VERSION ""

NS_ :

BS_:

BU_: Turbocharger OnBoardDataLogger OffBoardDiagnosticTool2 OffBoardDiagnosticTool1 FileServer ParkingBrakeController SeatControl2 FanDriveController SteeringColumnUnit CommunicationUnitRadio CommunicationUnitSatellite CommunicationUnitCellular PropulsionBatteryCharger ChassisController2 ChassisController1 EngineValveControl AuxiliaryHeater2 AuxiliaryHeater1 ClutchUnit RampControl InformationSystem1 SuspensionSystemController2 OilSensor VehicleDynamicStability ExhaustEmissionController TransmissionDisplay2 TransmissionDisplay1 ClimateControl2 WaterPumpController RearAxleSteeringController LightingOperatorControl SeatController1 IgnitionController2 IgnitionController1 TirePressureController CabController2 CabController1 PneumaticSystemController SuspensionSystemController1 HydraulicPumpController EnduranceBrakingSystem RetarderExhaustEngine2 OnBoardDiagnosticUnit HeadwayController RetarderExhaustEngine1 CabDisplay1 ManagementComputer VirtualTerminal OffVehicleGateway PowerTakeOffFront HitchControl AuxiliaryValveControl BodyController TractorTrailerBridge1 StarterSystem ElectricalSystem VehicleSecurity VehicleNavigation AerodynamicControl ElectricalChargingSystem ClimateControl1 TripRecorder InstrumentCluster SuspensionDriveAxle2 SuspensionDriveAxle1 SuspensionSteerAxle SteeringController FuelSystem CruiseControl RetarderDriveline RetarderEngine BrakesDriveAxle2 BrakesDriveAxle1 BrakesSystemController BrakesSteerAxle AxleDrive2 AxleDrive1 AxleSteering PowerTakeOff ShiftConsoleSecondary ShiftConsolePrimary Transmission2 Transmission1 Engine2 Engine1

BO_ 2365479678 ASC1: 8 Vector__XXX
 SG_ SpeedDependantLevelCtrlStatus : 54|2@1+ (1,0) [0|3] "" Vector__XXX
 SG_ MemoryLevel : 60|4@1+ (1,0) [0|15] "" Vector__XXX
 SG_ AllwLvelCtrlDuringBrakingStatus : 52|2@1+ (1,0) [0|3] "" Vector__XXX
 SG_ SspensionCtrlRefusalInformation : 56|4@1+ (1,0) [0|15] "" Vector__XXX
 SG_ SuspensionRemoteCtrl2 : 50|2@1+ (1,0) [0|3] "" Vector__XXX
 SG_ SuspensionRemoteCtrl1 : 48|2@1+ (1,0) [0|3] "" Vector__XXX
 SG_ RearAxleInBumperRange : 42|2@1+ (1,0) [0|3] "" Vector__XXX
 SG_ FrontAxleInBumperRange : 40|2@1+ (1,0) [0|3] "" Vector__XXX
 SG_ DoorRelease : 36|2@1+ (1,0) [0|3] "" Vector__XXX
 SG_ VehicleMotionInhibit : 34|2@1+ (1,0) [0|3] "" Vector__XXX
 SG_ SecurityDevice : 32|2@1+ (1,0) [0|3] "" Vector__XXX
 SG_ LevelCtrlMode : 28|4@1+ (1,0) [0|15] "" Vector__XXX
 SG_ KneelingInformation : 24|4@1+ (1,0) [0|15] "" Vector__XXX
 SG_ LiftingCtrlModeRearAxle : 22|2@1+ (1,0) [0|3] "" Vector__XXX
 SG_ LiftingCtrlModeFrontAxle : 20|2@1+ (1,0) [0|3] "" Vector__XXX
 SG_ LoweringCtrlModeRearAxle : 18|2@1+ (1,0) [0|3] "" Vector__XXX
 SG_ LoweringCtrlModeFrontAxle : 16|2@1+ (1,0) [0|3] "" Vector__XXX
 SG_ AboveNominalLevelRearAxle : 14|2@1+ (1,0) [0|3] "" Vector__XXX
 SG_ AboveNominalLevelFrontAxle : 12|2@1+ (1,0) [0|3] "" Vector__XXX
 SG_ BelowNominalLevelRearAxle : 10|2@1+ (1,0) [0|3] "" Vector__XXX
 SG_ BelowNominalLevelFrontAxle : 8|2@1+ (1,0) [0|3] "" Vector__XXX
 SG_ NominalLevelRearAxle : 4|4@1+ (1,0) [0|15] "" Vector__XXX
 SG_ NominalLevelFrontAxle : 0|4@1+ (1,0) [0|15] "" Vector__XXX
 SG_ LiftAxle2Pos : 46|2@1+ (1,0) [0|3] "" Vector__XXX
 SG_ LiftAxle1Pos : 38|2@1+ (1,0) [0|3] "" Vector__XXX

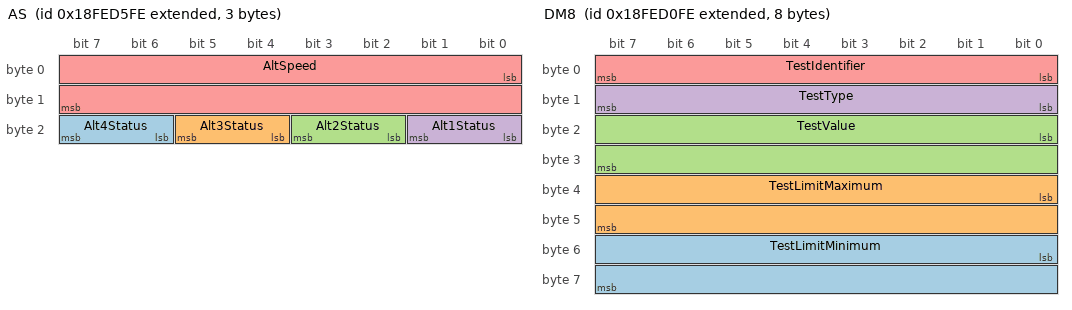
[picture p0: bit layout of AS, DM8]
BO_ 2566837758 AS: 3 Vector__XXX
 SG_ Alt4Status : 22|2@1+ (1,0) [0|3] "" Vector__XXX
 SG_ Alt3Status : 20|2@1+ (1,0) [0|3] "" Vector__XXX
 SG_ Alt2Status : 18|2@1+ (1,0) [0|3] "" Vector__XXX
 SG_ Alt1Status : 16|2@1+ (1,0) [0|3] "" Vector__XXX
 SG_ AltSpeed : 0|16@1+ (0.5,0) [0|32127.5] "rpm" Vector__XXX

BO_ 2633922558 AP: 8 Vector__XXX
 SG_ AuxAbsPressReading : 32|16@1+ (0.5,0) [0|32127.5] "kPa" Vector__XXX
 SG_ AuxGagePressReading1 : 16|16@1+ (0.5,0) [0|32127.5] "kPa" Vector__XXX
 SG_ AuxVacuumPressReading : 0|16@1+ (0.5,0) [0|32127.5] "kPa" Vector__XXX

BO_ 2566775038 AMB2: 8 Vector__XXX
 SG_ SpecificHumidity : 16|16@1+ (0.01,0) [0|642.55] "g/kg" Vector__XXX
 SG_ SolarSensorMax : 8|8@1+ (0.4,0) [0|100] "mW/cm/cm" Vector__XXX
 SG_ SolarIntensityPercent : 0|8@1+ (0.4,0) [0|100] "%" Vector__XXX

BO_ 2566836478 DM8: 8 Vector__XXX
 SG_ TestLimitMinimum : 48|16@1+ (1,0) [0|64255] "" Vector__XXX
 SG_ TestLimitMaximum : 32|16@1+ (1,0) [0|64255] "" Vector__XXX
 SG_ TestValue : 16|16@1+ (1,0) [0|64255] "" Vector__XXX
 SG_ TestType : 8|8@1+ (1,0) [1|64] "" Vector__XXX
 SG_ TestIdentifier : 0|8@1+ (1,0) [1|64] "" Vector__XXX

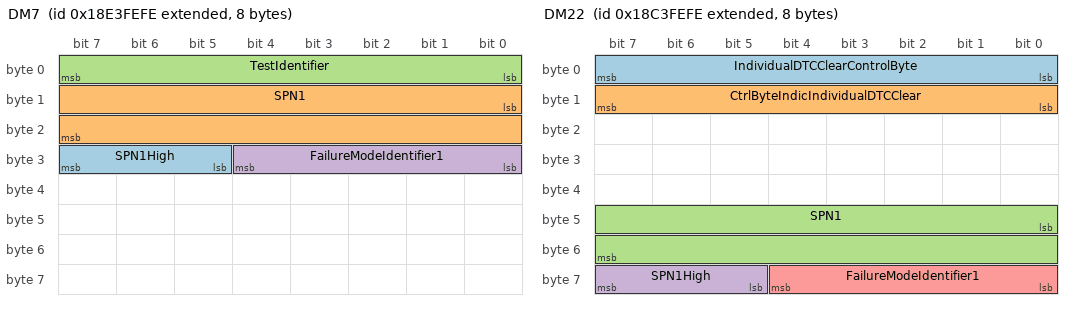
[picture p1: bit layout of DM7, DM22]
BO_ 2565078782 DM7: 8 Vector__XXX
 SG_ SPN1High : 29|3@1+ (1,0) [0|7] "" Vector__XXX
 SG_ SPN1 : 8|16@1+ (1,0) [0|65536] "" Vector__XXX
 SG_ TestIdentifier : 0|8@1+ (1,0) [1|64] "" Vector__XXX
 SG_ FailureModeIdentifier1 : 24|5@1+ (1,0) [0|0] "" Vector__XXX

BO_ 2566835966 DM5: 8 Vector__XXX
 SG_ BoostPressureControlSystemStatus : 57|1@1- (1,0) [0|0] "" Vector__XXX
 SG_ DieselParticulateFilterStatus : 58|1@1- (1,0) [0|0] "" Vector__XXX
 SG_ NOxConvertingCatalystAdsorberSta : 59|1@1- (1,0) [0|0] "" Vector__XXX
 SG_ NMHCConvertingCatalystStatus : 60|1@1- (1,0) [0|0] "" Vector__XXX
 SG_ BoostPressureControlSystemSuppor : 41|1@1- (1,0) [0|0] "" Vector__XXX
 SG_ DieselParticulateFilterSupport : 42|1@1- (1,0) [0|0] "" Vector__XXX
 SG_ NOxConvertingCatalystAdsorberSup : 43|1@1- (1,0) [0|0] "" Vector__XXX
 SG_ NMHCConvertingCatalystSupport : 44|1@1- (1,0) [0|0] "" Vector__XXX
 SG_ MisfireMonitoringSupport : 24|1@1+ (1,0) [0|0] "" Vector__XXX
 SG_ OBDCompliance : 16|8@1+ (1,0) [0|240] "" Vector__XXX
 SG_ PreviouslyActiveTroubleCodes : 8|8@1+ (1,0) [0|240] "" Vector__XXX
 SG_ ActiveTroubleCodes : 0|8@1+ (1,0) [0|240] "" Vector__XXX
 SG_ SecondAirSystemMonStatus : 51|1@1+ (1,0) [0|1] "" Vector__XXX
 SG_ EvaporativeSystemMonStatus : 50|1@1+ (1,0) [0|1] "" Vector__XXX
 SG_ ACSystemRefrigerantMonStatus : 52|1@1+ (1,0) [0|1] "" Vector__XXX
 SG_ OxygenSensorHeaterMonStatus : 54|1@1+ (1,0) [0|1] "" Vector__XXX
 SG_ OxygenSensorMonStatus : 53|1@1+ (1,0) [0|1] "" Vector__XXX
 SG_ EGRSystemMonitoringStatus : 55|1@1+ (1,0) [0|1] "" Vector__XXX
 SG_ CatalystMonStatus : 48|1@1+ (1,0) [0|1] "" Vector__XXX
 SG_ ColdStartAidSystemMonStatus : 56|1@1+ (1,0) [0|1] "" Vector__XXX
 SG_ HeatedCatalystMonStatus : 49|1@1+ (1,0) [0|0] "" Vector__XXX
 SG_ CatalystMonSupp : 32|1@1+ (1,0) [0|1] "" Vector__XXX
 SG_ ColdStartAidSystemMonSupp : 40|1@1+ (1,0) [0|1] "" Vector__XXX
 SG_ HeatedCatalystMonSupp : 33|1@1+ (1,0) [0|0] "" Vector__XXX
 SG_ EvaporativeSystemMonSupp : 34|1@1+ (1,0) [0|1] "" Vector__XXX
 SG_ SecondAirSystemMonSupp : 35|1@1+ (1,0) [0|1] "" Vector__XXX
 SG_ ACSystemRefrigerantMonSupp : 36|1@1+ (1,0) [0|1] "" Vector__XXX
 SG_ OxygenSensorMonSupp : 37|1@1+ (1,0) [0|1] "" Vector__XXX
 SG_ OxygenSensorHeaterMonSupp : 38|1@1+ (1,0) [0|1] "" Vector__XXX
 SG_ EGRSystemMonitoringSupp : 39|1@1+ (1,0) [0|1] "" Vector__XXX
 SG_ MisfireMonitoringStatus : 28|1@1+ (1,0) [0|0] "" Vector__XXX
 SG_ ComprehensiveCompMonStatus : 30|1@1+ (1,0) [0|1] "" Vector__XXX
 SG_ FuelSystemMonitoringStatus : 29|1@1+ (1,0) [0|1] "" Vector__XXX
 SG_ ComprehensiveComponentMonSupp : 26|1@1+ (1,0) [0|0] "" Vector__XXX
 SG_ FuelSystemMonitoringSupport : 25|1@1+ (1,0) [0|1] "" Vector__XXX

BO_ 2566835454 DM3: 0 Vector__XXX

BO_ 2562981630 DM22: 8 Vector__XXX
 SG_ IndividualDTCClearControlByte : 0|8@1+ (1,0) [0|255] "" Vector__XXX
 SG_ CtrlByteIndicIndividualDTCClear : 8|8@1+ (1,0) [0|255] "" Vector__XXX
 SG_ SPN1 : 40|16@1+ (1,0) [0|65536] "" Vector__XXX
 SG_ SPN1High : 61|3@1+ (1,0) [0|7] "" Vector__XXX
 SG_ FailureModeIdentifier1 : 56|5@1+ (1,0) [0|0] "" Vector__XXX

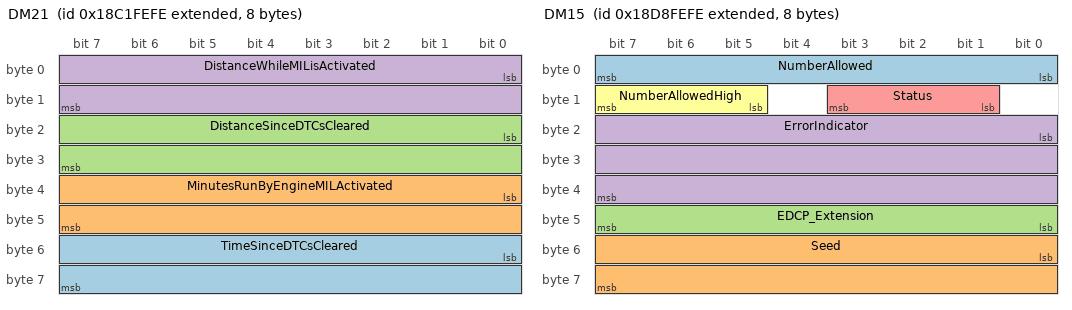
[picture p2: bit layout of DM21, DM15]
BO_ 2562850558 DM21: 8 Vector__XXX
 SG_ TimeSinceDTCsCleared : 48|16@1+ (1,0) [0|64255] "mins" Vector__XXX
 SG_ MinutesRunByEngineMILActivated : 32|16@1+ (1,0) [0|64255] "mins" Vector__XXX
 SG_ DistanceSinceDTCsCleared : 16|16@1+ (1,0) [0|64255] "km" Vector__XXX
 SG_ DistanceWhileMILisActivated : 0|16@1+ (1,0) [0|64255] "km" Vector__XXX

BO_ 2564226814 DM17: 1 Vector__XXX
 SG_ BootLoadData : 0|8@1- (1,0) [0|0] "" Vector__XXX

BO_ 2564292350 DM16: 2 Vector__XXX
 SG_ RawBinaryData : 8|8@1- (1,0) [0|0] "" Vector__XXX
 SG_ NumberOfOccurance : 0|8@1+ (1,0) [0|0] "" Vector__XXX

BO_ 2564357886 DM15: 8 Vector__XXX
 SG_ NumberAllowed : 0|8@1+ (1,0) [0|2047] "" Vector__XXX
 SG_ Seed : 48|16@1+ (1,0) [0|65535] "" Vector__XXX
 SG_ EDCP_Extension : 40|8@1+ (1,0) [0|255] "" Vector__XXX
 SG_ ErrorIndicator : 16|24@1+ (1,0) [0|16777215] "" Vector__XXX
 SG_ Status : 9|3@1+ (1,0) [0|7] "" Vector__XXX
 SG_ NumberAllowedHigh : 13|3@1+ (1,0) [0|7] "" Vector__XXX

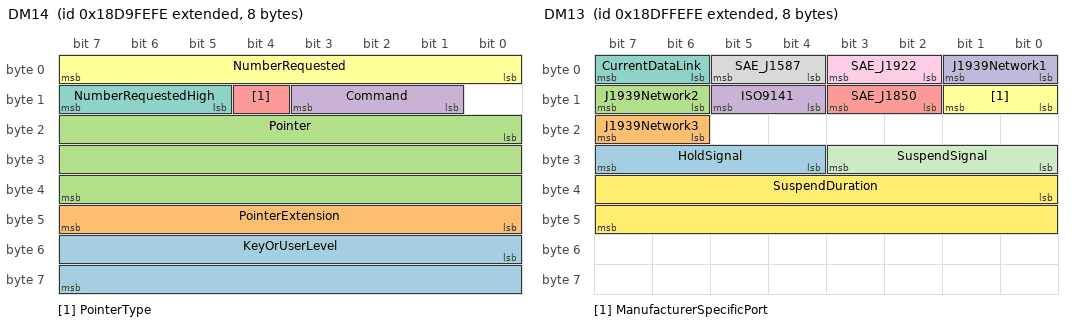
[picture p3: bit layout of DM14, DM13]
BO_ 2564423422 DM14: 8 Vector__XXX
 SG_ KeyOrUserLevel : 48|16@1+ (1,0) [0|65535] "" Vector__XXX
 SG_ PointerExtension : 40|8@1+ (1,0) [0|255] "" Vector__XXX
 SG_ Pointer : 16|24@1+ (1,0) [0|16777215] "" Vector__XXX
 SG_ Command : 9|3@1+ (1,0) [0|7] "" Vector__XXX
 SG_ PointerType : 12|1@1+ (1,0) [0|1] "" Vector__XXX
 SG_ NumberRequested : 0|8@1+ (1,0) [0|2047] "" Vector__XXX
 SG_ NumberRequestedHigh : 13|3@1+ (1,0) [0|7] "" Vector__XXX

BO_ 2564816638 DM13: 8 Vector__XXX
 SG_ HoldSignal : 28|4@1+ (1,0) [0|15] "" Vector__XXX
 SG_ J1939Network3 : 22|2@1+ (1,0) [0|3] "" Vector__XXX
 SG_ J1939Network2 : 14|2@1+ (1,0) [0|3] "" Vector__XXX
 SG_ ISO9141 : 12|2@1+ (1,0) [0|3] "" Vector__XXX
 SG_ SAE_J1850 : 10|2@1+ (1,0) [0|3] "" Vector__XXX
 SG_ ManufacturerSpecificPort : 8|2@1+ (1,0) [0|3] "" Vector__XXX
 SG_ CurrentDataLink : 6|2@1+ (1,0) [0|3] "" Vector__XXX
 SG_ SAE_J1587 : 4|2@1+ (1,0) [0|3] "" Vector__XXX
 SG_ SAE_J1922 : 2|2@1+ (1,0) [0|3] "" Vector__XXX
 SG_ J1939Network1 : 0|2@1+ (1,0) [0|3] "" Vector__XXX
 SG_ SuspendSignal : 24|4@1+ (1,0) [0|15] "" Vector__XXX
 SG_ SuspendDuration : 32|16@1+ (1,0) [0|64255] "sec" Vector__XXX

BO_ 2566837246 DM11: 0 Vector__XXX

BO_ 2566836990 DM10: 8 Vector__XXX
 SG_ TestIdentifierSupported : 0|64@1+ (1,0) [1|1.844674407371E+019] "" Vector__XXX

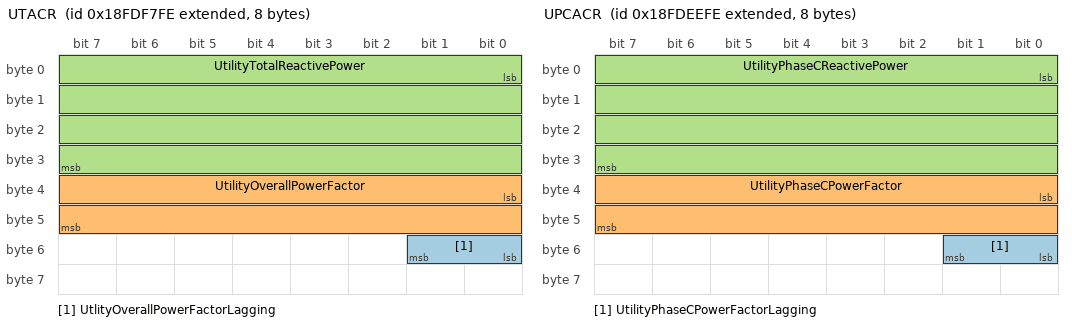
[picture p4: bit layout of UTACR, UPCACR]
BO_ 2566780926 UTACR: 8 Vector__XXX
 SG_ UtlityOverallPowerFactorLagging : 48|2@1+ (1,0) [0|3] "" Vector__XXX
 SG_ UtilityOverallPowerFactor : 32|16@1+ (1,-1) [-1|2.92181] "" Vector__XXX
 SG_ UtilityTotalReactivePower : 0|32@1+ (1,-2000000000) [-2000000000|2211081215] "VAr" Vector__XXX

BO_ 2566781182 UTACP: 8 Vector__XXX
 SG_ UtilityTotalApparentPower : 32|32@1+ (1,-2000000000) [-2000000000|2211081215] "VA" Vector__XXX
 SG_ UtilityTotalRealPower : 0|32@1+ (1,-2000000000) [-2000000000|2211081215] "W" Vector__XXX

BO_ 2566778366 UTACE: 8 Vector__XXX
 SG_ UtilityTotalKWHoursImport : 32|32@1+ (1,0) [0|4211081215] "kWh" Vector__XXX
 SG_ UtilityTotalKWHoursExport : 0|32@1+ (1,0) [0|4211081215] "kWh" Vector__XXX

BO_ 2566778622 UPCACR: 8 Vector__XXX
 SG_ UtilityPhaseCPowerFactorLagging : 48|2@1+ (1,0) [0|3] "" Vector__XXX
 SG_ UtilityPhaseCPowerFactor : 32|16@1+ (1,-1) [-1|2.92181] "" Vector__XXX
 SG_ UtilityPhaseCReactivePower : 0|32@1+ (1,-2000000000) [-2000000000|2211081215] "VAr" Vector__XXX

BO_ 2566778878 UPCACP: 8 Vector__XXX
 SG_ UtilityPhaseCApparentPower : 32|32@1+ (1,-2000000000) [-2000000000|2211081215] "VA" Vector__XXX
 SG_ UtilityPhaseCRealPower : 0|32@1+ (1,-2000000000) [-2000000000|2211081215] "W" Vector__XXX

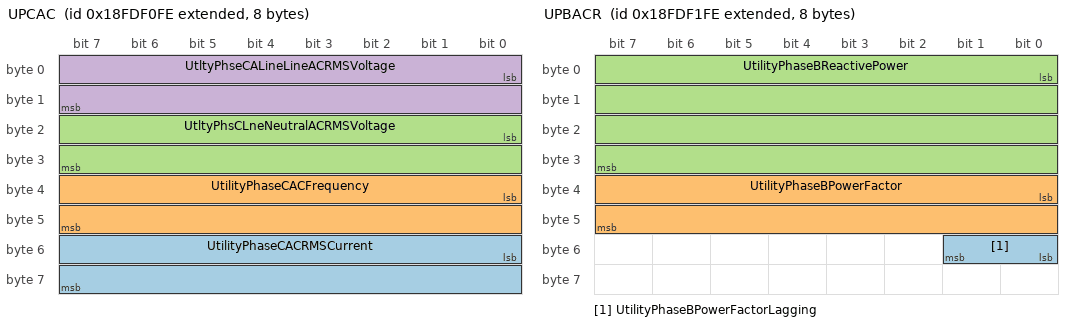
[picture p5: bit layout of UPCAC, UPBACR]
BO_ 2566779134 UPCAC: 8 Vector__XXX
 SG_ UtilityPhaseCACRMSCurrent : 48|16@1+ (1,0) [0|64255] "A" Vector__XXX
 SG_ UtilityPhaseCACFrequency : 32|16@1+ (1,0) [0|501.9921875] "Hz" Vector__XXX
 SG_ UtltyPhsCLneNeutralACRMSVoltage : 16|16@1+ (1,0) [0|64255] "V" Vector__XXX
 SG_ UtltyPhseCALineLineACRMSVoltage : 0|16@1+ (1,0) [0|64255] "V" Vector__XXX

BO_ 2566779390 UPBACR: 8 Vector__XXX
 SG_ UtilityPhaseBPowerFactorLagging : 48|2@1+ (1,0) [0|3] "" Vector__XXX
 SG_ UtilityPhaseBPowerFactor : 32|16@1+ (1,-1) [-1|2.92181] "" Vector__XXX
 SG_ UtilityPhaseBReactivePower : 0|32@1+ (1,-2000000000) [-2000000000|2211081215] "VAr" Vector__XXX

BO_ 2566779646 UPBACP: 8 Vector__XXX
 SG_ UtilityPhaseBApparentPower : 32|32@1+ (1,-2000000000) [-2000000000|2211081215] "VA" Vector__XXX
 SG_ UtilityPhaseBRealPower : 0|32@1+ (1,-2000000000) [-2000000000|2211081215] "W" Vector__XXX

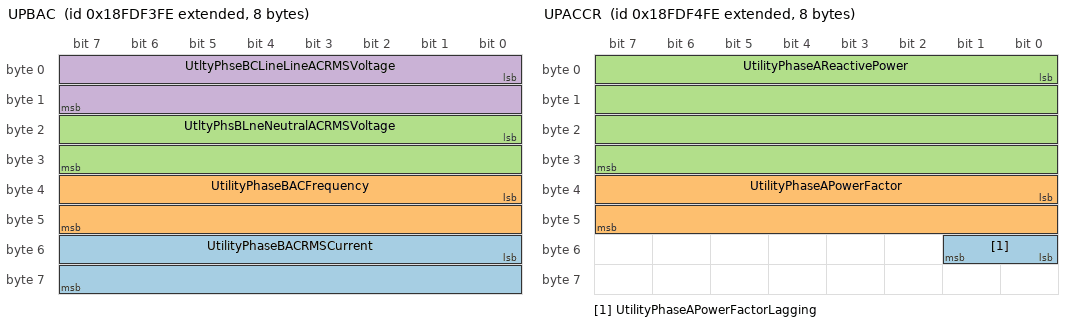
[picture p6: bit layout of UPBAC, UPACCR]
BO_ 2566779902 UPBAC: 8 Vector__XXX
 SG_ UtilityPhaseBACRMSCurrent : 48|16@1+ (1,0) [0|64255] "A" Vector__XXX
 SG_ UtilityPhaseBACFrequency : 32|16@1+ (1,0) [0|501.9921875] "Hz" Vector__XXX
 SG_ UtltyPhsBLneNeutralACRMSVoltage : 16|16@1+ (1,0) [0|64255] "V" Vector__XXX
 SG_ UtltyPhseBCLineLineACRMSVoltage : 0|16@1+ (1,0) [0|64255] "V" Vector__XXX

BO_ 2566780158 UPACCR: 8 Vector__XXX
 SG_ UtilityPhaseAPowerFactorLagging : 48|2@1+ (1,0) [0|3] "" Vector__XXX
 SG_ UtilityPhaseAPowerFactor : 32|16@1+ (1,-1) [-1|2.92181] "" Vector__XXX
 SG_ UtilityPhaseAReactivePower : 0|32@1+ (1,-2000000000) [-2000000000|2211081215] "VAr" Vector__XXX

BO_ 2566780414 UPAACP: 8 Vector__XXX
 SG_ UtilityPhaseAApparentPower : 32|32@1+ (1,-2000000000) [-2000000000|2211081215] "VA" Vector__XXX
 SG_ UtilityPhaseARealPower : 0|32@1+ (1,-2000000000) [-2000000000|2211081215] "W" Vector__XXX

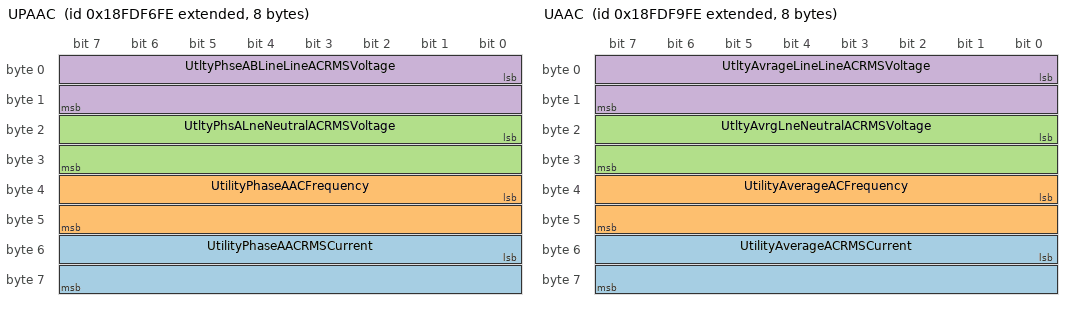
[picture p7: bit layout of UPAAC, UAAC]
BO_ 2566780670 UPAAC: 8 Vector__XXX
 SG_ UtilityPhaseAACRMSCurrent : 48|16@1+ (1,0) [0|64255] "A" Vector__XXX
 SG_ UtilityPhaseAACFrequency : 32|16@1+ (1,0) [0|501.9921875] "Hz" Vector__XXX
 SG_ UtltyPhsALneNeutralACRMSVoltage : 16|16@1+ (1,0) [0|64255] "V" Vector__XXX
 SG_ UtltyPhseABLineLineACRMSVoltage : 0|16@1+ (1,0) [0|64255] "V" Vector__XXX

BO_ 2566781438 UAAC: 8 Vector__XXX
 SG_ UtilityAverageACRMSCurrent : 48|16@1+ (1,0) [0|64255] "A" Vector__XXX
 SG_ UtilityAverageACFrequency : 32|16@1+ (1,0) [0|501.9921875] "Hz" Vector__XXX
 SG_ UtltyAvrgLneNeutralACRMSVoltage : 16|16@1+ (1,0) [0|64255] "V" Vector__XXX
 SG_ UtltyAvrageLineLineACRMSVoltage : 0|16@1+ (1,0) [0|64255] "V" Vector__XXX

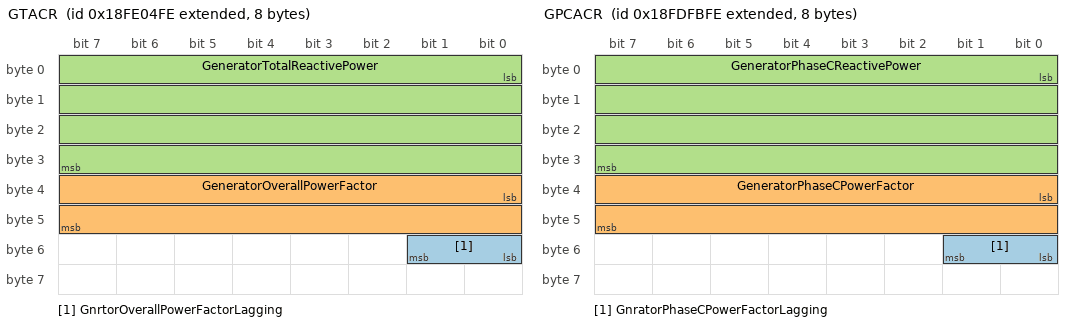
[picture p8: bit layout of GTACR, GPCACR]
BO_ 2566784254 GTACR: 8 Vector__XXX
 SG_ GnrtorOverallPowerFactorLagging : 48|2@1+ (1,0) [0|3] "" Vector__XXX
 SG_ GeneratorOverallPowerFactor : 32|16@1+ (1,-1) [-1|2.92181] "" Vector__XXX
 SG_ GeneratorTotalReactivePower : 0|32@1+ (1,-2000000000) [-2000000000|2211081215] "VAr" Vector__XXX

BO_ 2566784510 GTACP: 8 Vector__XXX
 SG_ GeneratorTotalApparentPower : 32|32@1+ (1,-2000000000) [-2000000000|2211081215] "VA" Vector__XXX
 SG_ GeneratorTotalRealPower : 0|32@1+ (1,-2000000000) [-2000000000|2211081215] "W" Vector__XXX

BO_ 2566781694 GTACE: 8 Vector__XXX
 SG_ GeneratorTotalKWHoursImport : 32|32@1+ (1,0) [0|4211081215] "kWh" Vector__XXX
 SG_ GeneratorTotalKWHoursExport : 0|32@1+ (1,0) [0|4211081215] "kWh" Vector__XXX

BO_ 2566781950 GPCACR: 8 Vector__XXX
 SG_ GnratorPhaseCPowerFactorLagging : 48|2@1+ (1,0) [0|3] "" Vector__XXX
 SG_ GeneratorPhaseCPowerFactor : 32|16@1+ (1,-1) [-1|2.92181] "" Vector__XXX
 SG_ GeneratorPhaseCReactivePower : 0|32@1+ (1,-2000000000) [-2000000000|2211081215] "VAr" Vector__XXX

BO_ 2566782206 GPCACP: 8 Vector__XXX
 SG_ GeneratorPhaseCApparentPower : 32|32@1+ (1,-2000000000) [-2000000000|2211081215] "VA" Vector__XXX
 SG_ GeneratorPhaseCRealPower : 0|32@1+ (1,-2000000000) [-2000000000|2211081215] "W" Vector__XXX

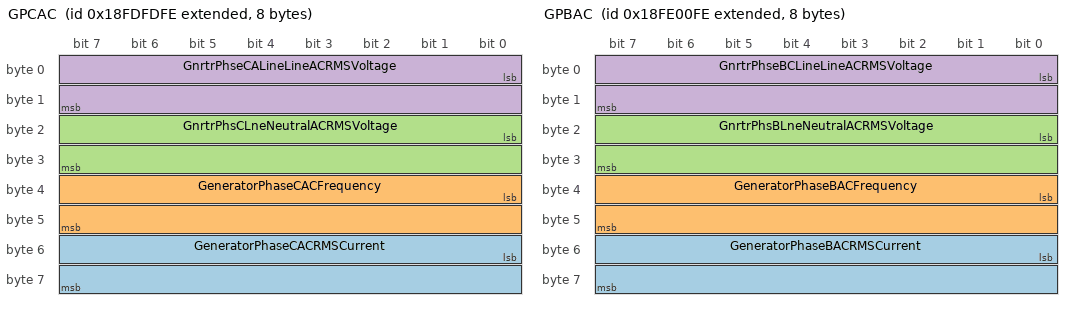
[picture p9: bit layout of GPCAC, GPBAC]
BO_ 2566782462 GPCAC: 8 Vector__XXX
 SG_ GeneratorPhaseCACRMSCurrent : 48|16@1+ (1,0) [0|64255] "A" Vector__XXX
 SG_ GeneratorPhaseCACFrequency : 32|16@1+ (1,0) [0|501.9921875] "Hz" Vector__XXX
 SG_ GnrtrPhsCLneNeutralACRMSVoltage : 16|16@1+ (1,0) [0|64255] "V" Vector__XXX
 SG_ GnrtrPhseCALineLineACRMSVoltage : 0|16@1+ (1,0) [0|64255] "V" Vector__XXX

BO_ 2566782718 GPBACRP: 8 Vector__XXX
 SG_ GnratorPhaseBPowerFactorLagging : 48|2@1+ (1,0) [0|3] "" Vector__XXX
 SG_ GeneratorPhaseBPowerFactor : 32|16@1+ (1,-1) [-1|2.92181] "" Vector__XXX
 SG_ GeneratorPhaseBReactivePower : 0|32@1+ (1,-2000000000) [-2000000000|2211081215] "VAr" Vector__XXX

BO_ 2566782974 GPBACP: 8 Vector__XXX
 SG_ GeneratorPhaseBApparentPower : 32|32@1+ (1,-2000000000) [-2000000000|2211081215] "VA" Vector__XXX
 SG_ GeneratorPhaseBRealPower : 0|32@1+ (1,-2000000000) [-2000000000|2211081215] "W" Vector__XXX

BO_ 2566783230 GPBAC: 8 Vector__XXX
 SG_ GeneratorPhaseBACRMSCurrent : 48|16@1+ (1,0) [0|64255] "A" Vector__XXX
 SG_ GeneratorPhaseBACFrequency : 32|16@1+ (1,0) [0|501.9921875] "Hz" Vector__XXX
 SG_ GnrtrPhsBLneNeutralACRMSVoltage : 16|16@1+ (1,0) [0|64255] "V" Vector__XXX
 SG_ GnrtrPhseBCLineLineACRMSVoltage : 0|16@1+ (1,0) [0|64255] "V" Vector__XXX

BO_ 2566783486 GPAACR: 8 Vector__XXX
 SG_ GnratorPhaseAPowerFactorLagging : 48|2@1+ (1,0) [0|3] "" Vector__XXX
 SG_ GeneratorPhaseAPowerFactor : 32|16@1+ (1,-1) [-1|2.92181] "" Vector__XXX
 SG_ GeneratorPhaseAReactivePower : 0|32@1+ (1,-2000000000) [-2000000000|2211081215] "VAr" Vector__XXX

BO_ 2566783742 GPAACP: 8 Vector__XXX
 SG_ GeneratorPhaseAApparentPower : 32|32@1+ (1,-2000000000) [-2000000000|2211081215] "VA" Vector__XXX
 SG_ GeneratorPhaseARealPower : 0|32@1+ (1,-2000000000) [-2000000000|2211081215] "W" Vector__XXX

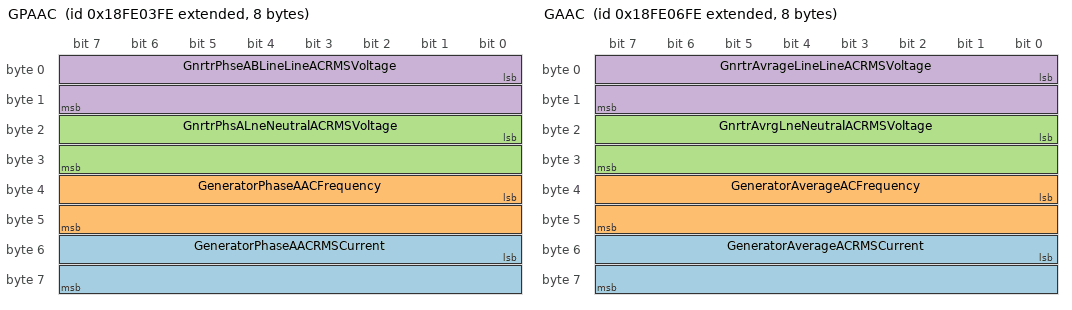
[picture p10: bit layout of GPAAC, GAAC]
BO_ 2566783998 GPAAC: 8 Vector__XXX
 SG_ GeneratorPhaseAACRMSCurrent : 48|16@1+ (1,0) [0|64255] "A" Vector__XXX
 SG_ GeneratorPhaseAACFrequency : 32|16@1+ (1,0) [0|501.9921875] "Hz" Vector__XXX
 SG_ GnrtrPhsALneNeutralACRMSVoltage : 16|16@1+ (1,0) [0|64255] "V" Vector__XXX
 SG_ GnrtrPhseABLineLineACRMSVoltage : 0|16@1+ (1,0) [0|64255] "V" Vector__XXX

BO_ 2566784766 GAAC: 8 Vector__XXX
 SG_ GeneratorAverageACRMSCurrent : 48|16@1+ (1,0) [0|64255] "A" Vector__XXX
 SG_ GeneratorAverageACFrequency : 32|16@1+ (1,0) [0|501.9921875] "Hz" Vector__XXX
 SG_ GnrtrAvrgLneNeutralACRMSVoltage : 16|16@1+ (1,0) [0|64255] "V" Vector__XXX
 SG_ GnrtrAvrageLineLineACRMSVoltage : 0|16@1+ (1,0) [0|64255] "V" Vector__XXX

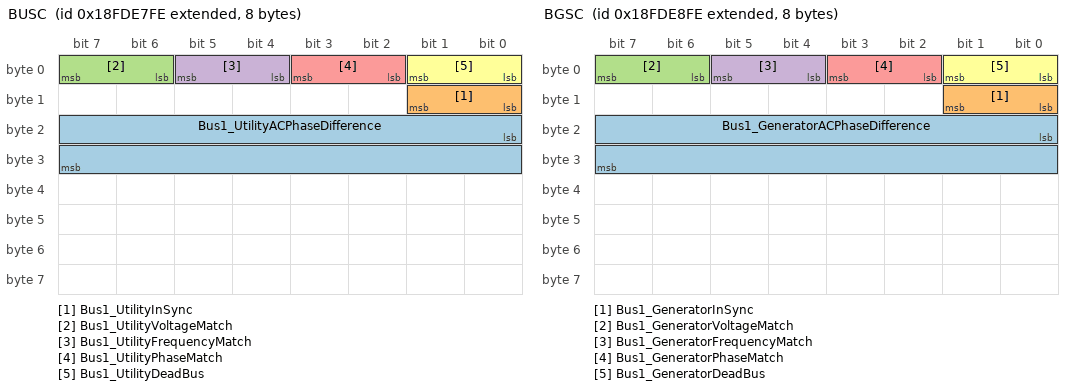
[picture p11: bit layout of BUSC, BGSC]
BO_ 2566776830 BUSC: 8 Vector__XXX
 SG_ Bus1_UtilityACPhaseDifference : 16|16@1+ (1,-200) [-200|301.99] "deg" Vector__XXX
 SG_ Bus1_UtilityInSync : 8|2@1+ (1,0) [0|3] "" Vector__XXX
 SG_ Bus1_UtilityVoltageMatch : 6|2@1+ (1,0) [0|3] "" Vector__XXX
 SG_ Bus1_UtilityFrequencyMatch : 4|2@1+ (1,0) [0|3] "" Vector__XXX
 SG_ Bus1_UtilityPhaseMatch : 2|2@1+ (1,0) [0|3] "" Vector__XXX
 SG_ Bus1_UtilityDeadBus : 0|2@1+ (1,0) [0|3] "" Vector__XXX

BO_ 2566777342 BPCAC: 8 Vector__XXX
 SG_ Bus1PhaseCACFrequency : 32|16@1+ (1,0) [0|501.9921875] "Hz" Vector__XXX
 SG_ Bs1PhseCLineNeutralACRMSVoltage : 16|16@1+ (1,0) [0|64255] "V" Vector__XXX
 SG_ Bus1PhaseCALineLineACRMSVoltage : 0|16@1+ (1,0) [0|64255] "V" Vector__XXX

BO_ 2566777598 BPBAC: 8 Vector__XXX
 SG_ Bus1PhaseBACFrequency : 32|16@1+ (1,0) [0|501.9921875] "Hz" Vector__XXX
 SG_ Bs1PhseBLineNeutralACRMSVoltage : 16|16@1+ (1,0) [0|64255] "V" Vector__XXX
 SG_ Bus1PhaseBCLineLineACRMSVoltage : 0|16@1+ (1,0) [0|64255] "V" Vector__XXX

BO_ 2566777854 BPAAC: 8 Vector__XXX
 SG_ Bus1PhaseAACFrequency : 32|16@1+ (1,0) [0|501.9921875] "Hz" Vector__XXX
 SG_ Bs1PhseALineNeutralACRMSVoltage : 16|16@1+ (1,0) [0|64255] "V" Vector__XXX
 SG_ Bus1PhaseABLineLineACRMSVoltage : 0|16@1+ (1,0) [0|64255] "V" Vector__XXX

BO_ 2566777086 BGSC: 8 Vector__XXX
 SG_ Bus1_GeneratorACPhaseDifference : 16|16@1+ (1,-200) [-200|301.99] "deg" Vector__XXX
 SG_ Bus1_GeneratorInSync : 8|2@1+ (1,0) [0|3] "" Vector__XXX
 SG_ Bus1_GeneratorVoltageMatch : 6|2@1+ (1,0) [0|3] "" Vector__XXX
 SG_ Bus1_GeneratorFrequencyMatch : 4|2@1+ (1,0) [0|3] "" Vector__XXX
 SG_ Bus1_GeneratorPhaseMatch : 2|2@1+ (1,0) [0|3] "" Vector__XXX
 SG_ Bus1_GeneratorDeadBus : 0|2@1+ (1,0) [0|3] "" Vector__XXX

BO_ 2566778110 BAAC: 8 Vector__XXX
 SG_ Bus1AverageACFrequency : 32|16@1+ (1,0) [0|501.9921875] "Hz" Vector__XXX
 SG_ Bs1AvrgeLineNeutralACRMSVoltage : 16|16@1+ (1,0) [0|64255] "V" Vector__XXX
 SG_ Bus1AverageLineLineACRMSVoltage : 0|16@1+ (1,0) [0|64255] "V" Vector__XXX

BO_ 2633895422 WSMSTR: 8 Vector__XXX
 SG_ NumberOfMembers : 0|8@1+ (1,0) [0|0] "" Vector__XXX

BO_ 2563440382 XFER: 8 Vector__XXX
 SG_ ShrtNameOfActualReportingDevice : 32|32@1+ (1,0) [0|0] "(2^32 - 1)" Vector__XXX
 SG_ LengthOfDataForTheReportedPGN : 24|8@1+ (1,0) [0|255] "" Vector__XXX
 SG_ PGNofRequstedInformation : 0|24@1+ (1,0) [0|16777215] "" Vector__XXX

BO_ 2632711934 TPDT: 8 Vector__XXX
 SG_ SequenceNumber : 0|8@1+ (1,0) [0|255] "" Vector__XXX

BO_ 2632777470 TPCM: 8 Vector__XXX
 SG_ TotalNumberOfPacketsEoMA m19 : 24|8@1+ (1,0) [0|255] "" Vector__XXX
 SG_ TotalMessageSizeEoMA m19 : 8|16@1+ (1,0) [0|64255] "counts" Vector__XXX
 SG_ TotalMessageSizeBAM m32 : 8|16@1+ (1,0) [0|64255] "counts" Vector__XXX
 SG_ TotalNumberOfPacketsBAM m32 : 24|8@1+ (1,0) [0|255] "" Vector__XXX
 SG_ ConnectionAbortReason m255 : 8|8@1+ (1,0) [0|255] "" Vector__XXX
 SG_ NextPacketNumberToBeSent m17 : 16|8@1+ (1,0) [0|255] "" Vector__XXX
 SG_ NumberOfPacketsThatCanBeSent m17 : 8|8@1+ (1,0) [0|255] "" Vector__XXX
 SG_ PGNumber : 40|24@1+ (1,0) [0|16777200] "" Vector__XXX
 SG_ MaximumNumberOfPackets m16 : 32|8@1+ (1,0) [0|255] "" Vector__XXX
 SG_ TotalNumberOfPackets m16 : 24|8@1+ (1,0) [0|255] "" Vector__XXX
 SG_ TotalMessageSize m16 : 8|16@1+ (1,0) [0|64255] "counts" Vector__XXX
 SG_ ControlByte M : 0|8@1+ (1,0) [0|255] "" Vector__XXX

BO_ 2563374846 RQST2: 8 Vector__XXX
 SG_ UseTransferMode : 24|2@1+ (1,0) [0|3] "" Vector__XXX
 SG_ ParameterGroupNumber : 0|24@1+ (1,0) [0|16777215] "" Vector__XXX

BO_ 2565537534 RQST: 3 Vector__XXX
 SG_ ParameterGroupNumber : 0|24@1+ (1,0) [0|16777215] "" Vector__XXX

BO_ 2499635966 AGW: 8 Vector__XXX
 SG_ AxleGroupWeight : 8|16@1+ (2,0) [0|128510] "kg" Vector__XXX
 SG_ AxleGroupLocation : 0|4@1+ (1,0) [0|15] "" Vector__XXX

BO_ 2633853438 AGCW: 8 Vector__XXX
 SG_ AxleGroupLocation : 4|4@1+ (1,0) [0|15] "" Vector__XXX
 SG_ AxleGroupFullWeightCalib : 24|16@1+ (2,0) [0|128510] "kg" Vector__XXX
 SG_ AxleGroupEmptyWeightCalib : 8|16@1+ (2,0) [0|128510] "kg" Vector__XXX

BO_ 2432520702 ACCVC: 8 Vector__XXX
 SG_ DsrdAftrcoolerCoolantIntakeTemp : 8|8@1+ (1,-40) [-40|210] "deg C" Vector__XXX
 SG_ DsrdAftrclrClntThrmostatOpening : 16|8@1+ (0.4,0) [0|100] "%" Vector__XXX
 SG_ AftrcoolerCoolantThermostatMode : 0|2@1+ (1,0) [0|3] "" Vector__XXX

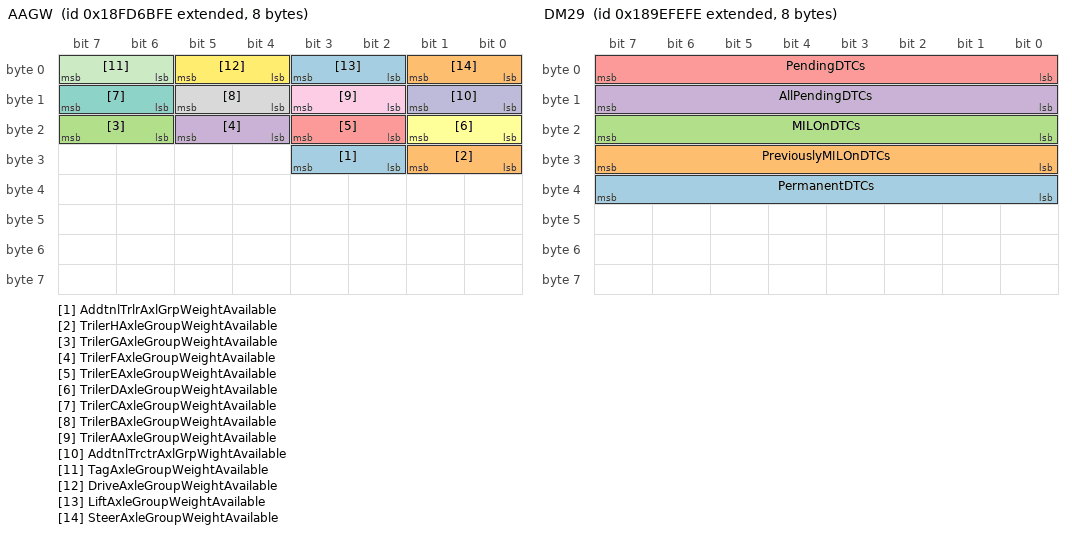
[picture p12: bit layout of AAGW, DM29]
BO_ 2566745086 AAGW: 8 Vector__XXX
 SG_ AddtnlTrlrAxlGrpWeightAvailable : 26|2@1+ (1,0) [0|3] "" Vector__XXX
 SG_ TrilerHAxleGroupWeightAvailable : 24|2@1+ (1,0) [0|3] "" Vector__XXX
 SG_ TrilerGAxleGroupWeightAvailable : 22|2@1+ (1,0) [0|3] "" Vector__XXX
 SG_ TrilerFAxleGroupWeightAvailable : 20|2@1+ (1,0) [0|3] "" Vector__XXX
 SG_ TrilerEAxleGroupWeightAvailable : 18|2@1+ (1,0) [0|3] "" Vector__XXX
 SG_ TrilerDAxleGroupWeightAvailable : 16|2@1+ (1,0) [0|3] "" Vector__XXX
 SG_ TrilerCAxleGroupWeightAvailable : 14|2@1+ (1,0) [0|3] "" Vector__XXX
 SG_ TrilerBAxleGroupWeightAvailable : 12|2@1+ (1,0) [0|3] "" Vector__XXX
 SG_ TrilerAAxleGroupWeightAvailable : 10|2@1+ (1,0) [0|3] "" Vector__XXX
 SG_ AddtnlTrctrAxlGrpWightAvailable : 8|2@1+ (1,0) [0|3] "" Vector__XXX
 SG_ TagAxleGroupWeightAvailable : 6|2@1+ (1,0) [0|3] "" Vector__XXX
 SG_ DriveAxleGroupWeightAvailable : 4|2@1+ (1,0) [0|3] "" Vector__XXX
 SG_ LiftAxleGroupWeightAvailable : 2|2@1+ (1,0) [0|3] "" Vector__XXX
 SG_ SteerAxleGroupWeightAvailable : 0|2@1+ (1,0) [0|3] "" Vector__XXX

BO_ 2566744062 ZNVW: 8 Vector__XXX
 SG_ ZeroNetVehicleWeightChange : 0|2@1+ (1,0) [0|3] "" Vector__XXX

BO_ 2499630078 EAI: 8 Vector__XXX
 SG_ EngExhaustGasTempAverageBank2 : 32|16@1+ (0.03125,-273) [-273|1734.96875] "deg C" Vector__XXX
 SG_ EngExhaustGasTempAverageBank1 : 16|16@1+ (0.03125,-273) [-273|1734.96875] "deg C" Vector__XXX
 SG_ EngExhaustGasTempAverage : 0|16@1+ (0.03125,-273) [-273|1734.96875] "deg C" Vector__XXX

BO_ 2560556798 DM29: 8 Vector__XXX
 SG_ PermanentDTCs : 32|8@1+ (1,0) [0|255] "" Vector__XXX
 SG_ PreviouslyMILOnDTCs : 24|8@1+ (1,0) [0|255] "" Vector__XXX
 SG_ MILOnDTCs : 16|8@1+ (1,0) [0|255] "" Vector__XXX
 SG_ AllPendingDTCs : 8|8@1+ (1,0) [0|255] "" Vector__XXX
 SG_ PendingDTCs : 0|8@1+ (1,0) [0|255] "" Vector__XXX

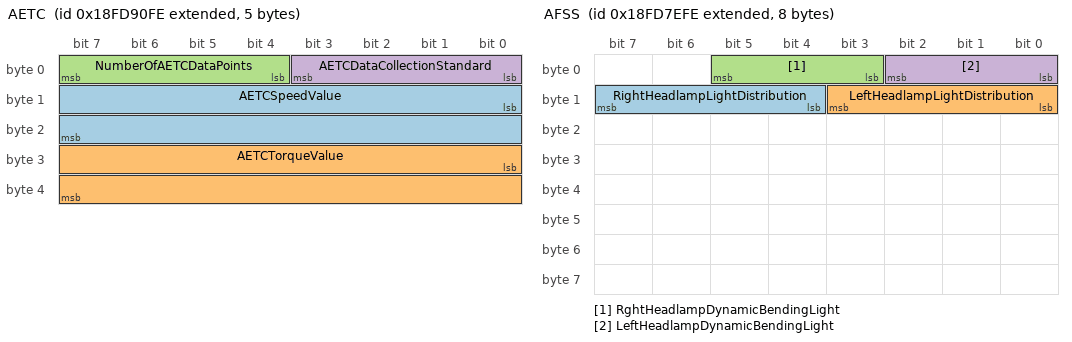
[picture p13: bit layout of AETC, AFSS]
BO_ 2566754558 AETC: 5 Vector__XXX
 SG_ AETCSpeedValue : 8|16@1- (1,0) [0|8031.875] "rpm" Vector__XXX
 SG_ AETCTorqueValue : 24|16@1+ (1,0) [0|64255] "Nm" Vector__XXX
 SG_ NumberOfAETCDataPoints : 4|4@1+ (1,0) [0|15] "" Vector__XXX
 SG_ AETCDataCollectionStandard : 0|4@1+ (1,0) [0|15] "" Vector__XXX

BO_ 2566749950 AFSS: 8 Vector__XXX
 SG_ RightHeadlampLightDistribution : 12|4@1+ (1,0) [0|15] "" Vector__XXX
 SG_ LeftHeadlampLightDistribution : 8|4@1+ (1,0) [0|15] "" Vector__XXX
 SG_ RghtHeadlampDynamicBendingLight : 3|3@1+ (1,0) [0|7] "" Vector__XXX
 SG_ LeftHeadlampDynamicBendingLight : 0|3@1+ (1,0) [0|7] "" Vector__XXX

BO_ 2566838782 AUXIO1: 8 Vector__XXX
 SG_ AuxI_O16 : 24|2@1+ (1,0) [0|3] "" Vector__XXX
 SG_ AuxI_O15 : 26|2@1+ (1,0) [0|3] "" Vector__XXX
 SG_ AuxI_O14 : 28|2@1+ (1,0) [0|3] "" Vector__XXX
 SG_ AuxI_O13 : 30|2@1+ (1,0) [0|3] "" Vector__XXX
 SG_ AuxI_O12 : 16|2@1+ (1,0) [0|3] "" Vector__XXX
 SG_ AuxI_O11 : 18|2@1+ (1,0) [0|3] "" Vector__XXX
 SG_ AuxI_O10 : 20|2@1+ (1,0) [0|3] "" Vector__XXX
 SG_ AuxI_O09 : 22|2@1+ (1,0) [0|3] "" Vector__XXX
 SG_ AuxI_O08 : 8|2@1+ (1,0) [0|3] "" Vector__XXX
 SG_ AuxI_O07 : 10|2@1+ (1,0) [0|3] "" Vector__XXX
 SG_ AuxI_O06 : 12|2@1+ (1,0) [0|3] "" Vector__XXX
 SG_ AuxI_O05 : 14|2@1+ (1,0) [0|3] "" Vector__XXX
 SG_ AuxI_O04 : 0|2@1+ (1,0) [0|3] "" Vector__XXX
 SG_ AuxI_O03 : 2|2@1+ (1,0) [0|3] "" Vector__XXX
 SG_ AuxI_O02 : 4|2@1+ (1,0) [0|3] "" Vector__XXX
 SG_ AuxI_O01 : 6|2@1+ (1,0) [0|3] "" Vector__XXX
 SG_ AuxI_OChannel2 : 48|16@1+ (1,0) [0|64255] "counts" Vector__XXX
 SG_ AuxI_OChannel1 : 32|16@1+ (1,0) [0|64255] "counts" Vector__XXX

BO_ 2561146622 AUXIO2: 8 Vector__XXX
 SG_ AuxI_O45 : 62|2@1+ (1,0) [0|3] "" Vector__XXX
 SG_ AuxI_O46 : 60|2@1+ (1,0) [0|3] "" Vector__XXX
 SG_ AuxI_O47 : 58|2@1+ (1,0) [0|3] "" Vector__XXX
 SG_ AuxI_O48 : 56|2@1+ (1,0) [0|3] "" Vector__XXX
 SG_ AuxI_O41 : 54|2@1+ (1,0) [0|3] "" Vector__XXX
 SG_ AuxI_O42 : 52|2@1+ (1,0) [0|3] "" Vector__XXX
 SG_ AuxI_O43 : 50|2@1+ (1,0) [0|3] "" Vector__XXX
 SG_ AuxI_O44 : 48|2@1+ (1,0) [0|3] "" Vector__XXX
 SG_ AuxI_O37 : 46|2@1+ (1,0) [0|3] "" Vector__XXX
 SG_ AuxI_O38 : 44|2@1+ (1,0) [0|3] "" Vector__XXX
 SG_ AuxI_O39 : 42|2@1+ (1,0) [0|3] "" Vector__XXX
 SG_ AuxI_O40 : 40|2@1+ (1,0) [0|3] "" Vector__XXX
 SG_ AuxI_O33 : 38|2@1+ (1,0) [0|3] "" Vector__XXX
 SG_ AuxI_O34 : 36|2@1+ (1,0) [0|3] "" Vector__XXX
 SG_ AuxI_O35 : 34|2@1+ (1,0) [0|3] "" Vector__XXX
 SG_ AuxI_O36 : 32|2@1+ (1,0) [0|3] "" Vector__XXX
 SG_ AuxI_O29 : 30|2@1+ (1,0) [0|3] "" Vector__XXX
 SG_ AuxI_O30 : 28|2@1+ (1,0) [0|3] "" Vector__XXX
 SG_ AuxI_O31 : 26|2@1+ (1,0) [0|3] "" Vector__XXX
 SG_ AuxI_O32 : 24|2@1+ (1,0) [0|3] "" Vector__XXX
 SG_ AuxI_O25 : 22|2@1+ (1,0) [0|3] "" Vector__XXX
 SG_ AuxI_O26 : 20|2@1+ (1,0) [0|3] "" Vector__XXX
 SG_ AuxI_O27 : 18|2@1+ (1,0) [0|3] "" Vector__XXX
 SG_ AuxI_O28 : 16|2@1+ (1,0) [0|3] "" Vector__XXX
 SG_ AuxI_O21 : 14|2@1+ (1,0) [0|3] "" Vector__XXX
 SG_ AuxI_O22 : 12|2@1+ (1,0) [0|3] "" Vector__XXX
 SG_ AuxI_O23 : 10|2@1+ (1,0) [0|3] "" Vector__XXX
 SG_ AuxI_O24 : 8|2@1+ (1,0) [0|3] "" Vector__XXX
 SG_ AuxI_O17 : 6|2@1+ (1,0) [0|3] "" Vector__XXX
 SG_ AuxI_O18 : 4|2@1+ (1,0) [0|3] "" Vector__XXX
 SG_ AuxI_O19 : 2|2@1+ (1,0) [0|3] "" Vector__XXX
 SG_ AuxI_O20 : 0|2@1+ (1,0) [0|3] "" Vector__XXX

BO_ 2561081086 AUXIO3: 8 Vector__XXX
 SG_ AuxI_O77 : 62|2@1+ (1,0) [0|3] "" Vector__XXX
 SG_ AuxI_O78 : 60|2@1+ (1,0) [0|3] "" Vector__XXX
 SG_ AuxI_O79 : 58|2@1+ (1,0) [0|3] "" Vector__XXX
 SG_ AuxI_O80 : 56|2@1+ (1,0) [0|3] "" Vector__XXX
 SG_ AuxI_O73 : 54|2@1+ (1,0) [0|3] "" Vector__XXX
 SG_ AuxI_O74 : 52|2@1+ (1,0) [0|3] "" Vector__XXX
 SG_ AuxI_O75 : 50|2@1+ (1,0) [0|3] "" Vector__XXX
 SG_ AuxI_O76 : 48|2@1+ (1,0) [0|3] "" Vector__XXX
 SG_ AuxI_O69 : 46|2@1+ (1,0) [0|3] "" Vector__XXX
 SG_ AuxI_O70 : 44|2@1+ (1,0) [0|3] "" Vector__XXX
 SG_ AuxI_O71 : 42|2@1+ (1,0) [0|3] "" Vector__XXX
 SG_ AuxI_O72 : 40|2@1+ (1,0) [0|3] "" Vector__XXX
 SG_ AuxI_O65 : 38|2@1+ (1,0) [0|3] "" Vector__XXX
 SG_ AuxI_O66 : 36|2@1+ (1,0) [0|3] "" Vector__XXX
 SG_ AuxI_O67 : 34|2@1+ (1,0) [0|3] "" Vector__XXX
 SG_ AuxI_O68 : 32|2@1+ (1,0) [0|3] "" Vector__XXX
 SG_ AuxI_O61 : 30|2@1+ (1,0) [0|3] "" Vector__XXX
 SG_ AuxI_O62 : 28|2@1+ (1,0) [0|3] "" Vector__XXX
 SG_ AuxI_O63 : 26|2@1+ (1,0) [0|3] "" Vector__XXX
 SG_ AuxI_O64 : 24|2@1+ (1,0) [0|3] "" Vector__XXX
 SG_ AuxI_O57 : 22|2@1+ (1,0) [0|3] "" Vector__XXX
 SG_ AuxI_O58 : 20|2@1+ (1,0) [0|3] "" Vector__XXX
 SG_ AuxI_O59 : 18|2@1+ (1,0) [0|3] "" Vector__XXX
 SG_ AuxI_O60 : 16|2@1+ (1,0) [0|3] "" Vector__XXX
 SG_ AuxI_O53 : 14|2@1+ (1,0) [0|3] "" Vector__XXX
 SG_ AuxI_O54 : 12|2@1+ (1,0) [0|3] "" Vector__XXX
 SG_ AuxI_O55 : 10|2@1+ (1,0) [0|3] "" Vector__XXX
 SG_ AuxI_O56 : 8|2@1+ (1,0) [0|3] "" Vector__XXX
 SG_ AuxI_O49 : 6|2@1+ (1,0) [0|3] "" Vector__XXX
 SG_ AuxI_O50 : 4|2@1+ (1,0) [0|3] "" Vector__XXX
 SG_ AuxI_O51 : 2|2@1+ (1,0) [0|3] "" Vector__XXX
 SG_ AuxI_O52 : 0|2@1+ (1,0) [0|3] "" Vector__XXX

BO_ 2561015550 AUXIO4: 8 Vector__XXX
 SG_ AuxI_O92 : 16|2@1+ (1,0) [0|3] "" Vector__XXX
 SG_ AuxI_O85 : 14|2@1+ (1,0) [0|3] "" Vector__XXX
 SG_ AuxI_O86 : 12|2@1+ (1,0) [0|3] "" Vector__XXX
 SG_ AuxI_O87 : 10|2@1+ (1,0) [0|3] "" Vector__XXX
 SG_ AuxI_O88 : 8|2@1+ (1,0) [0|3] "" Vector__XXX
 SG_ AuxI_O81 : 6|2@1+ (1,0) [0|3] "" Vector__XXX
 SG_ AuxI_O82 : 4|2@1+ (1,0) [0|3] "" Vector__XXX
 SG_ AuxI_O83 : 2|2@1+ (1,0) [0|3] "" Vector__XXX
 SG_ AuxI_O84 : 0|2@1+ (1,0) [0|3] "" Vector__XXX
 SG_ AuxI_O109 : 62|2@1+ (1,0) [0|3] "" Vector__XXX
 SG_ AuxI_O110 : 60|2@1+ (1,0) [0|3] "" Vector__XXX
 SG_ AuxI_O111 : 58|2@1+ (1,0) [0|3] "" Vector__XXX
 SG_ AuxI_O112 : 56|2@1+ (1,0) [0|3] "" Vector__XXX
 SG_ AuxI_O105 : 54|2@1+ (1,0) [0|3] "" Vector__XXX
 SG_ AuxI_O106 : 52|2@1+ (1,0) [0|3] "" Vector__XXX
 SG_ AuxI_O107 : 50|2@1+ (1,0) [0|3] "" Vector__XXX
 SG_ AuxI_O108 : 48|2@1+ (1,0) [0|3] "" Vector__XXX
 SG_ AuxI_O101 : 46|2@1+ (1,0) [0|3] "" Vector__XXX
 SG_ AuxI_O102 : 44|2@1+ (1,0) [0|3] "" Vector__XXX
 SG_ AuxI_O103 : 42|2@1+ (1,0) [0|3] "" Vector__XXX
 SG_ AuxI_O104 : 40|2@1+ (1,0) [0|3] "" Vector__XXX
 SG_ AuxI_O97 : 38|2@1+ (1,0) [0|3] "" Vector__XXX
 SG_ AuxI_O98 : 36|2@1+ (1,0) [0|3] "" Vector__XXX
 SG_ AuxI_O99 : 34|2@1+ (1,0) [0|3] "" Vector__XXX
 SG_ AuxI_O100 : 32|2@1+ (1,0) [0|3] "" Vector__XXX
 SG_ AuxI_O93 : 30|2@1+ (1,0) [0|3] "" Vector__XXX
 SG_ AuxI_O94 : 28|2@1+ (1,0) [0|3] "" Vector__XXX
 SG_ AuxI_O95 : 26|2@1+ (1,0) [0|3] "" Vector__XXX
 SG_ AuxI_O96 : 24|2@1+ (1,0) [0|3] "" Vector__XXX
 SG_ AuxI_O89 : 22|2@1+ (1,0) [0|3] "" Vector__XXX
 SG_ AuxI_O90 : 20|2@1+ (1,0) [0|3] "" Vector__XXX
 SG_ AuxI_O91 : 18|2@1+ (1,0) [0|3] "" Vector__XXX

BO_ 2566746622 BSA: 8 Vector__XXX
 SG_ TrailerBrakeStrokeAxle5Right : 57|3@1+ (1,0) [0|7] "" Vector__XXX
 SG_ TrailerBrakeStrokeAxle5Left : 54|3@1+ (1,0) [0|7] "" Vector__XXX
 SG_ TrailerBrakeStrokeAxle4Right : 51|3@1+ (1,0) [0|7] "" Vector__XXX
 SG_ TrailerBrakeStrokeAxle4Left : 48|3@1+ (1,0) [0|7] "" Vector__XXX
 SG_ TrailerBrakeStrokeAxle3Right : 45|3@1+ (1,0) [0|7] "" Vector__XXX
 SG_ TrailerBrakeStrokeAxle3Left : 42|3@1+ (1,0) [0|7] "" Vector__XXX
 SG_ TrailerBrakeStrokeAxle2Right : 39|3@1+ (1,0) [0|7] "" Vector__XXX
 SG_ TrailerBrakeStrokeAxle2Left : 36|3@1+ (1,0) [0|7] "" Vector__XXX
 SG_ TrailerBrakeStrokeAxle1Right : 33|3@1+ (1,0) [0|7] "" Vector__XXX
 SG_ TrailerBrakeStrokeAxle1Left : 30|3@1+ (1,0) [0|7] "" Vector__XXX
 SG_ TractorBrakeStrokeAxle5Right : 27|3@1+ (1,0) [0|7] "" Vector__XXX
 SG_ TractorBrakeStrokeAxle5Left : 24|3@1+ (1,0) [0|7] "" Vector__XXX
 SG_ TractorBrakeStrokeAxle4Right : 21|3@1+ (1,0) [0|7] "" Vector__XXX
 SG_ TractorBrakeStrokeAxle4Left : 18|3@1+ (1,0) [0|7] "" Vector__XXX
 SG_ TractorBrakeStrokeAxle3Right : 15|3@1+ (1,0) [0|7] "" Vector__XXX
 SG_ TractorBrakeStrokeAxle3Left : 12|3@1+ (1,0) [0|7] "" Vector__XXX
 SG_ TractorBrakeStrokeAxle2Right : 9|3@1+ (1,0) [0|7] "" Vector__XXX
 SG_ TractorBrakeStrokeAxle2Left : 6|3@1+ (1,0) [0|7] "" Vector__XXX
 SG_ TractorBrakeStrokeAxle1Right : 3|3@1+ (1,0) [0|7] "" Vector__XXX
 SG_ TractorBrakeStrokeAxle1Left : 0|3@1+ (1,0) [0|7] "" Vector__XXX

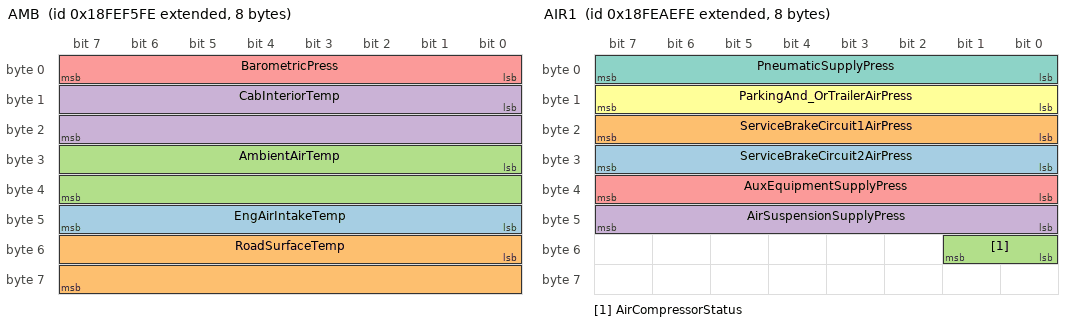
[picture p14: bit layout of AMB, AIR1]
BO_ 2566845950 AMB: 8 Vector__XXX
 SG_ EngAirIntakeTemp : 40|8@1+ (1,-40) [-40|210] "deg C" Vector__XXX
 SG_ RoadSurfaceTemp : 48|16@1+ (0.03125,-273) [-273|1734.96875] "deg C" Vector__XXX
 SG_ AmbientAirTemp : 24|16@1+ (0.03125,-273) [-273|1734.96875] "deg C" Vector__XXX
 SG_ CabInteriorTemp : 8|16@1+ (0.03125,-273) [-273|1734.96875] "deg C" Vector__XXX
 SG_ BarometricPress : 0|8@1+ (0.5,0) [0|125] "kPa" Vector__XXX

BO_ 2566840062 AIR2: 8 Vector__XXX
 SG_ EngAirStartPress : 0|8@1+ (4,0) [0|1000] "kPa" Vector__XXX

BO_ 2566827774 AIR1: 8 Vector__XXX
 SG_ ServiceBrakeCircuit2AirPress : 24|8@1+ (8,0) [0|2000] "kPa" Vector__XXX
 SG_ ServiceBrakeCircuit1AirPress : 16|8@1+ (8,0) [0|2000] "kPa" Vector__XXX
 SG_ AirCompressorStatus : 48|2@1+ (1,0) [0|3] "" Vector__XXX
 SG_ AirSuspensionSupplyPress : 40|8@1+ (8,0) [0|2000] "kPa" Vector__XXX
 SG_ AuxEquipmentSupplyPress : 32|8@1+ (8,0) [0|2000] "kPa" Vector__XXX
 SG_ ParkingAnd_OrTrailerAirPress : 8|8@1+ (8,0) [0|2000] "kPa" Vector__XXX
 SG_ PneumaticSupplyPress : 0|8@1+ (8,0) [0|2000] "kPa" Vector__XXX

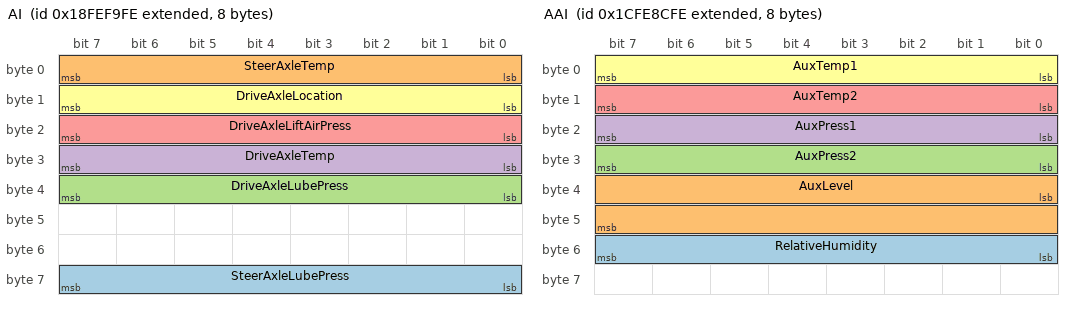
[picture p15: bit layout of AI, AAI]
BO_ 2566846974 AI: 8 Vector__XXX
 SG_ SteerAxleLubePress : 56|8@1+ (4,0) [0|1000] "kPa" Vector__XXX
 SG_ SteerAxleTemp : 0|8@1+ (1,-40) [-40|210] "deg C" Vector__XXX
 SG_ DriveAxleLubePress : 32|8@1+ (4,0) [0|1000] "kPa" Vector__XXX
 SG_ DriveAxleTemp : 24|8@1+ (1,-40) [-40|210] "deg C" Vector__XXX
 SG_ DriveAxleLiftAirPress : 16|8@1+ (4,0) [0|1000] "kPa" Vector__XXX
 SG_ DriveAxleLocation : 8|8@1+ (1,0) [0|255] "" Vector__XXX

BO_ 2633935614 AF2: 8 Vector__XXX
 SG_ EngTurboWastegateValvePos : 24|8@1+ (0.4,0) [0|100] "%" Vector__XXX
 SG_ EngGsMssFlwSnsrFelingCorrection : 32|8@1+ (1,-125) [-125|125] "%" Vector__XXX
 SG_ EngDsiredAbsIntakeManifoldPress : 8|16@1+ (0.1,0) [0|6425.5] "kPa" Vector__XXX
 SG_ EngGasFuelCorrectionFactor : 0|8@1+ (1,0) [0|250] "%" Vector__XXX

BO_ 2566803966 ACC2: 8 Vector__XXX
 SG_ ACCUsageDemand : 0|2@1+ (1,0) [0|3] "" Vector__XXX
 SG_ RqedACCDistanceMode : 5|3@1+ (1,0) [0|7] "" Vector__XXX

BO_ 2432593918 ACC1: 8 Vector__XXX
 SG_ ForwardCollisionWarning : 54|2@1+ (1,0) [0|3] "" Vector__XXX
 SG_ ACCDistanceAlertSignal : 52|2@1+ (1,0) [0|3] "" Vector__XXX
 SG_ ACCSystemShutoffWarning : 50|2@1+ (1,0) [0|3] "" Vector__XXX
 SG_ ACCTargetDetected : 48|2@1+ (1,0) [0|3] "" Vector__XXX
 SG_ RoadCurvature : 32|16@1+ (0.0078125,-250) [-250|251.992] "1/km" Vector__XXX
 SG_ AdptveCruiseCtrlSetDistanceMode : 27|3@1+ (1,0) [0|7] "" Vector__XXX
 SG_ AdaptiveCruiseCtrlMode : 24|3@1+ (1,0) [0|7] "" Vector__XXX
 SG_ AdaptiveCruiseCtrlSetSpeed : 16|8@1+ (1,0) [0|250] "km/h" Vector__XXX
 SG_ DistanceToForwardVehicle : 8|8@1+ (1,0) [0|250] "m" Vector__XXX
 SG_ SpeedOfForwardVehicle : 0|8@1+ (1,0) [0|250] "km/h" Vector__XXX

BO_ 2633935102 AC: 8 Vector__XXX
 SG_ ArticulationAngle : 0|8@1+ (1,-125) [-125|125] "deg" Vector__XXX

BO_ 2633927934 AAI: 8 Vector__XXX
 SG_ RelativeHumidity : 48|8@1+ (0.4,0) [0|100] "%" Vector__XXX
 SG_ AuxLevel : 32|16@1+ (0.1,0) [0|6425.5] "mm" Vector__XXX
 SG_ AuxPress2 : 24|8@1+ (16,0) [0|4000] "kPa" Vector__XXX
 SG_ AuxPress1 : 16|8@1+ (16,0) [0|4000] "kPa" Vector__XXX
 SG_ AuxTemp2 : 8|8@1+ (1,-40) [-40|210] "deg C" Vector__XXX
 SG_ AuxTemp1 : 0|8@1+ (1,-40) [-40|210] "deg C" Vector__XXX

BO_ 2566847998 A1: 8 Vector__XXX
 SG_ EngBlowerBypassValvePos : 0|8@1+ (0.4,0) [0|100] "%" Vector__XXX
 SG_ EngGasSupplyPress : 8|16@1+ (0.5,0) [0|32127.5] "kPa" Vector__XXX

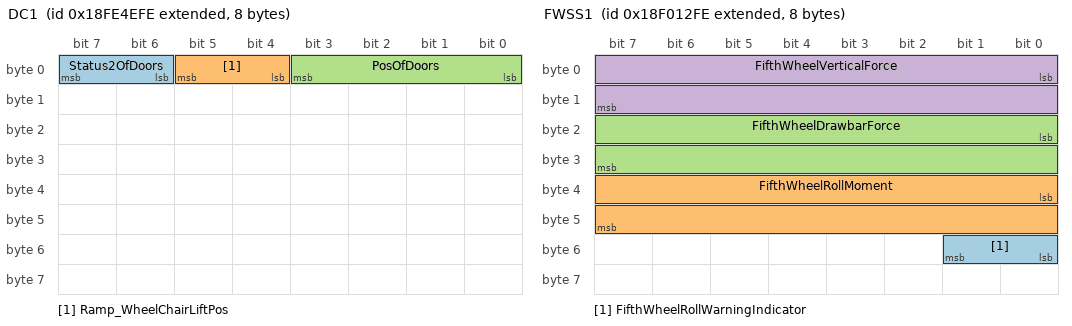
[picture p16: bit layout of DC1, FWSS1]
BO_ 2566803198 DC1: 8 Vector__XXX
 SG_ Status2OfDoors : 6|2@1+ (1,0) [0|3] "" Vector__XXX
 SG_ Ramp_WheelChairLiftPos : 4|2@1+ (1,0) [0|3] "" Vector__XXX
 SG_ PosOfDoors : 0|4@1+ (1,0) [0|15] "" Vector__XXX

BO_ 2565870334 FWSS1: 8 Vector__XXX
 SG_ FifthWheelRollWarningIndicator : 48|2@1+ (1,0) [0|3] "" Vector__XXX
 SG_ FifthWheelRollMoment : 32|16@1+ (10,-320000) [-320000|322550] "N" Vector__XXX
 SG_ FifthWheelDrawbarForce : 16|16@1+ (10,-320000) [-320000|322550] "N" Vector__XXX
 SG_ FifthWheelVerticalForce : 0|16@1+ (5,0) [0|321275] "N" Vector__XXX

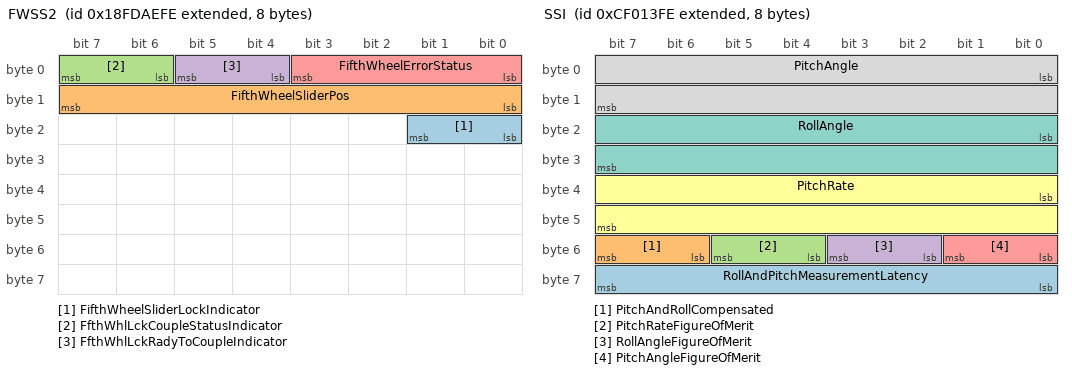
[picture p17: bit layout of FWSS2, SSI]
BO_ 2566762238 FWSS2: 8 Vector__XXX
 SG_ FifthWheelSliderLockIndicator : 16|2@1+ (1,0) [0|3] "" Vector__XXX
 SG_ FifthWheelSliderPos : 8|8@1+ (10,0) [0|2500] "mm" Vector__XXX
 SG_ FfthWhlLckCoupleStatusIndicator : 6|2@1+ (1,0) [0|3] "" Vector__XXX
 SG_ FfthWhlLckRadyToCoupleIndicator : 4|2@1+ (1,0) [0|3] "" Vector__XXX
 SG_ FifthWheelErrorStatus : 0|4@1+ (1,0) [0|15] "" Vector__XXX

BO_ 2364543998 SSI: 8 Vector__XXX
 SG_ RollAndPitchMeasurementLatency : 56|8@1+ (0.5,0) [0|125] "ms" Vector__XXX
 SG_ PitchAndRollCompensated : 54|2@1+ (1,0) [0|3] "" Vector__XXX
 SG_ PitchRateFigureOfMerit : 52|2@1+ (1,0) [0|3] "" Vector__XXX
 SG_ RollAngleFigureOfMerit : 50|2@1+ (1,0) [0|3] "" Vector__XXX
 SG_ PitchAngleFigureOfMerit : 48|2@1+ (1,0) [0|3] "" Vector__XXX
 SG_ PitchRate : 32|16@1+ (0.002,-64) [-64|64.51] "deg/sec" Vector__XXX
 SG_ RollAngle : 16|16@1+ (0.002,-64) [-64|64.51] "deg" Vector__XXX
 SG_ PitchAngle : 0|16@1+ (0.002,-64) [-64|64.51] "deg" Vector__XXX

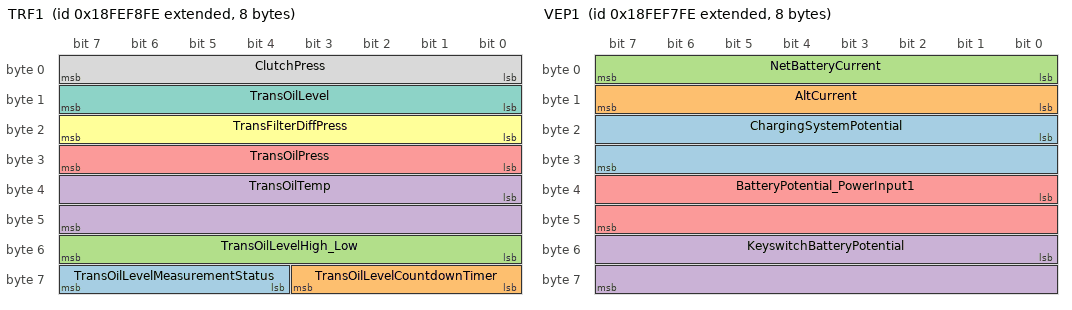
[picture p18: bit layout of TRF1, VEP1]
BO_ 2566846718 TRF1: 8 Vector__XXX
 SG_ TransOilLevelMeasurementStatus : 60|4@1+ (1,0) [0|15] "" Vector__XXX
 SG_ TransOilLevelCountdownTimer : 56|4@1+ (1,0) [0|15] "" Vector__XXX
 SG_ TransOilLevelHigh_Low : 48|8@1+ (0.5,-62.5) [-62.5|62.5] "L" Vector__XXX
 SG_ TransOilTemp : 32|16@1+ (0.03125,-273) [-273|1734.96875] "deg C" Vector__XXX
 SG_ TransOilPress : 24|8@1+ (16,0) [0|4000] "kPa" Vector__XXX
 SG_ TransFilterDiffPress : 16|8@1+ (2,0) [0|500] "kPa" Vector__XXX
 SG_ TransOilLevel : 8|8@1+ (0.4,0) [0|100] "%" Vector__XXX
 SG_ ClutchPress : 0|8@1+ (16,0) [0|4000] "kPa" Vector__XXX

BO_ 2566846462 VEP1: 8 Vector__XXX
 SG_ ChargingSystemPotential : 16|16@1+ (0.05,0) [0|3212.75] "V" Vector__XXX
 SG_ AltCurrent : 8|8@1+ (1,0) [0|250] "A" Vector__XXX
 SG_ NetBatteryCurrent : 0|8@1+ (1,-125) [-125|125] "A" Vector__XXX
 SG_ KeyswitchBatteryPotential : 48|16@1+ (0.05,0) [0|3212.75] "V" Vector__XXX
 SG_ BatteryPotential_PowerInput1 : 32|16@1+ (0.05,0) [0|3212.75] "V" Vector__XXX

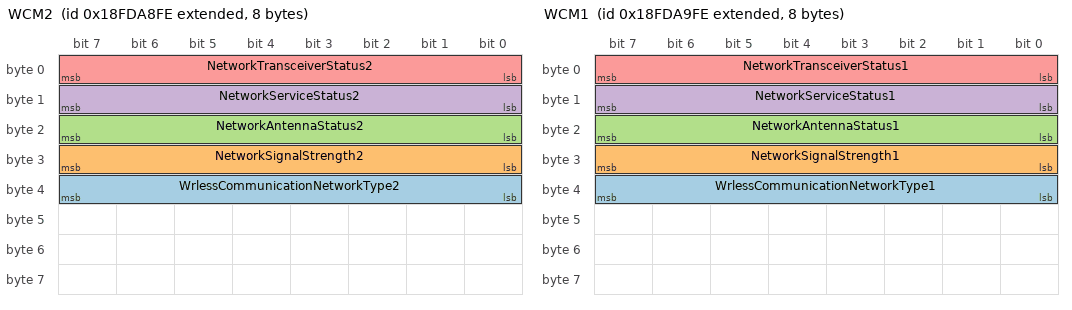
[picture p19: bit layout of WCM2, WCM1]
BO_ 2566760702 WCM2: 8 Vector__XXX
 SG_ WrlessCommunicationNetworkType2 : 32|8@1+ (1,0) [0|255] "" Vector__XXX
 SG_ NetworkSignalStrength2 : 24|8@1+ (0.4,0) [0|100] "%" Vector__XXX
 SG_ NetworkAntennaStatus2 : 16|8@1+ (1,0) [0|255] "" Vector__XXX
 SG_ NetworkServiceStatus2 : 8|8@1+ (1,0) [0|255] "" Vector__XXX
 SG_ NetworkTransceiverStatus2 : 0|8@1+ (1,0) [0|255] "" Vector__XXX

BO_ 2566760958 WCM1: 8 Vector__XXX
 SG_ WrlessCommunicationNetworkType1 : 32|8@1+ (1,0) [0|255] "" Vector__XXX
 SG_ NetworkSignalStrength1 : 24|8@1+ (0.4,0) [0|100] "%" Vector__XXX
 SG_ NetworkAntennaStatus1 : 16|8@1+ (1,0) [0|255] "" Vector__XXX
 SG_ NetworkServiceStatus1 : 8|8@1+ (1,0) [0|255] "" Vector__XXX
 SG_ NetworkTransceiverStatus1 : 0|8@1+ (1,0) [0|255] "" Vector__XXX

CM_ BO_ 2365479678 "Air Suspension Control 1";
CM_ SG_ 2365479678 SpeedDependantLevelCtrlStatus "This parameter indicates if the function Speed Dependant Level Control is active.";
CM_ SG_ 2365479678 MemoryLevel "Signal which indicates that the air suspension control has memory levels selected or stored.";
CM_ SG_ 2365479678 AllwLvelCtrlDuringBrakingStatus "This parameter indicates if the function Allow Level Control During Braking is active.";
CM_ SG_ 2365479678 SspensionCtrlRefusalInformation "Signal which indicates that the air suspension control cannot perform a request due to the operating conditions.";
CM_ SG_ 2365479678 SuspensionRemoteCtrl2 "Signal which indicates that the suspension system is controlled by remote control #2.";
CM_ SG_ 2365479678 SuspensionRemoteCtrl1 "Signal which indicates that the suspension system is controlled by remote control #1.";
CM_ SG_ 2365479678 RearAxleInBumperRange "Signal which indicates that the vehicle height at the rear axle (SPNs 1723 and 1724) is within the bumper range.";
CM_ SG_ 2365479678 FrontAxleInBumperRange "Signal which indicates that the vehicle height at the front axle (SPNs 1721 and 1722) is within the bumper range.";
CM_ SG_ 2365479678 DoorRelease "Signal which indicates that the doors may be opened.";
CM_ SG_ 2365479678 VehicleMotionInhibit "Signal which indicates whether vehicle motion is inhibited.";
CM_ SG_ 2365479678 SecurityDevice "The signal which indicates the status of the security device.";
CM_ SG_ 2365479678 LevelCtrlMode "Signal which indicates the actual control mode of the air suspension system";
CM_ SG_ 2365479678 KneelingInformation "Signal which indicates the actual level change in case of kneeling function";
CM_ SG_ 2365479678 LiftingCtrlModeRearAxle "Signal which indicates the actual lifting level change at the rear axle";
CM_ SG_ 2365479678 LiftingCtrlModeFrontAxle "Signal which indicates the actual lifting level change at the front axle";
CM_ SG_ 2365479678 LoweringCtrlModeRearAxle "Signal which indicates the actual lowering level change at the rear axle";
CM_ SG_ 2365479678 LoweringCtrlModeFrontAxle "Signal which indicates the actual lowering level change at the front axle";
CM_ SG_ 2365479678 AboveNominalLevelRearAxle "Signal which indicates whether the actual height of the rear axle is above the nominal (desired) level of the rear axle.";
CM_ SG_ 2365479678 AboveNominalLevelFrontAxle "Signal which indicates whether the actual height of the front axle is above the nominal (desired) level of the front axle.";
CM_ SG_ 2365479678 BelowNominalLevelRearAxle "Signal which indicates whether the actual height of the rear axle is below the nominal (desired) level for the rear axle.";
CM_ SG_ 2365479678 BelowNominalLevelFrontAxle "Signal which indicates whether the actual height of the front axle is below the nominal (desired) level for the front axle.";
CM_ SG_ 2365479678 NominalLevelRearAxle "Signal which indicates the nominal (desired) height of the rear axle to be controlled by the suspension system.";
CM_ SG_ 2365479678 NominalLevelFrontAxle "Signal which indicates the nominal (desired) height of the front axle to be controlled by the suspension system.";
CM_ SG_ 2365479678 LiftAxle2Pos "Signal which indicates the position / load condition of lift axle / tag axle #2.";
CM_ SG_ 2365479678 LiftAxle1Pos "Signal which indicates the position / load condition of lift axle / tag axle #1.";
CM_ BO_ 2566837758 "Alternator Information";
CM_ SG_ 2566837758 Alt4Status "Alternator 4 operating status.";
CM_ SG_ 2566837758 Alt3Status "Alternator 3 operating status.";
CM_ SG_ 2566837758 Alt2Status "Alternator 2 operating status.";
CM_ SG_ 2566837758 Alt1Status "Alternator 1 operating status.";
CM_ SG_ 2566837758 AltSpeed "Actual rotation speed of the alternator.";
CM_ BO_ 2633922558 "Auxiliary Pressures";
CM_ SG_ 2633922558 AuxAbsPressReading "Identifies the current absolute pressure (relative to 0 pressure) that is configured uniquely per application.";
CM_ SG_ 2633922558 AuxGagePressReading1 "Identifies the current gage pressure (relative to atmosphere) that is configured uniquely per application.";
CM_ SG_ 2633922558 AuxVacuumPressReading "Identifies the current vacuum pressure (relative to atmosphere) that is configured uniquely per application.";
CM_ BO_ 2566775038 "Ambient Conditions 2";
CM_ SG_ 2566775038 SpecificHumidity "Specific humidity of the ambient intake air.";
CM_ SG_ 2566775038 SolarSensorMax "This is the maximum value which can be reported by the sensor for the solar intensity.";
CM_ SG_ 2566775038 SolarIntensityPercent "This is the solar radiation (power density) falling on the vehicle in percent of the maximum sensor value (SPN 2611).";
CM_ BO_ 2566836478 "Test results for non-continously monitored systems.";
CM_ SG_ 2566836478 TestLimitMinimum "The threshold which the test value must be above to pass the test.";
CM_ SG_ 2566836478 TestLimitMaximum "The threshold which the test value must be below to pass the test.";
CM_ SG_ 2566836478 TestValue "The test value collected during the test.";
CM_ SG_ 2566836478 TestType "Identifies the non-continously monitored component identifier that was tested.";
CM_ SG_ 2566836478 TestIdentifier "Designates the test to be run.";
CM_ BO_ 2565078782 "Command non-continously monitored test";
CM_ SG_ 2565078782 SPN1High "SPN #1 (Conversion Version 4)";
CM_ SG_ 2565078782 SPN1 "SPN #1 (Conversion Version 4)";
CM_ SG_ 2565078782 TestIdentifier "Designates the test to be run.";
CM_ SG_ 2565078782 FailureModeIdentifier1 "The FMI defines the type of failure detected in the subsystem identified by an SPN.";
CM_ BO_ 2566835966 "Diagnostic readiness 1";
CM_ SG_ 2566835966 OBDCompliance "Identifies the OBD compliance capabilityof the responding controller.";
CM_ SG_ 2566835966 PreviouslyActiveTroubleCodes "Identifies the number of previously active trouble codes that are present in a specific controller.";
CM_ SG_ 2566835966 ActiveTroubleCodes "Identifies the number of active trouble codes that are present in a specific controller.";
CM_ BO_ 2566835454 "Diagnostic data clear/reset of previously active DTCs.";
CM_ BO_ 2562981630 "Individual Clear/Reset of active and previously active DTC.";
CM_ SG_ 2562981630 SPN1 "SPN #1 (Conversion Version 4)";
CM_ SG_ 2562981630 SPN1High "SPN #1 (Conversion Version 4)";
CM_ SG_ 2562981630 FailureModeIdentifier1 "The FMI defines the type of failure detected in the subsystem identified by an SPN.";
CM_ BO_ 2562850558 "Diagnostic readiness 2";
CM_ SG_ 2562850558 TimeSinceDTCsCleared "Time accumulated since DTCs were cleared (via an external test equipment or possibly, a battery disconnect) (SPN=?).";
CM_ SG_ 2562850558 MinutesRunByEngineMILActivated "Accumulated count (in minutes) while the MIL is activated (on) (SPN=?).";
CM_ SG_ 2562850558 DistanceSinceDTCsCleared "Distance accumulated since DTCs were cleared (SPN=?).";
CM_ SG_ 2562850558 DistanceWhileMILisActivated "The kilometers accumulated while the MIL is activated (SPN 3060).";
CM_ BO_ 2564226814 "Boot Load Data";
CM_ BO_ 2564292350 "Binary Data Transfer";
CM_ SG_ 2564292350 NumberOfOccurance "Number of occurance of raw binary data";
CM_ BO_ 2564357886 "Memory Access Response";
CM_ SG_ 2564357886 ErrorIndicator "Error Indicator/EDC Parameter";
CM_ BO_ 2564423422 "Memory Access Request";
CM_ SG_ 2564423422 KeyOrUserLevel "Key/User Level";
CM_ SG_ 2564423422 NumberRequested "Length/Number Requested";
CM_ SG_ 2564423422 NumberRequestedHigh "Length/Number Requested";
CM_ BO_ 2564816638 "Stop start broadcast";
CM_ SG_ 2564816638 HoldSignal "Indicator to all nodes that the communication ports that have been acted upon by the 'Stop start broadcast'
PGN are remaining in the modified state.";
CM_ SG_ 2564816638 J1939Network3 "Identifies the action to be performed on the SAE J1939 Network #3.";
CM_ SG_ 2564816638 J1939Network2 "Identifies the action to be performed on the SAE J1939 Network #2.";
CM_ SG_ 2564816638 ISO9141 "Identifies the action to be performed on the ISO9141 communications port.";
CM_ SG_ 2564816638 SAE_J1850 "Identifies the action to be performed on the SAE J1850 communications port.";
CM_ SG_ 2564816638 ManufacturerSpecificPort "Identifies the action to be performed on 'Other, manufacturer specific port' communications port.";
CM_ SG_ 2564816638 CurrentDataLink "Identifies the action to be performed on the communications port that this parameter was received.";
CM_ SG_ 2564816638 SAE_J1587 "Identifies the action to be performed on the SAE J1587 communications port.";
CM_ SG_ 2564816638 SAE_J1922 "Identifies the action to be performed on the SAE J1922 communications port.";
CM_ SG_ 2564816638 J1939Network1 "Identifies the action to be performed on the SAE J1939 Network #1, Primary vehicle communications port.";
CM_ BO_ 2566837246 "Diagnostic data clear/Reset for active DTCs";
CM_ BO_ 2566836990 "Non-continously monitored systems test identifiers support";
CM_ SG_ 2566836990 TestIdentifierSupported "Indicates the test identifiers that the controller supports.";
CM_ BO_ 2566780926 "Utility Total AC Reactive Power";
CM_ SG_ 2566780926 UtlityOverallPowerFactorLagging "Lead/lag status for utility incomer average power factor.";
CM_ SG_ 2566780926 UtilityOverallPowerFactor "The average power factor of the utility incomer.";
CM_ SG_ 2566780926 UtilityTotalReactivePower "The total reactive power delivered by the utility incomer";
CM_ BO_ 2566781182 "Utility Total AC Power";
CM_ SG_ 2566781182 UtilityTotalApparentPower "The total apparent power delivered by the utility incomer.";
CM_ SG_ 2566781182 UtilityTotalRealPower "Total real power delivered by the utility incomer.";
CM_ BO_ 2566778366 "Utility Total AC Energy";
CM_ SG_ 2566778366 UtilityTotalKWHoursImport "The total kilowatt-hours that have been imported by the utility incomer.";
CM_ SG_ 2566778366 UtilityTotalKWHoursExport "The total kilowatt-hours that have been exported by the utility incomer.";
CM_ BO_ 2566778622 "Utility Phase C AC Reactive Power";
CM_ SG_ 2566778622 UtilityPhaseCPowerFactorLagging "Lead/lag status for utility incomer phase C power factor.";
CM_ SG_ 2566778622 UtilityPhaseCPowerFactor "The power factor of phases C of the utility incomer.";
CM_ SG_ 2566778622 UtilityPhaseCReactivePower "The reactive power delivered by phase C of the utility incomer";
CM_ BO_ 2566778878 "Utility Phase C AC Power";
CM_ SG_ 2566778878 UtilityPhaseCApparentPower "The apparent power delivered by phase C of the utility incomer.";
CM_ SG_ 2566778878 UtilityPhaseCRealPower "The real power delivered by phase C of the utility incomer.";
CM_ BO_ 2566779134 "Utility Phase C AC Basic Quantities";
CM_ SG_ 2566779134 UtilityPhaseCACRMSCurrent "RMS current measured at the utility incomer phase C.";
CM_ SG_ 2566779134 UtilityPhaseCACFrequency "AC frequency measured at the utility incomer phase C.";
CM_ SG_ 2566779134 UtltyPhsCLneNeutralACRMSVoltage "Line to Neutral RMS voltage measured at the utility incomer phase C.";
CM_ SG_ 2566779134 UtltyPhseCALineLineACRMSVoltage "Line to Line RMS voltage measured at the utility incomer phase CA.";
CM_ BO_ 2566779390 "Utility Phase B AC Reactive Power";
CM_ SG_ 2566779390 UtilityPhaseBPowerFactorLagging "Lead/lag status for utility incomer phase B power factor.";
CM_ SG_ 2566779390 UtilityPhaseBPowerFactor "The power factor of phases B of the utility incomer.";
CM_ SG_ 2566779390 UtilityPhaseBReactivePower "The reactive power delivered by phase B of the utility incomer";
CM_ BO_ 2566779646 "Utility Phase B AC Power";
CM_ SG_ 2566779646 UtilityPhaseBApparentPower "The apparent power delivered by phase B of the utility incomer.";
CM_ SG_ 2566779646 UtilityPhaseBRealPower "The real power delivered by phase B of the utility incomer.";
CM_ BO_ 2566779902 "Utility Phase B AC Basic Quantities";
CM_ SG_ 2566779902 UtilityPhaseBACRMSCurrent "RMS current measured at the utility incomer phase B.";
CM_ SG_ 2566779902 UtilityPhaseBACFrequency "AC frequency measured at the utility incomer phase B.";
CM_ SG_ 2566779902 UtltyPhsBLneNeutralACRMSVoltage "Line to Neutral RMS voltage measured at the utility incomer phase B.";
CM_ SG_ 2566779902 UtltyPhseBCLineLineACRMSVoltage "Line to Line RMS voltage measured at the utility incomer phase BC.";
CM_ BO_ 2566780158 "Utility Phase A  AC Reactive Power";
CM_ SG_ 2566780158 UtilityPhaseAPowerFactorLagging "Lead/lag status for utility incomer phase A power factor.";
CM_ SG_ 2566780158 UtilityPhaseAPowerFactor "The power factor of phase A of the utility incomer.";
CM_ SG_ 2566780158 UtilityPhaseAReactivePower "The reactive power delivered by phase A of the utility incomer";
CM_ BO_ 2566780414 "Utility Phase A  AC Power";
CM_ SG_ 2566780414 UtilityPhaseAApparentPower "The apparent power delivered by phase A of the utility incomer.";
CM_ SG_ 2566780414 UtilityPhaseARealPower "The real power delivered by phase A of the utility incomer.";
CM_ BO_ 2566780670 "Utility Phase A Basic AC Quantities";
CM_ SG_ 2566780670 UtilityPhaseAACRMSCurrent "RMS current measured at the utility incomer phase A.";
CM_ SG_ 2566780670 UtilityPhaseAACFrequency "AC frequency measured at the utility incomer phase A.";
CM_ SG_ 2566780670 UtltyPhsALneNeutralACRMSVoltage "Line to Neutral RMS voltage measured at the utility incomer phase A.";
CM_ SG_ 2566780670 UtltyPhseABLineLineACRMSVoltage "Line to Line RMS voltage measured at the utility incomer phase AB.";
CM_ BO_ 2566781438 "Utility Average Basic AC Quantities";
CM_ SG_ 2566781438 UtilityAverageACRMSCurrent "Average RMS current measured at the utility incomer.";
CM_ SG_ 2566781438 UtilityAverageACFrequency "Average AC frequency measured at the utility incomer.";
CM_ SG_ 2566781438 UtltyAvrgLneNeutralACRMSVoltage "The average Line to Neutral AC RMS voltage measured at the utility incomer .";
CM_ SG_ 2566781438 UtltyAvrageLineLineACRMSVoltage "Average Line to Line RMS voltage measured at the utility incomer .";
CM_ BO_ 2566784254 "Generator Total AC Reactive Power";
CM_ SG_ 2566784254 GnrtorOverallPowerFactorLagging "Lead/lag status for generator average power factor.";
CM_ SG_ 2566784254 GeneratorOverallPowerFactor "The average power factor of the generator.";
CM_ SG_ 2566784254 GeneratorTotalReactivePower "The total reactive power delivered by the generator";
CM_ BO_ 2566784510 "Generator Total AC Power";
CM_ SG_ 2566784510 GeneratorTotalApparentPower "The total apparent power delivered by the generator.";
CM_ SG_ 2566784510 GeneratorTotalRealPower "Total real power delivered by the generator.";
CM_ BO_ 2566781694 "Generator Total AC Energy";
CM_ SG_ 2566781694 GeneratorTotalKWHoursImport "The total kilowatt-hours that have been imported by the generator.";
CM_ SG_ 2566781694 GeneratorTotalKWHoursExport "The total kilowatt-hours that have been exported by the generator.";
CM_ BO_ 2566781950 "Generator Phase C AC Reactive Power";
CM_ SG_ 2566781950 GnratorPhaseCPowerFactorLagging "Lead/lag status for generator phase C power factor.";
CM_ SG_ 2566781950 GeneratorPhaseCPowerFactor "The power factor of phases C of the generator.";
CM_ SG_ 2566781950 GeneratorPhaseCReactivePower "The reactive power delivered by phase C of the generator";
CM_ BO_ 2566782206 "Generator Phase C AC Power";
CM_ SG_ 2566782206 GeneratorPhaseCApparentPower "The apparent power delivered by phase C of the generator.";
CM_ SG_ 2566782206 GeneratorPhaseCRealPower "The real power delivered by phase C of the generator.";
CM_ BO_ 2566782462 "Generator Phase C Basic AC Quantities";
CM_ SG_ 2566782462 GeneratorPhaseCACRMSCurrent "RMS current measured at the generator phase C output.";
CM_ SG_ 2566782462 GeneratorPhaseCACFrequency "AC frequency measured at the generator phase C output.";
CM_ SG_ 2566782462 GnrtrPhsCLneNeutralACRMSVoltage "Line to Neutral RMS voltage measured at the generator phase C output.";
CM_ SG_ 2566782462 GnrtrPhseCALineLineACRMSVoltage "Line to Line RMS voltage measured at the generator phase CA output.";
CM_ BO_ 2566782718 "Generator Phase B AC Reactive Power";
CM_ SG_ 2566782718 GnratorPhaseBPowerFactorLagging "Lead/lag status for generator phase B power factor.";
CM_ SG_ 2566782718 GeneratorPhaseBPowerFactor "The power factor of phases B of the generator.";
CM_ SG_ 2566782718 GeneratorPhaseBReactivePower "The reactive power delivered by phase B of the generator";
CM_ BO_ 2566782974 "Generator Phase B AC Power";
CM_ SG_ 2566782974 GeneratorPhaseBApparentPower "The apparent power delivered by phase B of the generator.";
CM_ SG_ 2566782974 GeneratorPhaseBRealPower "The real power delivered by phase B of the generator.";
CM_ BO_ 2566783230 "Generator Phase B Basic AC Quantities";
CM_ SG_ 2566783230 GeneratorPhaseBACRMSCurrent "RMS current measured at the generator phase B output.";
CM_ SG_ 2566783230 GeneratorPhaseBACFrequency "AC frequency measured at the generator phase B output.";
CM_ SG_ 2566783230 GnrtrPhsBLneNeutralACRMSVoltage "Line to Neutral RMS voltage measured at the generator phase B output.";
CM_ SG_ 2566783230 GnrtrPhseBCLineLineACRMSVoltage "Line to Line RMS voltage measured at the generator phase BC output.";
CM_ BO_ 2566783486 "Generator Phase A AC Reactive Power";
CM_ SG_ 2566783486 GnratorPhaseAPowerFactorLagging "Lead/lag status for generator phase A power factor.";
CM_ SG_ 2566783486 GeneratorPhaseAPowerFactor "The power factor of phase A of the generator.";
CM_ SG_ 2566783486 GeneratorPhaseAReactivePower "The reactive power delivered by phase A of the generator";
CM_ BO_ 2566783742 "Generator Phase A AC Power";
CM_ SG_ 2566783742 GeneratorPhaseAApparentPower "The apparent power delivered by phase A of the generator.";
CM_ SG_ 2566783742 GeneratorPhaseARealPower "The real power delivered by phase A of the generator.";
CM_ BO_ 2566783998 "Generator Phase A Basic AC Quantities";
CM_ SG_ 2566783998 GeneratorPhaseAACRMSCurrent "RMS current measured at the generator phase A output.";
CM_ SG_ 2566783998 GeneratorPhaseAACFrequency "AC frequency measured at the generator phase A output.";
CM_ SG_ 2566783998 GnrtrPhsALneNeutralACRMSVoltage "Line to Neutral RMS voltage measured at the generator phase A output.";
CM_ SG_ 2566783998 GnrtrPhseABLineLineACRMSVoltage "Line to Line RMS voltage measured at the generator phase AB output.";
CM_ BO_ 2566784766 "Generator Average Basic AC Quantities";
CM_ SG_ 2566784766 GeneratorAverageACRMSCurrent "Average RMS current measured at the generator output.";
CM_ SG_ 2566784766 GeneratorAverageACFrequency "Average AC frequency measured at the generator output.";
CM_ SG_ 2566784766 GnrtrAvrgLneNeutralACRMSVoltage "The average Line to Neutral AC RMS voltage measured at the Generator output.";
CM_ SG_ 2566784766 GnrtrAvrageLineLineACRMSVoltage "Average Line to Line RMS voltage measured at the generator output.";
CM_ BO_ 2566776830 "Bus #1/Utility Sync Check Status";
CM_ SG_ 2566776830 Bus1_UtilityACPhaseDifference "The phase difference between the Bus #1 voltage and Utility voltage.";
CM_ SG_ 2566776830 Bus1_UtilityInSync "Indicator of whether Bus #1 and Utility are properly synchronized for paralleling. This indicator will be based on parameters such as Voltage Match, Frequency Match, and Phase Match.";
CM_ SG_ 2566776830 Bus1_UtilityVoltageMatch "Indicator of whether voltage difference between Bus #1 and Utility is adequate for paralleling. This indicator will be based on the measured AC voltages qualified using parameters such as Voltage Tolerance.";
CM_ SG_ 2566776830 Bus1_UtilityFrequencyMatch "Indicator of whether frequency difference between Bus #1 and Utility is adequate for paralleling. This indicator will be based on the measured AC frequencies qualified using parameters such as Frequency Tolerance, Phase Tolerance, and Dwell Time.";
CM_ SG_ 2566776830 Bus1_UtilityPhaseMatch "Indicator of whether phase difference between Bus #1 and Utility is adequate for paralleling. This indicator will be based on the measured AC phase difference qualified using parameters such as Phase Tolerance and Dwell Time.";
CM_ SG_ 2566776830 Bus1_UtilityDeadBus "Indicator of whether Bus #1 is considered dead for closing to the utility. This indicator will be based on parameters such as Bus #1 Voltage and dead bus threshold values.";
CM_ BO_ 2566777342 "Bus #1 Phase C  Basic AC Quantities";
CM_ SG_ 2566777342 Bus1PhaseCACFrequency "AC frequency measured at bus #1 phase C.";
CM_ SG_ 2566777342 Bs1PhseCLineNeutralACRMSVoltage "Line to Neutral RMS voltage measured at bus #1 phase C.";
CM_ SG_ 2566777342 Bus1PhaseCALineLineACRMSVoltage "Line to Line RMS voltage measured at bus #1 phase CA.";
CM_ BO_ 2566777598 "Bus #1 Phase B  Basic AC Quantities";
CM_ SG_ 2566777598 Bus1PhaseBACFrequency "AC frequency measured at bus #1 phase B.";
CM_ SG_ 2566777598 Bs1PhseBLineNeutralACRMSVoltage "Line to Neutral RMS voltage measured at bus #1 phase B.";
CM_ SG_ 2566777598 Bus1PhaseBCLineLineACRMSVoltage "Line to Line RMS voltage measured at bus #1 phase BC.";
CM_ BO_ 2566777854 "Bus #1 Phase A  Basic AC Quantities";
CM_ SG_ 2566777854 Bus1PhaseAACFrequency "AC frequency measured at bus #1 phase A.";
CM_ SG_ 2566777854 Bs1PhseALineNeutralACRMSVoltage "Line to Neutral RMS voltage measured at bus #1 phase A.";
CM_ SG_ 2566777854 Bus1PhaseABLineLineACRMSVoltage "Line to Line RMS voltage measured at bus #1 phase AB.";
CM_ BO_ 2566777086 "Bus #1/Generator Sync Check Status";
CM_ SG_ 2566777086 Bus1_GeneratorACPhaseDifference "The phase difference between the Bus #1 voltage and Generator voltage.";
CM_ SG_ 2566777086 Bus1_GeneratorInSync "Indicator of whether Bus #1 and Generator are properly synchronized for paralleling. This indicator will be based on parameters such as Voltage Match, Frequency Match, and Phase Match.";
CM_ SG_ 2566777086 Bus1_GeneratorVoltageMatch "Indicator of whether voltage difference between Bus #1 and Generator is adequate for paralleling. This indicator will be based on the measured AC voltages qualified using parameters such as Voltage Tolerance.";
CM_ SG_ 2566777086 Bus1_GeneratorFrequencyMatch "Indicator of whether frequency difference between Bus #1 and Generator is adequate for paralleling. This indicator will be based on the measured AC frequencies qualified using parameters such as Frequency Tolerance, Phase Tolerance, and Dwell Time.";
CM_ SG_ 2566777086 Bus1_GeneratorPhaseMatch "Indicator of whether phase difference between Bus #1 and Generator is adequate for paralleling. This indicator will be based on the measured AC phase difference qualified using parameters such as Phase Tolerance and Dwell Time.";
CM_ SG_ 2566777086 Bus1_GeneratorDeadBus "Indicator of whether Bus #1 is considered dead for closing to the generator. This indicator will be based on parameters such as Bus #1 Voltage and dead bus threshold values.";
CM_ BO_ 2566778110 "Bus #1 Average Basic AC Quantities";
CM_ SG_ 2566778110 Bus1AverageACFrequency "Average AC frequency measured at bus #1.";
CM_ SG_ 2566778110 Bs1AvrgeLineNeutralACRMSVoltage "The average Line to Neutral AC RMS voltage measured at bus #1 .";
CM_ SG_ 2566778110 Bus1AverageLineLineACRMSVoltage "Average Line to Line RMS voltage measured at bus #1 .";
CM_ BO_ 2633895422 "Working Set Master";
CM_ BO_ 2563440382 "Transfer";
CM_ SG_ 2563440382 ShrtNameOfActualReportingDevice "Short name of reporting device of the requested PGN via the Transfer PGN.";
CM_ SG_ 2563440382 LengthOfDataForTheReportedPGN "Length of data reported with the associated PGN via the Transfer PGN.";
CM_ SG_ 2563440382 PGNofRequstedInformation "PGN associated with this transfer message";
CM_ BO_ 2632711934 "Transport Protocol - Data Transfer";
CM_ BO_ 2632777470 "Transport Protocol - Connection Management";
CM_ SG_ 2632777470 TotalNumberOfPacketsEoMA "Total number of packets for BAM message.Total number of packets received for RTS/CTS message.Total number of packets for RTS/CTS message.";
CM_ SG_ 2632777470 TotalMessageSizeEoMA "Total message size (in bytes) for BAM message.Total message size (in bytes) for RTS/CTS message.Total message size (in bytes) for RTS/CTS message.";
CM_ SG_ 2632777470 TotalMessageSizeBAM "Total message size (in bytes) for BAM message.Total message size (in bytes) for RTS/CTS message.Total message size (in bytes) for RTS/CTS message.";
CM_ SG_ 2632777470 TotalNumberOfPacketsBAM "Total number of packets for BAM message.Total number of packets received for RTS/CTS message.Total number of packets for RTS/CTS message.";
CM_ SG_ 2632777470 ConnectionAbortReason "Reason for connection abort message.";
CM_ SG_ 2632777470 NextPacketNumberToBeSent "Next Packet Number to be sent (TP.CM_CTS)";
CM_ SG_ 2632777470 NumberOfPacketsThatCanBeSent "Number of Packets that can be sent (TP.CM_CTS)";
CM_ SG_ 2632777470 MaximumNumberOfPackets "Maximum number of packets for RTS/CTS message.";
CM_ SG_ 2632777470 TotalNumberOfPackets "Total number of packets for BAM message.Total number of packets received for RTS/CTS message.Total number of packets for RTS/CTS message.";
CM_ SG_ 2632777470 TotalMessageSize "Total message size (in bytes) for BAM message.Total message size (in bytes) for RTS/CTS message.Total message size (in bytes) for RTS/CTS message.";
CM_ BO_ 2563374846 "Request 2";
CM_ SG_ 2563374846 UseTransferMode "Requester is to respond via the Transfer PGN";
CM_ SG_ 2563374846 ParameterGroupNumber "PGN which is requested by Request2 message";
CM_ BO_ 2565537534 "Request";
CM_ SG_ 2565537534 ParameterGroupNumber "PGN which is requested by Request2 message";
CM_ BO_ 2499635966 "Axle Group Weight";
CM_ SG_ 2499635966 AxleGroupWeight "Total mass imposed on the road surface by all the tires in the axle group";
CM_ SG_ 2499635966 AxleGroupLocation "Specific axle group used in conjunction with and when communicating the axle group weight, listed from the front of the";
CM_ BO_ 2633853438 "Axle Group Calibration Weights";
CM_ SG_ 2633853438 AxleGroupLocation "Specific axle group used in conjunction with and when communicating the axle group calibration, listed from the front of";
CM_ SG_ 2633853438 AxleGroupFullWeightCalib "The full weight calibration measurement of an axle group";
CM_ SG_ 2633853438 AxleGroupEmptyWeightCalib "The empty weight calibration measurement of an axle group";
CM_ BO_ 2432520702 "Aftercooler Coolant Control Valve Command";
CM_ SG_ 2432520702 DsrdAftrcoolerCoolantIntakeTemp "Indicates the desired temperature of the fluid in the low temperature aftercooler circuit to an electronic thermostat.";
CM_ SG_ 2432520702 DsrdAftrclrClntThrmostatOpening "Used to transmit the desired position of the low temperature aftercooler temperature control valve.";
CM_ SG_ 2432520702 AftrcoolerCoolantThermostatMode "Specifies if the aftercooler coolant thermostat valve will operate in temperature control mode or position control mode.";
CM_ BO_ 2566745086 "Available Axle Group Weights";
CM_ SG_ 2566745086 AddtnlTrlrAxlGrpWeightAvailable "Indicates the availability of the additional trailer axle group for purposes of weight measurement";
CM_ SG_ 2566745086 TrilerHAxleGroupWeightAvailable "Indicates the availability of the trailer H axle group for purposes of weight measurement";
CM_ SG_ 2566745086 TrilerGAxleGroupWeightAvailable "Indicates the availability of the trailer G axle group for purposes of weight measurement";
CM_ SG_ 2566745086 TrilerFAxleGroupWeightAvailable "Indicates the availability of the trailer F axle group for purposes of weight measurement";
CM_ SG_ 2566745086 TrilerEAxleGroupWeightAvailable "Indicates the availability of the trailer E axle group for purposes of weight measurement";
CM_ SG_ 2566745086 TrilerDAxleGroupWeightAvailable "Indicates the availability of the trailer D axle group for purposes of weight measurement";
CM_ SG_ 2566745086 TrilerCAxleGroupWeightAvailable "Indicates the availability of the trailer C axle group for purposes of weight measurement";
CM_ SG_ 2566745086 TrilerBAxleGroupWeightAvailable "Indicates the availability of the trailer B axle group for purposes of weight measurement";
CM_ SG_ 2566745086 TrilerAAxleGroupWeightAvailable "Indicates the availability of the trailer A axle group for purposes of weight measurement";
CM_ SG_ 2566745086 AddtnlTrctrAxlGrpWightAvailable "Indicates the availability of the additional tractor axle group for purposes of weight measurement";
CM_ SG_ 2566745086 TagAxleGroupWeightAvailable "Indicates the availability of the tag axle group for purposes of weight measurement";
CM_ SG_ 2566745086 DriveAxleGroupWeightAvailable "Indicates the availability of the drive axle group for purposes of weight measurement";
CM_ SG_ 2566745086 LiftAxleGroupWeightAvailable "Indicates the availability of the lift axle group for purposes of weight measurement";
CM_ SG_ 2566745086 SteerAxleGroupWeightAvailable "Indicates the availability of the steer axle group for purposes of weight measurement";
CM_ BO_ 2566744062 "Zero Net Vehicle Weight Change";
CM_ SG_ 2566744062 ZeroNetVehicleWeightChange "Zero Net Vehicle Weight Change command.";
CM_ BO_ 2499630078 "Reports averaged engine information";
CM_ SG_ 2499630078 EngExhaustGasTempAverageBank2 "The calculated average temperature based upon all of the Bank 2 (right bank) engine exhaust port temperatures.";
CM_ SG_ 2499630078 EngExhaustGasTempAverageBank1 "The calculated average temperature based upon all of the Bank 1 (left bank) engine exhaust port temperatures.";
CM_ SG_ 2499630078 EngExhaustGasTempAverage "The calculated average temperature based upon all of the engine exhaust port temperatures.";
CM_ BO_ 2560556798 "DTC Counts";
CM_ SG_ 2560556798 PermanentDTCs "Identifies the current number of permanent DTCs";
CM_ SG_ 2560556798 PreviouslyMILOnDTCs "Identifies the current number of previously MIL-On DTCs";
CM_ SG_ 2560556798 MILOnDTCs "Identifies the current number of MIL-On DTCs";
CM_ SG_ 2560556798 AllPendingDTCs "Identifies the current total number of pending DTCs, including emission related";
CM_ SG_ 2560556798 PendingDTCs "Identifies the current number of emission related pending DTCs";
CM_ BO_ 2566754558 "Advertised Engine Torque Curve";
CM_ SG_ 2566754558 AETCTorqueValue "Engine torque value of the data points in PGN 64912 Advertised Engine Torque Curve (AETC).";
CM_ SG_ 2566754558 NumberOfAETCDataPoints "Indicates the number of speed / torque data points contained in the Advertised Engine Torque Curve broadcast (AETC).";
CM_ SG_ 2566754558 AETCDataCollectionStandard "Indicates the standardized method by which torque data was obtained for the Advertised Engine Torque Curve (AETC).";
CM_ BO_ 2566749950 "Adaptive Front-Lighting System Status";
CM_ SG_ 2566749950 RightHeadlampLightDistribution "This parameter indicates what kind of light distribution is set by the AFS system for the right headlamp.";
CM_ SG_ 2566749950 LeftHeadlampLightDistribution "This parameter indicates what kind of light distribution is set by the AFS system for the left headlamp.";
CM_ SG_ 2566749950 RghtHeadlampDynamicBendingLight "This parameter indicates whether the dynamic bending light of the left headlamp is working properly.";
CM_ SG_ 2566749950 LeftHeadlampDynamicBendingLight "This parameter indicates whether the dynamic bending light of the left headlamp is working properly.";
CM_ BO_ 2566838782 "Auxiliary Input/Output Status 1";
CM_ SG_ 2566838782 AuxI_O16 "Identifies the current status of auxiliary input/output functions that are configured uniquely per application.";
CM_ SG_ 2566838782 AuxI_O15 "Identifies the current status of auxiliary input/output functions that are configured uniquely per application.";
CM_ SG_ 2566838782 AuxI_O14 "Identifies the current status of auxiliary input/output functions that are configured uniquely per application.";
CM_ SG_ 2566838782 AuxI_O13 "Identifies the current status of auxiliary input/output functions that are configured uniquely per application.";
CM_ SG_ 2566838782 AuxI_O12 "Identifies the current status of auxiliary input/output functions that are configured uniquely per application.";
CM_ SG_ 2566838782 AuxI_O11 "Identifies the current status of auxiliary input/output functions that are configured uniquely per application.";
CM_ SG_ 2566838782 AuxI_O10 "Identifies the current status of auxiliary input/output functions that are configured uniquely per application.";
CM_ SG_ 2566838782 AuxI_O09 "Identifies the current status of auxiliary input/output functions that are configured uniquely per application.";
CM_ SG_ 2566838782 AuxI_O08 "Identifies the current status of auxiliary input/output functions that are configured uniquely per application.";
CM_ SG_ 2566838782 AuxI_O07 "Identifies the current status of auxiliary input/output functions that are configured uniquely per application.";
CM_ SG_ 2566838782 AuxI_O06 "Identifies the current status of auxiliary input/output functions that are configured uniquely per application.";
CM_ SG_ 2566838782 AuxI_O05 "Identifies the current status of auxiliary input/output functions that are configured uniquely per application.";
CM_ SG_ 2566838782 AuxI_O04 "Identifies the current status of auxiliary input/output functions that are configured uniquely per application.";
CM_ SG_ 2566838782 AuxI_O03 "Identifies the current status of auxiliary input/output functions that are configured uniquely per application.";
CM_ SG_ 2566838782 AuxI_O02 "Identifies the current status of auxiliary input/output functions that are configured uniquely per application.";
CM_ SG_ 2566838782 AuxI_O01 "Identifies the current status of auxiliary input/output functions that are configured uniquely per application.";
CM_ SG_ 2566838782 AuxI_OChannel2 "Auxiliary channel of data (16 bit) read by the ECU.";
CM_ SG_ 2566838782 AuxI_OChannel1 "Auxiliary channel of data (16 bit) read by the ECU.";
CM_ BO_ 2561146622 "Auxiliary Input/Output Status 2";
CM_ SG_ 2561146622 AuxI_O45 "Identifies the current status of auxiliary input/output functions that are configured uniquely per application.";
CM_ SG_ 2561146622 AuxI_O46 "Identifies the current status of auxiliary input/output functions that are configured uniquely per application.";
CM_ SG_ 2561146622 AuxI_O47 "Identifies the current status of auxiliary input/output functions that are configured uniquely per application.";
CM_ SG_ 2561146622 AuxI_O48 "Identifies the current status of auxiliary input/output functions that are configured uniquely per application.";
CM_ SG_ 2561146622 AuxI_O41 "Identifies the current status of auxiliary input/output functions that are configured uniquely per application.";
CM_ SG_ 2561146622 AuxI_O42 "Identifies the current status of auxiliary input/output functions that are configured uniquely per application.";
CM_ SG_ 2561146622 AuxI_O43 "Identifies the current status of auxiliary input/output functions that are configured uniquely per application.";
CM_ SG_ 2561146622 AuxI_O44 "Identifies the current status of auxiliary input/output functions that are configured uniquely per application.";
CM_ SG_ 2561146622 AuxI_O37 "Identifies the current status of auxiliary input/output functions that are configured uniquely per application.";
CM_ SG_ 2561146622 AuxI_O38 "Identifies the current status of auxiliary input/output functions that are configured uniquely per application.";
CM_ SG_ 2561146622 AuxI_O39 "Identifies the current status of auxiliary input/output functions that are configured uniquely per application.";
CM_ SG_ 2561146622 AuxI_O40 "Identifies the current status of auxiliary input/output functions that are configured uniquely per application.";
CM_ SG_ 2561146622 AuxI_O33 "Identifies the current status of auxiliary input/output functions that are configured uniquely per application.";
CM_ SG_ 2561146622 AuxI_O34 "Identifies the current status of auxiliary input/output functions that are configured uniquely per application.";
CM_ SG_ 2561146622 AuxI_O35 "Identifies the current status of auxiliary input/output functions that are configured uniquely per application.";
CM_ SG_ 2561146622 AuxI_O36 "Identifies the current status of auxiliary input/output functions that are configured uniquely per application.";
CM_ SG_ 2561146622 AuxI_O29 "Identifies the current status of auxiliary input/output functions that are configured uniquely per application.";
CM_ SG_ 2561146622 AuxI_O30 "Identifies the current status of auxiliary input/output functions that are configured uniquely per application.";
CM_ SG_ 2561146622 AuxI_O31 "Identifies the current status of auxiliary input/output functions that are configured uniquely per application.";
CM_ SG_ 2561146622 AuxI_O32 "Identifies the current status of auxiliary input/output functions that are configured uniquely per application.";
CM_ SG_ 2561146622 AuxI_O25 "Identifies the current status of auxiliary input/output functions that are configured uniquely per application.";
CM_ SG_ 2561146622 AuxI_O26 "Identifies the current status of auxiliary input/output functions that are configured uniquely per application.";
CM_ SG_ 2561146622 AuxI_O27 "Identifies the current status of auxiliary input/output functions that are configured uniquely per application.";
CM_ SG_ 2561146622 AuxI_O28 "Identifies the current status of auxiliary input/output functions that are configured uniquely per application.";
CM_ SG_ 2561146622 AuxI_O21 "Identifies the current status of auxiliary input/output functions that are configured uniquely per application.";
CM_ SG_ 2561146622 AuxI_O22 "Identifies the current status of auxiliary input/output functions that are configured uniquely per application.";
CM_ SG_ 2561146622 AuxI_O23 "Identifies the current status of auxiliary input/output functions that are configured uniquely per application.";
CM_ SG_ 2561146622 AuxI_O24 "Identifies the current status of auxiliary input/output functions that are configured uniquely per application.";
CM_ SG_ 2561146622 AuxI_O17 "Identifies the current status of auxiliary input/output functions that are configured uniquely per application.";
CM_ SG_ 2561146622 AuxI_O18 "Identifies the current status of auxiliary input/output functions that are configured uniquely per application.";
CM_ SG_ 2561146622 AuxI_O19 "Identifies the current status of auxiliary input/output functions that are configured uniquely per application.";
CM_ SG_ 2561146622 AuxI_O20 "Identifies the current status of auxiliary input/output functions that are configured uniquely per application.";
CM_ BO_ 2561081086 "Auxiliary Input/Output Status 3";
CM_ SG_ 2561081086 AuxI_O77 "Identifies the current status of auxiliary input/output functions that are configured uniquely per application.";
CM_ SG_ 2561081086 AuxI_O78 "Identifies the current status of auxiliary input/output functions that are configured uniquely per application.";
CM_ SG_ 2561081086 AuxI_O79 "Identifies the current status of auxiliary input/output functions that are configured uniquely per application.";
CM_ SG_ 2561081086 AuxI_O80 "Identifies the current status of auxiliary input/output functions that are configured uniquely per application.";
CM_ SG_ 2561081086 AuxI_O73 "Identifies the current status of auxiliary input/output functions that are configured uniquely per application.";
CM_ SG_ 2561081086 AuxI_O74 "Identifies the current status of auxiliary input/output functions that are configured uniquely per application.";
CM_ SG_ 2561081086 AuxI_O75 "Identifies the current status of auxiliary input/output functions that are configured uniquely per application.";
CM_ SG_ 2561081086 AuxI_O76 "Identifies the current status of auxiliary input/output functions that are configured uniquely per application.";
CM_ SG_ 2561081086 AuxI_O69 "Identifies the current status of auxiliary input/output functions that are configured uniquely per application.";
CM_ SG_ 2561081086 AuxI_O70 "Identifies the current status of auxiliary input/output functions that are configured uniquely per application.";
CM_ SG_ 2561081086 AuxI_O71 "Identifies the current status of auxiliary input/output functions that are configured uniquely per application.";
CM_ SG_ 2561081086 AuxI_O72 "Identifies the current status of auxiliary input/output functions that are configured uniquely per application.";
CM_ SG_ 2561081086 AuxI_O65 "Identifies the current status of auxiliary input/output functions that are configured uniquely per application.";
CM_ SG_ 2561081086 AuxI_O66 "Identifies the current status of auxiliary input/output functions that are configured uniquely per application.";
CM_ SG_ 2561081086 AuxI_O67 "Identifies the current status of auxiliary input/output functions that are configured uniquely per application.";
CM_ SG_ 2561081086 AuxI_O68 "Identifies the current status of auxiliary input/output functions that are configured uniquely per application.";
CM_ SG_ 2561081086 AuxI_O61 "Identifies the current status of auxiliary input/output functions that are configured uniquely per application.";
CM_ SG_ 2561081086 AuxI_O62 "Identifies the current status of auxiliary input/output functions that are configured uniquely per application.";
CM_ SG_ 2561081086 AuxI_O63 "Identifies the current status of auxiliary input/output functions that are configured uniquely per application.";
CM_ SG_ 2561081086 AuxI_O64 "Identifies the current status of auxiliary input/output functions that are configured uniquely per application.";
CM_ SG_ 2561081086 AuxI_O57 "Identifies the current status of auxiliary input/output functions that are configured uniquely per application.";
CM_ SG_ 2561081086 AuxI_O58 "Identifies the current status of auxiliary input/output functions that are configured uniquely per application.";
CM_ SG_ 2561081086 AuxI_O59 "Identifies the current status of auxiliary input/output functions that are configured uniquely per application.";
CM_ SG_ 2561081086 AuxI_O60 "Identifies the current status of auxiliary input/output functions that are configured uniquely per application.";
CM_ SG_ 2561081086 AuxI_O53 "Identifies the current status of auxiliary input/output functions that are configured uniquely per application.";
CM_ SG_ 2561081086 AuxI_O54 "Identifies the current status of auxiliary input/output functions that are configured uniquely per application.";
CM_ SG_ 2561081086 AuxI_O55 "Identifies the current status of auxiliary input/output functions that are configured uniquely per application.";
CM_ SG_ 2561081086 AuxI_O56 "Identifies the current status of auxiliary input/output functions that are configured uniquely per application.";
CM_ SG_ 2561081086 AuxI_O49 "Identifies the current status of auxiliary input/output functions that are configured uniquely per application.";
CM_ SG_ 2561081086 AuxI_O50 "Identifies the current status of auxiliary input/output functions that are configured uniquely per application.";
CM_ SG_ 2561081086 AuxI_O51 "Identifies the current status of auxiliary input/output functions that are configured uniquely per application.";
CM_ SG_ 2561081086 AuxI_O52 "Identifies the current status of auxiliary input/output functions that are configured uniquely per application.";
CM_ BO_ 2561015550 "Auxiliary Input/Output Status 4";
CM_ SG_ 2561015550 AuxI_O92 "Identifies the current status of auxiliary input/output functions that are configured uniquely per application.";
CM_ SG_ 2561015550 AuxI_O85 "Identifies the current status of auxiliary input/output functions that are configured uniquely per application.";
CM_ SG_ 2561015550 AuxI_O86 "Identifies the current status of auxiliary input/output functions that are configured uniquely per application.";
CM_ SG_ 2561015550 AuxI_O87 "Identifies the current status of auxiliary input/output functions that are configured uniquely per application.";
CM_ SG_ 2561015550 AuxI_O88 "Identifies the current status of auxiliary input/output functions that are configured uniquely per application.";
CM_ SG_ 2561015550 AuxI_O81 "Identifies the current status of auxiliary input/output functions that are configured uniquely per application.";
CM_ SG_ 2561015550 AuxI_O82 "Identifies the current status of auxiliary input/output functions that are configured uniquely per application.";
CM_ SG_ 2561015550 AuxI_O83 "Identifies the current status of auxiliary input/output functions that are configured uniquely per application.";
CM_ SG_ 2561015550 AuxI_O84 "Identifies the current status of auxiliary input/output functions that are configured uniquely per application.";
CM_ SG_ 2561015550 AuxI_O109 "Identifies the current status of auxiliary input/output functions that are configured uniquely per application.";
CM_ SG_ 2561015550 AuxI_O110 "Identifies the current status of auxiliary input/output functions that are configured uniquely per application.";
CM_ SG_ 2561015550 AuxI_O111 "Identifies the current status of auxiliary input/output functions that are configured uniquely per application.";
CM_ SG_ 2561015550 AuxI_O112 "Identifies the current status of auxiliary input/output functions that are configured uniquely per application.";
CM_ SG_ 2561015550 AuxI_O105 "Identifies the current status of auxiliary input/output functions that are configured uniquely per application.";
CM_ SG_ 2561015550 AuxI_O106 "Identifies the current status of auxiliary input/output functions that are configured uniquely per application.";
CM_ SG_ 2561015550 AuxI_O107 "Identifies the current status of auxiliary input/output functions that are configured uniquely per application.";
CM_ SG_ 2561015550 AuxI_O108 "Identifies the current status of auxiliary input/output functions that are configured uniquely per application.";
CM_ SG_ 2561015550 AuxI_O101 "Identifies the current status of auxiliary input/output functions that are configured uniquely per application.";
CM_ SG_ 2561015550 AuxI_O102 "Identifies the current status of auxiliary input/output functions that are configured uniquely per application.";
CM_ SG_ 2561015550 AuxI_O103 "Identifies the current status of auxiliary input/output functions that are configured uniquely per application.";
CM_ SG_ 2561015550 AuxI_O104 "Identifies the current status of auxiliary input/output functions that are configured uniquely per application.";
CM_ SG_ 2561015550 AuxI_O97 "Identifies the current status of auxiliary input/output functions that are configured uniquely per application.";
CM_ SG_ 2561015550 AuxI_O98 "Identifies the current status of auxiliary input/output functions that are configured uniquely per application.";
CM_ SG_ 2561015550 AuxI_O99 "Identifies the current status of auxiliary input/output functions that are configured uniquely per application.";
CM_ SG_ 2561015550 AuxI_O100 "Identifies the current status of auxiliary input/output functions that are configured uniquely per application.";
CM_ SG_ 2561015550 AuxI_O93 "Identifies the current status of auxiliary input/output functions that are configured uniquely per application.";
CM_ SG_ 2561015550 AuxI_O94 "Identifies the current status of auxiliary input/output functions that are configured uniquely per application.";
CM_ SG_ 2561015550 AuxI_O95 "Identifies the current status of auxiliary input/output functions that are configured uniquely per application.";
CM_ SG_ 2561015550 AuxI_O96 "Identifies the current status of auxiliary input/output functions that are configured uniquely per application.";
CM_ SG_ 2561015550 AuxI_O89 "Identifies the current status of auxiliary input/output functions that are configured uniquely per application.";
CM_ SG_ 2561015550 AuxI_O90 "Identifies the current status of auxiliary input/output functions that are configured uniquely per application.";
CM_ SG_ 2561015550 AuxI_O91 "Identifies the current status of auxiliary input/output functions that are configured uniquely per application.";
CM_ BO_ 2566746622 "Brake actuator stroke status";
CM_ SG_ 2566746622 TrailerBrakeStrokeAxle5Right "Brake stroke status for right brake actuator on trailer axle 5.";
CM_ SG_ 2566746622 TrailerBrakeStrokeAxle5Left "Brake stroke status for left brake actuator on trailer axle 5.";
CM_ SG_ 2566746622 TrailerBrakeStrokeAxle4Right "Brake stroke status for right brake actuator on trailer axle 4.";
CM_ SG_ 2566746622 TrailerBrakeStrokeAxle4Left "Brake stroke status for left brake actuator on trailer axle 4.";
CM_ SG_ 2566746622 TrailerBrakeStrokeAxle3Right "Brake stroke status for right brake actuator on trailer axle 3.";
CM_ SG_ 2566746622 TrailerBrakeStrokeAxle3Left "Brake stroke status for left brake actuator on trailer axle 3.";
CM_ SG_ 2566746622 TrailerBrakeStrokeAxle2Right "Brake stroke status for right brake actuator on trailer axle 2.";
CM_ SG_ 2566746622 TrailerBrakeStrokeAxle2Left "Brake stroke status for left brake actuator on trailer axle 2.";
CM_ SG_ 2566746622 TrailerBrakeStrokeAxle1Right "Brake stroke status for right brake actuator on trailer axle 1.";
CM_ SG_ 2566746622 TrailerBrakeStrokeAxle1Left "Brake stroke status for left brake actuator on trailerr axle 1.";
CM_ SG_ 2566746622 TractorBrakeStrokeAxle5Right "Brake stroke status for right brake actuator on tractor axle 5.";
CM_ SG_ 2566746622 TractorBrakeStrokeAxle5Left "Brake stroke status for left brake actuator on tractor axle 5.";
CM_ SG_ 2566746622 TractorBrakeStrokeAxle4Right "Brake stroke status for right brake actuator on tractor axle 4.";
CM_ SG_ 2566746622 TractorBrakeStrokeAxle4Left "Brake stroke status for left brake actuator on tractor axle 4.";
CM_ SG_ 2566746622 TractorBrakeStrokeAxle3Right "Brake stroke status for right brake actuator on tractor axle 3.";
CM_ SG_ 2566746622 TractorBrakeStrokeAxle3Left "Brake stroke status for left brake actuator on tractor axle 3.";
CM_ SG_ 2566746622 TractorBrakeStrokeAxle2Right "Brake stroke status for right brake actuator on tractor axle 2.";
CM_ SG_ 2566746622 TractorBrakeStrokeAxle2Left "Brake stroke status for left brake actuator on tractor axle 2.";
CM_ SG_ 2566746622 TractorBrakeStrokeAxle1Right "Brake stroke status for right brake actuator on tractor axle 1.";
CM_ SG_ 2566746622 TractorBrakeStrokeAxle1Left "Brake stroke status for left brake actuator on tractor axle 1.";
CM_ BO_ 2566845950 "Ambient Conditions";
CM_ SG_ 2566845950 EngAirIntakeTemp "Temperature of air entering vehicle air induction system.";
CM_ SG_ 2566845950 RoadSurfaceTemp "Indicated temperature of road surface over which vehicle is operating.";
CM_ SG_ 2566845950 AmbientAirTemp "Temperature of air surrounding vehicle.";
CM_ SG_ 2566845950 CabInteriorTemp "Temperature of air inside the part of the vehicle that encloses the driver and vehicle operating controls.";
CM_ SG_ 2566845950 BarometricPress "Absolute air pressure of the atmosphere.";
CM_ BO_ 2566840062 "Air Start Pressure";
CM_ SG_ 2566840062 EngAirStartPress "Gage pressure of air in an engine starting system that utilizes compressed air to provide the force required to rotate the";
CM_ BO_ 2566827774 "Air Supply Pressure";
CM_ SG_ 2566827774 ServiceBrakeCircuit2AirPress "The pneumatic pressure in the secondary service brake circuit or reservoir, supplying the front axle.";
CM_ SG_ 2566827774 ServiceBrakeCircuit1AirPress "The pneumatic pressure in the primary service brake circuit or reservoir, supplying the rear axle.";
CM_ SG_ 2566827774 AirCompressorStatus "Indicates whether the air compressor is actively compressing air.";
CM_ SG_ 2566827774 AirSuspensionSupplyPress "The pneumatic pressure in the circuit for the electronically controlled air suspension system.";
CM_ SG_ 2566827774 AuxEquipmentSupplyPress "The pneumatic pressure in the auxiliary circuit.";
CM_ SG_ 2566827774 ParkingAnd_OrTrailerAirPress "The pneumatic pressure in the circuit or reservoir for the parking brake and/or the trailer supply.";
CM_ SG_ 2566827774 PneumaticSupplyPress "The pneumatic pressure in the main reservoir, sometimes referred to as the wet tank.";
CM_ BO_ 2566846974 "Axle Information";
CM_ SG_ 2566846974 SteerAxleLubePress "The steering axle lubricant pressure.";
CM_ SG_ 2566846974 SteerAxleTemp "Temperature of lubricant in steering axle.";
CM_ SG_ 2566846974 DriveAxleLubePress "The drive axle lubricant pressure with location determined by Drive Axle Location (SPN 930).";
CM_ SG_ 2566846974 DriveAxleTemp "Temperature of axle lubricant in drive axle.";
CM_ SG_ 2566846974 DriveAxleLiftAirPress "Gage pressure of air in system that utilizes compressed air to provide force between axle and frame.";
CM_ SG_ 2566846974 DriveAxleLocation "To identify to which of several similar devices (such as tires or fuel tanks) the information applies.";
CM_ BO_ 2633935614 "Alternate Fuel 2";
CM_ SG_ 2633935614 EngTurboWastegateValvePos "The position of the turbocharger wastegate valve (not the electronic wastegate control valve).";
CM_ SG_ 2633935614 EngGsMssFlwSnsrFelingCorrection "The amount of fuel the Gas Mass Flow Sensor is sensing should be added or subtracted compared to the maximum";
CM_ SG_ 2633935614 EngDsiredAbsIntakeManifoldPress "The desired absolute intake manifold pressure of the engine.";
CM_ SG_ 2633935614 EngGasFuelCorrectionFactor "A correction to a predefined gaseous fuel energy (expressed in energy per unit volume) represented as a percentage.";
CM_ BO_ 2566803966 "Adaptive Cruise Control, Operator Input";
CM_ SG_ 2566803966 ACCUsageDemand "This parameter indicates the drivers demand to activate or deactivate ACC keeping distance control.";
CM_ SG_ 2566803966 RqedACCDistanceMode "The Requested Distance Control Mode to the ACC system from the operators interface.";
CM_ BO_ 2432593918 "Adaptive Cruise Control";
CM_ SG_ 2432593918 ForwardCollisionWarning "This parameter indicates if a collision is imminent and strong driver reaction either by braking hard or by an avoidance";
CM_ SG_ 2432593918 ACCDistanceAlertSignal "Signal to indicate to the operator that the ACC system is not able to maintain the distance to the target.";
CM_ SG_ 2432593918 ACCSystemShutoffWarning "Signal to warn the driver of system deactivation due to non-driver actions.";
CM_ SG_ 2432593918 ACCTargetDetected "Signal to indicate to the driver that the ACC system has detected a target.";
CM_ SG_ 2432593918 RoadCurvature "Estimated value of the current road curvature for use by the adaptive cruise control system.";
CM_ SG_ 2432593918 AdptveCruiseCtrlSetDistanceMode "Selected distance mode for adaptive cruise control.";
CM_ SG_ 2432593918 AdaptiveCruiseCtrlMode "This parameter is used to indicate the current state, or mode, of operation by the Adaptive Cruise Control (ACC) device.";
CM_ SG_ 2432593918 AdaptiveCruiseCtrlSetSpeed "Value of the desired (chosen) velocity of the adaptive cruise control system.";
CM_ SG_ 2432593918 DistanceToForwardVehicle "Distance to the preceding vehicle situated within 250 m in the same lane and moving in the same direction.";
CM_ SG_ 2432593918 SpeedOfForwardVehicle "Absolute velocity of the preceding vehicle situated within 250 m in the same lane and moving in the same direction.";
CM_ BO_ 2633935102 "Articulation Control";
CM_ SG_ 2633935102 ArticulationAngle "Angle of deflection of an articulated transit vehicle.";
CM_ BO_ 2633927934 "Auxiliary Analog Information";
CM_ SG_ 2633927934 RelativeHumidity "Measures humidity of combustion air prior to entry into turbocharger";
CM_ SG_ 2633927934 AuxLevel "Level measured by a sensor.";
CM_ SG_ 2633927934 AuxPress2 "Pressure measured by auxiliary pressure sensor #2.";
CM_ SG_ 2633927934 AuxPress1 "Pressure measured by auxiliary pressure sensor #1.";
CM_ SG_ 2633927934 AuxTemp2 "Temperature measured by auxiliary temperature sensor #2.";
CM_ SG_ 2633927934 AuxTemp1 "Temperature measured by auxiliary temperature sensor #1.";
CM_ BO_ 2566847998 "Alternate Fuel 1";
CM_ SG_ 2566847998 EngBlowerBypassValvePos "Relative position of the blower bypass valve.";
CM_ SG_ 2566847998 EngGasSupplyPress "Gage pressure of gas supply to fuel metering device.";
CM_ BO_ 2566803198 "Door Control 1";
CM_ SG_ 2566803198 Status2OfDoors "Composite indication of all bus door statuses.";
CM_ SG_ 2566803198 Ramp_WheelChairLiftPos "Signal which indicates the actual position of the ramp / wheel chair lift.";
CM_ SG_ 2566803198 PosOfDoors "Signal which indicates the actual position of the doors.";
CM_ BO_ 2565870334 "Fifth Wheel Smart Systems 1";
CM_ SG_ 2565870334 FifthWheelRollWarningIndicator "Indicates to the vehicle operator that the roll moment has exceeded a preset limit.";
CM_ SG_ 2565870334 FifthWheelRollMoment "Fifth wheel roll moment force - If the moment is positive, the trailer is rolling clockwise relative to the normal vehicle";
CM_ SG_ 2565870334 FifthWheelDrawbarForce "Fifth wheel drawbar force, with the trailer held stationary a positive force is generated by the vehicle pulling forward.";
CM_ SG_ 2565870334 FifthWheelVerticalForce "The amount of load being applied to the fifth wheel by the trailer.";
CM_ BO_ 2566762238 "Fifth Wheel Smart Systems 2";
CM_ SG_ 2566762238 FifthWheelSliderLockIndicator "Indicates to vehicle operator that the fifth wheel slider is in position and locked.";
CM_ SG_ 2566762238 FifthWheelSliderPos "Slider position measurement.";
CM_ SG_ 2566762238 FfthWhlLckCoupleStatusIndicator "Indicates results of coupling operation to the vehicle operator.";
CM_ SG_ 2566762238 FfthWhlLckRadyToCoupleIndicator "Indicates to the vehicle operator that the fifth wheel lock is open and ready to couple.";
CM_ SG_ 2566762238 FifthWheelErrorStatus "Fifth wheel error state which conveys information when coupling status is incomplete or bad.";
CM_ BO_ 2364543998 "Slope Sensor Information";
CM_ SG_ 2364543998 RollAndPitchMeasurementLatency "The estimated measurement latency of the measurement.";
CM_ SG_ 2364543998 PitchAndRollCompensated "Compensated mode for the pitch and roll measurements.";
CM_ SG_ 2364543998 PitchRateFigureOfMerit "Figure of merit for the pitch rate measurement.";
CM_ SG_ 2364543998 RollAngleFigureOfMerit "Figure of merit for roll angle measurement.";
CM_ SG_ 2364543998 PitchAngleFigureOfMerit "Figure of merit for pitch angle measurement.";
CM_ SG_ 2364543998 PitchRate "Pitch rate is the rate-of-change of the pitch angle over time, where the pitch angle vector is in the direction of travel of the";
CM_ SG_ 2364543998 RollAngle "The angle between the vehicle y-axis and the ground plane.";
CM_ SG_ 2364543998 PitchAngle "The angle between the vehicle x-axis and the ground plane.";
CM_ BO_ 2566846718 "Transmission Fluids 1";
CM_ SG_ 2566846718 TransOilLevelMeasurementStatus "Indicates if conditions are acceptable to obtain a valid transmission oil level measurement as conveyed in SPN 124";
CM_ SG_ 2566846718 TransOilLevelCountdownTimer "Once all vehicle conditions (such as vehicle stopped, etc) are met, some transmissions may require a `settling time' to";
CM_ SG_ 2566846718 TransOilLevelHigh_Low "Amount of current volume of transmission sump oil compared to recommended volume.";
CM_ SG_ 2566846718 TransOilTemp "Temperature of the transmission lubricant.";
CM_ SG_ 2566846718 TransOilPress "Gage pressure of lubrication fluid in transmission, measured after pump.";
CM_ SG_ 2566846718 TransFilterDiffPress "Change in transmission fluid pressure, measured after the filter, due to accumulation of solid or semisolid material on or in";
CM_ SG_ 2566846718 TransOilLevel "Ratio of volume of transmission sump oil to recommended volume.";
CM_ SG_ 2566846718 ClutchPress "Gage pressure of oil within a wet clutch.";
CM_ BO_ 2566846462 "Vehicle Electrical Power 1";
CM_ SG_ 2566846462 ChargingSystemPotential "Electrical potential measured at the charging system output.";
CM_ SG_ 2566846462 AltCurrent "Measure of electrical current flow from the alternator.";
CM_ SG_ 2566846462 NetBatteryCurrent "Net flow of electrical current into/out of the battery or batteries.";
CM_ SG_ 2566846462 KeyswitchBatteryPotential "Battery potential measured at the input of the electronic control unit supplied through a keyswitch or similar switching";
CM_ SG_ 2566846462 BatteryPotential_PowerInput1 "This parameter measures the first source of battery potential as measured at the input of the ECM/actuator etc.";
CM_ BO_ 2566760702 "Wireless Communications Message 2";
CM_ SG_ 2566760702 WrlessCommunicationNetworkType2 "Type of Wireless Communication Network";
CM_ SG_ 2566760702 NetworkSignalStrength2 "Indicates the signal strength for the wireless communications network type.";
CM_ SG_ 2566760702 NetworkAntennaStatus2 "Indicates the status of the antenna for the wireless communications network type";
CM_ SG_ 2566760702 NetworkServiceStatus2 "Indicates the status of the Service for the wireless communications network type";
CM_ SG_ 2566760702 NetworkTransceiverStatus2 "Indicates the status of the transceiver for the wireless communications network type";
CM_ BO_ 2566760958 "Wireless Communications Message 1";
CM_ SG_ 2566760958 WrlessCommunicationNetworkType1 "Type of Wireless Communication Network";
CM_ SG_ 2566760958 NetworkSignalStrength1 "Indicates the signal strength for the wireless communications network type.";
CM_ SG_ 2566760958 NetworkAntennaStatus1 "Indicates the status of the antenna for the wireless communications network type";
CM_ SG_ 2566760958 NetworkServiceStatus1 "Indicates the status of the Service for the wireless communications network type";
CM_ SG_ 2566760958 NetworkTransceiverStatus1 "Indicates the status of the transceiver for the wireless communications network type";
BA_DEF_ SG_  "SigType" ENUM  "Default","Range","RangeSigned","ASCII","Discrete","Control","ReferencePGN","DTC","StringDelimiter","StringLength","StringLengthControl";
BA_DEF_ SG_  "GenSigStartValue" INT 0 10000;
BA_DEF_ SG_  "GenSigSendType" ENUM  "Cyclic","OnWrite","reserved","OnChange","reserved","reserved","reserved","NoSigSendType";
BA_DEF_ SG_  "GenSigILSupport" ENUM  "Yes","No";
BA_DEF_ SG_  "GenSigEVName" STRING ;
BA_DEF_ SG_  "SPN" INT 0 524287;
BA_DEF_ BO_  "GenMsgStartDelayTime" INT 0 100000;
BA_DEF_ BO_  "GenMsgILSupport" ENUM  "Yes","No";
BA_DEF_ BO_  "GenMsgRequestable" INT 0 1;
BA_DEF_ BO_  "GenMsgSendType" ENUM  "cyclic","reserved","cyclicIfActive","reserved","reserved","reserved","reserved","reserved","noMsgSendType";
BA_DEF_ BO_  "VFrameFormat" ENUM  "StandardCAN","ExtendedCAN","reserved","J1939PG";
BA_DEF_ BO_  "GenMsgCycleTime" INT 0 3600000;
BA_DEF_ SG_  "SystemSignalLongSymbol" STRING ;
BA_DEF_DEF_  "SigType" "Default";
BA_DEF_DEF_  "GenSigStartValue" 0;
BA_DEF_DEF_  "GenSigSendType" "NoSigSendType";
BA_DEF_DEF_  "GenSigILSupport" "Yes";
BA_DEF_DEF_  "GenSigEVName" "Env@Nodename_@Signame";
BA_DEF_DEF_  "SPN" 0;
BA_DEF_DEF_  "GenMsgStartDelayTime" 0;
BA_DEF_DEF_  "GenMsgILSupport" "Yes";
BA_DEF_DEF_  "GenMsgRequestable" 1;
BA_DEF_DEF_  "GenMsgSendType" "noMsgSendType";
BA_DEF_DEF_  "VFrameFormat" "J1939PG";
BA_DEF_DEF_  "GenMsgCycleTime" 0;
BA_DEF_DEF_  "SystemSignalLongSymbol" "";
BA_ "GenMsgCycleTime" BO_ 2365479678 100;
BA_ "GenMsgSendType" BO_ 2365479678 0;
BA_ "GenMsgCycleTime" BO_ 2566837758 1000;
BA_ "GenMsgSendType" BO_ 2566837758 0;
BA_ "GenMsgCycleTime" BO_ 2566775038 1000;
BA_ "GenMsgSendType" BO_ 2566775038 0;
BA_ "GenMsgCycleTime" BO_ 2432520702 1000;
BA_ "GenMsgSendType" BO_ 2432520702 0;
BA_ "GenMsgCycleTime" BO_ 2499630078 500;
BA_ "GenMsgSendType" BO_ 2499630078 0;
BA_ "GenMsgCycleTime" BO_ 2566746622 1000;
BA_ "GenMsgSendType" BO_ 2566746622 0;
BA_ "GenMsgCycleTime" BO_ 2566845950 1000;
BA_ "GenMsgSendType" BO_ 2566845950 0;
BA_ "GenMsgCycleTime" BO_ 2566827774 1000;
BA_ "GenMsgSendType" BO_ 2566827774 0;
BA_ "GenMsgCycleTime" BO_ 2566846974 1000;
BA_ "GenMsgSendType" BO_ 2566846974 0;
BA_ "GenMsgCycleTime" BO_ 2566803966 250;
BA_ "GenMsgSendType" BO_ 2566803966 0;
BA_ "GenMsgCycleTime" BO_ 2432593918 100;
BA_ "GenMsgSendType" BO_ 2432593918 0;
BA_ "GenMsgCycleTime" BO_ 2566847998 500;
BA_ "GenMsgSendType" BO_ 2566847998 0;
BA_ "GenMsgCycleTime" BO_ 2566803198 100;
BA_ "GenMsgSendType" BO_ 2566803198 0;
BA_ "GenMsgCycleTime" BO_ 2565870334 50;
BA_ "GenMsgSendType" BO_ 2565870334 0;
BA_ "GenMsgCycleTime" BO_ 2364543998 10;
BA_ "GenMsgSendType" BO_ 2364543998 0;
BA_ "GenMsgCycleTime" BO_ 2566846718 1000;
BA_ "GenMsgSendType" BO_ 2566846718 0;
BA_ "GenMsgCycleTime" BO_ 2566846462 1000;
BA_ "GenMsgSendType" BO_ 2566846462 0;
BA_ "SPN" SG_ 2365479678 SpeedDependantLevelCtrlStatus 5296;
BA_ "SigType" SG_ 2365479678 SpeedDependantLevelCtrlStatus 4;
BA_ "SPN" SG_ 2365479678 MemoryLevel 5432;
BA_ "SigType" SG_ 2365479678 MemoryLevel 4;
BA_ "SPN" SG_ 2365479678 AllwLvelCtrlDuringBrakingStatus 5294;
BA_ "SigType" SG_ 2365479678 AllwLvelCtrlDuringBrakingStatus 4;
BA_ "SPN" SG_ 2365479678 SspensionCtrlRefusalInformation 1827;
BA_ "SigType" SG_ 2365479678 SspensionCtrlRefusalInformation 4;
BA_ "SPN" SG_ 2365479678 SuspensionRemoteCtrl2 1825;
BA_ "SigType" SG_ 2365479678 SuspensionRemoteCtrl2 4;
BA_ "SPN" SG_ 2365479678 SuspensionRemoteCtrl1 1826;
BA_ "SigType" SG_ 2365479678 SuspensionRemoteCtrl1 4;
BA_ "SPN" SG_ 2365479678 RearAxleInBumperRange 1823;
BA_ "SigType" SG_ 2365479678 RearAxleInBumperRange 4;
BA_ "SPN" SG_ 2365479678 FrontAxleInBumperRange 1824;
BA_ "SigType" SG_ 2365479678 FrontAxleInBumperRange 4;
BA_ "SPN" SG_ 2365479678 DoorRelease 1744;
BA_ "SigType" SG_ 2365479678 DoorRelease 4;
BA_ "SPN" SG_ 2365479678 VehicleMotionInhibit 1745;
BA_ "SigType" SG_ 2365479678 VehicleMotionInhibit 4;
BA_ "SPN" SG_ 2365479678 SecurityDevice 1746;
BA_ "SigType" SG_ 2365479678 SecurityDevice 4;
BA_ "SPN" SG_ 2365479678 LevelCtrlMode 1741;
BA_ "SigType" SG_ 2365479678 LevelCtrlMode 4;
BA_ "SPN" SG_ 2365479678 KneelingInformation 1742;
BA_ "SigType" SG_ 2365479678 KneelingInformation 4;
BA_ "SPN" SG_ 2365479678 LiftingCtrlModeRearAxle 1756;
BA_ "SigType" SG_ 2365479678 LiftingCtrlModeRearAxle 4;
BA_ "SPN" SG_ 2365479678 LiftingCtrlModeFrontAxle 1739;
BA_ "SigType" SG_ 2365479678 LiftingCtrlModeFrontAxle 4;
BA_ "SPN" SG_ 2365479678 LoweringCtrlModeRearAxle 1755;
BA_ "SigType" SG_ 2365479678 LoweringCtrlModeRearAxle 4;
BA_ "SPN" SG_ 2365479678 LoweringCtrlModeFrontAxle 1740;
BA_ "SigType" SG_ 2365479678 LoweringCtrlModeFrontAxle 4;
BA_ "SPN" SG_ 2365479678 AboveNominalLevelRearAxle 1736;
BA_ "SigType" SG_ 2365479678 AboveNominalLevelRearAxle 4;
BA_ "SPN" SG_ 2365479678 AboveNominalLevelFrontAxle 1737;
BA_ "SigType" SG_ 2365479678 AboveNominalLevelFrontAxle 4;
BA_ "SPN" SG_ 2365479678 BelowNominalLevelRearAxle 1754;
BA_ "SigType" SG_ 2365479678 BelowNominalLevelRearAxle 4;
BA_ "SPN" SG_ 2365479678 BelowNominalLevelFrontAxle 1738;
BA_ "SigType" SG_ 2365479678 BelowNominalLevelFrontAxle 4;
BA_ "SPN" SG_ 2365479678 NominalLevelRearAxle 1733;
BA_ "SigType" SG_ 2365479678 NominalLevelRearAxle 4;
BA_ "SPN" SG_ 2365479678 NominalLevelFrontAxle 1734;
BA_ "SigType" SG_ 2365479678 NominalLevelFrontAxle 4;
BA_ "SPN" SG_ 2365479678 LiftAxle2Pos 1822;
BA_ "SigType" SG_ 2365479678 LiftAxle2Pos 4;
BA_ "SPN" SG_ 2365479678 LiftAxle1Pos 1743;
BA_ "SigType" SG_ 2365479678 LiftAxle1Pos 4;
BA_ "SPN" SG_ 2566837758 Alt4Status 3356;
BA_ "SigType" SG_ 2566837758 Alt4Status 4;
BA_ "SPN" SG_ 2566837758 Alt3Status 3355;
BA_ "SigType" SG_ 2566837758 Alt3Status 4;
BA_ "SPN" SG_ 2566837758 Alt2Status 3354;
BA_ "SigType" SG_ 2566837758 Alt2Status 4;
BA_ "SPN" SG_ 2566837758 Alt1Status 3353;
BA_ "SigType" SG_ 2566837758 Alt1Status 4;
BA_ "SPN" SG_ 2566837758 AltSpeed 589;
BA_ "SigType" SG_ 2566837758 AltSpeed 1;
BA_ "SPN" SG_ 2633922558 AuxAbsPressReading 138;
BA_ "SigType" SG_ 2633922558 AuxAbsPressReading 1;
BA_ "SPN" SG_ 2633922558 AuxGagePressReading1 137;
BA_ "SigType" SG_ 2633922558 AuxGagePressReading1 1;
BA_ "SPN" SG_ 2633922558 AuxVacuumPressReading 136;
BA_ "SigType" SG_ 2633922558 AuxVacuumPressReading 1;
BA_ "SPN" SG_ 2566775038 SpecificHumidity 4490;
BA_ "SigType" SG_ 2566775038 SpecificHumidity 1;
BA_ "SPN" SG_ 2566775038 SolarSensorMax 2611;
BA_ "SigType" SG_ 2566775038 SolarSensorMax 1;
BA_ "SPN" SG_ 2566775038 SolarIntensityPercent 2610;
BA_ "SigType" SG_ 2566775038 SolarIntensityPercent 1;
BA_ "SPN" SG_ 2566836478 TestLimitMinimum 1228;
BA_ "SigType" SG_ 2566836478 TestLimitMinimum 1;
BA_ "SPN" SG_ 2566836478 TestLimitMaximum 1227;
BA_ "SigType" SG_ 2566836478 TestLimitMaximum 1;
BA_ "SPN" SG_ 2566836478 TestValue 1226;
BA_ "SigType" SG_ 2566836478 TestValue 1;
BA_ "SPN" SG_ 2566836478 TestType 1225;
BA_ "GenSigStartValue" SG_ 2566836478 TestType 1;
BA_ "SigType" SG_ 2566836478 TestType 1;
BA_ "SPN" SG_ 2566836478 TestIdentifier 1224;
BA_ "GenSigStartValue" SG_ 2566836478 TestIdentifier 1;
BA_ "SigType" SG_ 2566836478 TestIdentifier 1;
BA_ "SPN" SG_ 2565078782 SPN1High 1214;
BA_ "SPN" SG_ 2565078782 SPN1 1214;
BA_ "SPN" SG_ 2565078782 TestIdentifier 1224;
BA_ "GenSigStartValue" SG_ 2565078782 TestIdentifier 1;
BA_ "SigType" SG_ 2565078782 TestIdentifier 1;
BA_ "SPN" SG_ 2565078782 FailureModeIdentifier1 1215;
BA_ "SystemSignalLongSymbol" SG_ 2566835966 NOxConvertingCatalystAdsorberSta "NOxConvertingCatalystAdsorberStatus";
BA_ "SystemSignalLongSymbol" SG_ 2566835966 BoostPressureControlSystemSuppor "BoostPressureControlSystemSupport";
BA_ "SystemSignalLongSymbol" SG_ 2566835966 NOxConvertingCatalystAdsorberSup "NOxConvertingCatalystAdsorberSupport";
BA_ "SPN" SG_ 2566835966 MisfireMonitoringSupport 1221;
BA_ "SPN" SG_ 2566835966 OBDCompliance 1220;
BA_ "SigType" SG_ 2566835966 OBDCompliance 1;
BA_ "SPN" SG_ 2566835966 PreviouslyActiveTroubleCodes 1219;
BA_ "SigType" SG_ 2566835966 PreviouslyActiveTroubleCodes 1;
BA_ "SPN" SG_ 2566835966 ActiveTroubleCodes 1218;
BA_ "SigType" SG_ 2566835966 ActiveTroubleCodes 1;
BA_ "SPN" SG_ 2566835966 SecondAirSystemMonStatus 1223;
BA_ "SPN" SG_ 2566835966 EvaporativeSystemMonStatus 1223;
BA_ "SPN" SG_ 2566835966 ACSystemRefrigerantMonStatus 1223;
BA_ "SPN" SG_ 2566835966 OxygenSensorHeaterMonStatus 1223;
BA_ "SPN" SG_ 2566835966 OxygenSensorMonStatus 1223;
BA_ "SPN" SG_ 2566835966 EGRSystemMonitoringStatus 1223;
BA_ "SPN" SG_ 2566835966 CatalystMonStatus 1223;
BA_ "SPN" SG_ 2566835966 ColdStartAidSystemMonStatus 1223;
BA_ "SPN" SG_ 2566835966 HeatedCatalystMonStatus 1223;
BA_ "SPN" SG_ 2566835966 CatalystMonSupp 1222;
BA_ "SPN" SG_ 2566835966 ColdStartAidSystemMonSupp 1222;
BA_ "SPN" SG_ 2566835966 HeatedCatalystMonSupp 1222;
BA_ "SPN" SG_ 2566835966 EvaporativeSystemMonSupp 1222;
BA_ "SPN" SG_ 2566835966 SecondAirSystemMonSupp 1222;
BA_ "SPN" SG_ 2566835966 ACSystemRefrigerantMonSupp 1222;
BA_ "SPN" SG_ 2566835966 OxygenSensorMonSupp 1222;
BA_ "SPN" SG_ 2566835966 OxygenSensorHeaterMonSupp 1222;
BA_ "SPN" SG_ 2566835966 EGRSystemMonitoringSupp 1222;
BA_ "SPN" SG_ 2566835966 MisfireMonitoringStatus 1221;
BA_ "SPN" SG_ 2566835966 ComprehensiveCompMonStatus 1221;
BA_ "SPN" SG_ 2566835966 FuelSystemMonitoringStatus 1221;
BA_ "SPN" SG_ 2566835966 ComprehensiveComponentMonSupp 1221;
BA_ "SPN" SG_ 2566835966 FuelSystemMonitoringSupport 1221;
BA_ "SPN" SG_ 2562981630 IndividualDTCClearControlByte 3034;
BA_ "SPN" SG_ 2562981630 CtrlByteIndicIndividualDTCClear 3035;
BA_ "SPN" SG_ 2562981630 SPN1 1214;
BA_ "SPN" SG_ 2562981630 SPN1High 1214;
BA_ "SPN" SG_ 2562981630 FailureModeIdentifier1 1215;
BA_ "SPN" SG_ 2562850558 TimeSinceDTCsCleared 3145;
BA_ "SigType" SG_ 2562850558 TimeSinceDTCsCleared 1;
BA_ "SPN" SG_ 2562850558 MinutesRunByEngineMILActivated 3144;
BA_ "SigType" SG_ 2562850558 MinutesRunByEngineMILActivated 1;
BA_ "SPN" SG_ 2562850558 DistanceSinceDTCsCleared 3143;
BA_ "SigType" SG_ 2562850558 DistanceSinceDTCsCleared 1;
BA_ "SPN" SG_ 2562850558 DistanceWhileMILisActivated 3069;
BA_ "SigType" SG_ 2562850558 DistanceWhileMILisActivated 1;
BA_ "SPN" SG_ 2564423422 KeyOrUserLevel 1645;
BA_ "SPN" SG_ 2564423422 PointerExtension 1643;
BA_ "SPN" SG_ 2564423422 Pointer 1644;
BA_ "SPN" SG_ 2564423422 Command 1642;
BA_ "SPN" SG_ 2564423422 PointerType 1641;
BA_ "SPN" SG_ 2564423422 NumberRequested 1640;
BA_ "SPN" SG_ 2564423422 NumberRequestedHigh 1640;
BA_ "SPN" SG_ 2564816638 HoldSignal 1236;
BA_ "SPN" SG_ 2564816638 J1939Network3 1235;
BA_ "SigType" SG_ 2564816638 J1939Network3 4;
BA_ "SPN" SG_ 2564816638 J1939Network2 1231;
BA_ "SigType" SG_ 2564816638 J1939Network2 4;
BA_ "SPN" SG_ 2564816638 ISO9141 1232;
BA_ "SigType" SG_ 2564816638 ISO9141 4;
BA_ "SPN" SG_ 2564816638 SAE_J1850 1233;
BA_ "SigType" SG_ 2564816638 SAE_J1850 4;
BA_ "SPN" SG_ 2564816638 ManufacturerSpecificPort 1234;
BA_ "SigType" SG_ 2564816638 ManufacturerSpecificPort 4;
BA_ "SPN" SG_ 2564816638 CurrentDataLink 1230;
BA_ "SigType" SG_ 2564816638 CurrentDataLink 4;
BA_ "SPN" SG_ 2564816638 SAE_J1587 608;
BA_ "SigType" SG_ 2564816638 SAE_J1587 4;
BA_ "SPN" SG_ 2564816638 SAE_J1922 622;
BA_ "SigType" SG_ 2564816638 SAE_J1922 4;
BA_ "SPN" SG_ 2564816638 J1939Network1 639;
BA_ "SigType" SG_ 2564816638 J1939Network1 4;
BA_ "SPN" SG_ 2564816638 SuspendSignal 2618;
BA_ "SPN" SG_ 2564816638 SuspendDuration 2619;
BA_ "SPN" SG_ 2566836990 TestIdentifierSupported 1229;
BA_ "GenSigStartValue" SG_ 2566836990 TestIdentifierSupported 1;
BA_ "SigType" SG_ 2566836990 TestIdentifierSupported 1;
BA_ "SPN" SG_ 2566780926 UtlityOverallPowerFactorLagging 2522;
BA_ "SigType" SG_ 2566780926 UtlityOverallPowerFactorLagging 4;
BA_ "SPN" SG_ 2566780926 UtilityOverallPowerFactor 2498;
BA_ "SigType" SG_ 2566780926 UtilityOverallPowerFactor 1;
BA_ "SPN" SG_ 2566780926 UtilityTotalReactivePower 2490;
BA_ "SigType" SG_ 2566780926 UtilityTotalReactivePower 1;
BA_ "SPN" SG_ 2566781182 UtilityTotalApparentPower 2494;
BA_ "SigType" SG_ 2566781182 UtilityTotalApparentPower 1;
BA_ "SPN" SG_ 2566781182 UtilityTotalRealPower 2486;
BA_ "SigType" SG_ 2566781182 UtilityTotalRealPower 1;
BA_ "SPN" SG_ 2566778366 UtilityTotalKWHoursImport 2503;
BA_ "SigType" SG_ 2566778366 UtilityTotalKWHoursImport 4;
BA_ "SPN" SG_ 2566778366 UtilityTotalKWHoursExport 2502;
BA_ "SigType" SG_ 2566778366 UtilityTotalKWHoursExport 4;
BA_ "SPN" SG_ 2566778622 UtilityPhaseCPowerFactorLagging 2525;
BA_ "SigType" SG_ 2566778622 UtilityPhaseCPowerFactorLagging 4;
BA_ "SPN" SG_ 2566778622 UtilityPhaseCPowerFactor 2501;
BA_ "SigType" SG_ 2566778622 UtilityPhaseCPowerFactor 1;
BA_ "SPN" SG_ 2566778622 UtilityPhaseCReactivePower 2493;
BA_ "SigType" SG_ 2566778622 UtilityPhaseCReactivePower 1;
BA_ "SPN" SG_ 2566778878 UtilityPhaseCApparentPower 2497;
BA_ "SigType" SG_ 2566778878 UtilityPhaseCApparentPower 1;
BA_ "SPN" SG_ 2566778878 UtilityPhaseCRealPower 2489;
BA_ "SigType" SG_ 2566778878 UtilityPhaseCRealPower 1;
BA_ "SPN" SG_ 2566779134 UtilityPhaseCACRMSCurrent 2485;
BA_ "SigType" SG_ 2566779134 UtilityPhaseCACRMSCurrent 1;
BA_ "SPN" SG_ 2566779134 UtilityPhaseCACFrequency 2473;
BA_ "SigType" SG_ 2566779134 UtilityPhaseCACFrequency 1;
BA_ "SPN" SG_ 2566779134 UtltyPhsCLneNeutralACRMSVoltage 2481;
BA_ "SigType" SG_ 2566779134 UtltyPhsCLneNeutralACRMSVoltage 1;
BA_ "SPN" SG_ 2566779134 UtltyPhseCALineLineACRMSVoltage 2477;
BA_ "SigType" SG_ 2566779134 UtltyPhseCALineLineACRMSVoltage 1;
BA_ "SPN" SG_ 2566779390 UtilityPhaseBPowerFactorLagging 2524;
BA_ "SigType" SG_ 2566779390 UtilityPhaseBPowerFactorLagging 4;
BA_ "SPN" SG_ 2566779390 UtilityPhaseBPowerFactor 2500;
BA_ "SigType" SG_ 2566779390 UtilityPhaseBPowerFactor 1;
BA_ "SPN" SG_ 2566779390 UtilityPhaseBReactivePower 2492;
BA_ "SigType" SG_ 2566779390 UtilityPhaseBReactivePower 1;
BA_ "SPN" SG_ 2566779646 UtilityPhaseBApparentPower 2496;
BA_ "SigType" SG_ 2566779646 UtilityPhaseBApparentPower 1;
BA_ "SPN" SG_ 2566779646 UtilityPhaseBRealPower 2488;
BA_ "SigType" SG_ 2566779646 UtilityPhaseBRealPower 1;
BA_ "SPN" SG_ 2566779902 UtilityPhaseBACRMSCurrent 2484;
BA_ "SigType" SG_ 2566779902 UtilityPhaseBACRMSCurrent 1;
BA_ "SPN" SG_ 2566779902 UtilityPhaseBACFrequency 2472;
BA_ "SigType" SG_ 2566779902 UtilityPhaseBACFrequency 1;
BA_ "SPN" SG_ 2566779902 UtltyPhsBLneNeutralACRMSVoltage 2480;
BA_ "SigType" SG_ 2566779902 UtltyPhsBLneNeutralACRMSVoltage 1;
BA_ "SPN" SG_ 2566779902 UtltyPhseBCLineLineACRMSVoltage 2476;
BA_ "SigType" SG_ 2566779902 UtltyPhseBCLineLineACRMSVoltage 1;
BA_ "SPN" SG_ 2566780158 UtilityPhaseAPowerFactorLagging 2523;
BA_ "SigType" SG_ 2566780158 UtilityPhaseAPowerFactorLagging 4;
BA_ "SPN" SG_ 2566780158 UtilityPhaseAPowerFactor 2499;
BA_ "SigType" SG_ 2566780158 UtilityPhaseAPowerFactor 1;
BA_ "SPN" SG_ 2566780158 UtilityPhaseAReactivePower 2491;
BA_ "SigType" SG_ 2566780158 UtilityPhaseAReactivePower 1;
BA_ "SPN" SG_ 2566780414 UtilityPhaseAApparentPower 2495;
BA_ "SigType" SG_ 2566780414 UtilityPhaseAApparentPower 1;
BA_ "SPN" SG_ 2566780414 UtilityPhaseARealPower 2487;
BA_ "SigType" SG_ 2566780414 UtilityPhaseARealPower 1;
BA_ "SPN" SG_ 2566780670 UtilityPhaseAACRMSCurrent 2483;
BA_ "SigType" SG_ 2566780670 UtilityPhaseAACRMSCurrent 1;
BA_ "SPN" SG_ 2566780670 UtilityPhaseAACFrequency 2471;
BA_ "SigType" SG_ 2566780670 UtilityPhaseAACFrequency 1;
BA_ "SPN" SG_ 2566780670 UtltyPhsALneNeutralACRMSVoltage 2479;
BA_ "SigType" SG_ 2566780670 UtltyPhsALneNeutralACRMSVoltage 1;
BA_ "SPN" SG_ 2566780670 UtltyPhseABLineLineACRMSVoltage 2475;
BA_ "SigType" SG_ 2566780670 UtltyPhseABLineLineACRMSVoltage 1;
BA_ "SPN" SG_ 2566781438 UtilityAverageACRMSCurrent 2482;
BA_ "SigType" SG_ 2566781438 UtilityAverageACRMSCurrent 1;
BA_ "SPN" SG_ 2566781438 UtilityAverageACFrequency 2470;
BA_ "SigType" SG_ 2566781438 UtilityAverageACFrequency 1;
BA_ "SPN" SG_ 2566781438 UtltyAvrgLneNeutralACRMSVoltage 2478;
BA_ "SigType" SG_ 2566781438 UtltyAvrgLneNeutralACRMSVoltage 1;
BA_ "SPN" SG_ 2566781438 UtltyAvrageLineLineACRMSVoltage 2474;
BA_ "SigType" SG_ 2566781438 UtltyAvrageLineLineACRMSVoltage 1;
BA_ "SPN" SG_ 2566784254 GnrtorOverallPowerFactorLagging 2518;
BA_ "SigType" SG_ 2566784254 GnrtorOverallPowerFactorLagging 4;
BA_ "SPN" SG_ 2566784254 GeneratorOverallPowerFactor 2464;
BA_ "SigType" SG_ 2566784254 GeneratorOverallPowerFactor 1;
BA_ "SPN" SG_ 2566784254 GeneratorTotalReactivePower 2456;
BA_ "SigType" SG_ 2566784254 GeneratorTotalReactivePower 1;
BA_ "SPN" SG_ 2566784510 GeneratorTotalApparentPower 2460;
BA_ "SigType" SG_ 2566784510 GeneratorTotalApparentPower 1;
BA_ "SPN" SG_ 2566784510 GeneratorTotalRealPower 2452;
BA_ "SigType" SG_ 2566784510 GeneratorTotalRealPower 1;
BA_ "SPN" SG_ 2566781694 GeneratorTotalKWHoursImport 2469;
BA_ "SigType" SG_ 2566781694 GeneratorTotalKWHoursImport 4;
BA_ "SPN" SG_ 2566781694 GeneratorTotalKWHoursExport 2468;
BA_ "SigType" SG_ 2566781694 GeneratorTotalKWHoursExport 4;
BA_ "SPN" SG_ 2566781950 GnratorPhaseCPowerFactorLagging 2521;
BA_ "SigType" SG_ 2566781950 GnratorPhaseCPowerFactorLagging 4;
BA_ "SPN" SG_ 2566781950 GeneratorPhaseCPowerFactor 2467;
BA_ "SigType" SG_ 2566781950 GeneratorPhaseCPowerFactor 1;
BA_ "SPN" SG_ 2566781950 GeneratorPhaseCReactivePower 2459;
BA_ "SigType" SG_ 2566781950 GeneratorPhaseCReactivePower 1;
BA_ "SPN" SG_ 2566782206 GeneratorPhaseCApparentPower 2463;
BA_ "SigType" SG_ 2566782206 GeneratorPhaseCApparentPower 1;
BA_ "SPN" SG_ 2566782206 GeneratorPhaseCRealPower 2455;
BA_ "SigType" SG_ 2566782206 GeneratorPhaseCRealPower 1;
BA_ "SPN" SG_ 2566782462 GeneratorPhaseCACRMSCurrent 2451;
BA_ "SigType" SG_ 2566782462 GeneratorPhaseCACRMSCurrent 1;
BA_ "SPN" SG_ 2566782462 GeneratorPhaseCACFrequency 2439;
BA_ "SigType" SG_ 2566782462 GeneratorPhaseCACFrequency 1;
BA_ "SPN" SG_ 2566782462 GnrtrPhsCLneNeutralACRMSVoltage 2447;
BA_ "SigType" SG_ 2566782462 GnrtrPhsCLneNeutralACRMSVoltage 1;
BA_ "SPN" SG_ 2566782462 GnrtrPhseCALineLineACRMSVoltage 2443;
BA_ "SigType" SG_ 2566782462 GnrtrPhseCALineLineACRMSVoltage 1;
BA_ "SPN" SG_ 2566782718 GnratorPhaseBPowerFactorLagging 2520;
BA_ "SigType" SG_ 2566782718 GnratorPhaseBPowerFactorLagging 4;
BA_ "SPN" SG_ 2566782718 GeneratorPhaseBPowerFactor 2466;
BA_ "SigType" SG_ 2566782718 GeneratorPhaseBPowerFactor 1;
BA_ "SPN" SG_ 2566782718 GeneratorPhaseBReactivePower 2458;
BA_ "SigType" SG_ 2566782718 GeneratorPhaseBReactivePower 1;
BA_ "SPN" SG_ 2566782974 GeneratorPhaseBApparentPower 2462;
BA_ "SigType" SG_ 2566782974 GeneratorPhaseBApparentPower 1;
BA_ "SPN" SG_ 2566782974 GeneratorPhaseBRealPower 2454;
BA_ "SigType" SG_ 2566782974 GeneratorPhaseBRealPower 1;
BA_ "SPN" SG_ 2566783230 GeneratorPhaseBACRMSCurrent 2450;
BA_ "SigType" SG_ 2566783230 GeneratorPhaseBACRMSCurrent 1;
BA_ "SPN" SG_ 2566783230 GeneratorPhaseBACFrequency 2438;
BA_ "SigType" SG_ 2566783230 GeneratorPhaseBACFrequency 1;
BA_ "SPN" SG_ 2566783230 GnrtrPhsBLneNeutralACRMSVoltage 2446;
BA_ "SigType" SG_ 2566783230 GnrtrPhsBLneNeutralACRMSVoltage 1;
BA_ "SPN" SG_ 2566783230 GnrtrPhseBCLineLineACRMSVoltage 2442;
BA_ "SigType" SG_ 2566783230 GnrtrPhseBCLineLineACRMSVoltage 1;
BA_ "SPN" SG_ 2566783486 GnratorPhaseAPowerFactorLagging 2519;
BA_ "SigType" SG_ 2566783486 GnratorPhaseAPowerFactorLagging 4;
BA_ "SPN" SG_ 2566783486 GeneratorPhaseAPowerFactor 2465;
BA_ "SigType" SG_ 2566783486 GeneratorPhaseAPowerFactor 1;
BA_ "SPN" SG_ 2566783486 GeneratorPhaseAReactivePower 2457;
BA_ "SigType" SG_ 2566783486 GeneratorPhaseAReactivePower 1;
BA_ "SPN" SG_ 2566783742 GeneratorPhaseAApparentPower 2461;
BA_ "SigType" SG_ 2566783742 GeneratorPhaseAApparentPower 1;
BA_ "SPN" SG_ 2566783742 GeneratorPhaseARealPower 2453;
BA_ "SigType" SG_ 2566783742 GeneratorPhaseARealPower 1;
BA_ "SPN" SG_ 2566783998 GeneratorPhaseAACRMSCurrent 2449;
BA_ "SigType" SG_ 2566783998 GeneratorPhaseAACRMSCurrent 1;
BA_ "SPN" SG_ 2566783998 GeneratorPhaseAACFrequency 2437;
BA_ "SigType" SG_ 2566783998 GeneratorPhaseAACFrequency 1;
BA_ "SPN" SG_ 2566783998 GnrtrPhsALneNeutralACRMSVoltage 2445;
BA_ "SigType" SG_ 2566783998 GnrtrPhsALneNeutralACRMSVoltage 1;
BA_ "SPN" SG_ 2566783998 GnrtrPhseABLineLineACRMSVoltage 2441;
BA_ "SigType" SG_ 2566783998 GnrtrPhseABLineLineACRMSVoltage 1;
BA_ "SPN" SG_ 2566784766 GeneratorAverageACRMSCurrent 2448;
BA_ "SigType" SG_ 2566784766 GeneratorAverageACRMSCurrent 1;
BA_ "SPN" SG_ 2566784766 GeneratorAverageACFrequency 2436;
BA_ "SigType" SG_ 2566784766 GeneratorAverageACFrequency 1;
BA_ "SPN" SG_ 2566784766 GnrtrAvrgLneNeutralACRMSVoltage 2444;
BA_ "SigType" SG_ 2566784766 GnrtrAvrgLneNeutralACRMSVoltage 1;
BA_ "SPN" SG_ 2566784766 GnrtrAvrageLineLineACRMSVoltage 2440;
BA_ "SigType" SG_ 2566784766 GnrtrAvrageLineLineACRMSVoltage 1;
BA_ "SPN" SG_ 2566776830 Bus1_UtilityACPhaseDifference 2517;
BA_ "SigType" SG_ 2566776830 Bus1_UtilityACPhaseDifference 1;
BA_ "SPN" SG_ 2566776830 Bus1_UtilityInSync 2534;
BA_ "SigType" SG_ 2566776830 Bus1_UtilityInSync 4;
BA_ "SPN" SG_ 2566776830 Bus1_UtilityVoltageMatch 2532;
BA_ "SigType" SG_ 2566776830 Bus1_UtilityVoltageMatch 4;
BA_ "SPN" SG_ 2566776830 Bus1_UtilityFrequencyMatch 2533;
BA_ "SigType" SG_ 2566776830 Bus1_UtilityFrequencyMatch 4;
BA_ "SPN" SG_ 2566776830 Bus1_UtilityPhaseMatch 2531;
BA_ "SigType" SG_ 2566776830 Bus1_UtilityPhaseMatch 4;
BA_ "SPN" SG_ 2566776830 Bus1_UtilityDeadBus 2535;
BA_ "SigType" SG_ 2566776830 Bus1_UtilityDeadBus 4;
BA_ "SPN" SG_ 2566777342 Bus1PhaseCACFrequency 2507;
BA_ "SigType" SG_ 2566777342 Bus1PhaseCACFrequency 1;
BA_ "SPN" SG_ 2566777342 Bs1PhseCLineNeutralACRMSVoltage 2515;
BA_ "SigType" SG_ 2566777342 Bs1PhseCLineNeutralACRMSVoltage 1;
BA_ "SPN" SG_ 2566777342 Bus1PhaseCALineLineACRMSVoltage 2511;
BA_ "SigType" SG_ 2566777342 Bus1PhaseCALineLineACRMSVoltage 1;
BA_ "SPN" SG_ 2566777598 Bus1PhaseBACFrequency 2506;
BA_ "SigType" SG_ 2566777598 Bus1PhaseBACFrequency 1;
BA_ "SPN" SG_ 2566777598 Bs1PhseBLineNeutralACRMSVoltage 2514;
BA_ "SigType" SG_ 2566777598 Bs1PhseBLineNeutralACRMSVoltage 1;
BA_ "SPN" SG_ 2566777598 Bus1PhaseBCLineLineACRMSVoltage 2510;
BA_ "SigType" SG_ 2566777598 Bus1PhaseBCLineLineACRMSVoltage 1;
BA_ "SPN" SG_ 2566777854 Bus1PhaseAACFrequency 2505;
BA_ "SigType" SG_ 2566777854 Bus1PhaseAACFrequency 1;
BA_ "SPN" SG_ 2566777854 Bs1PhseALineNeutralACRMSVoltage 2513;
BA_ "SigType" SG_ 2566777854 Bs1PhseALineNeutralACRMSVoltage 1;
BA_ "SPN" SG_ 2566777854 Bus1PhaseABLineLineACRMSVoltage 2509;
BA_ "SigType" SG_ 2566777854 Bus1PhaseABLineLineACRMSVoltage 1;
BA_ "SPN" SG_ 2566777086 Bus1_GeneratorACPhaseDifference 2516;
BA_ "SigType" SG_ 2566777086 Bus1_GeneratorACPhaseDifference 1;
BA_ "SPN" SG_ 2566777086 Bus1_GeneratorInSync 2529;
BA_ "SigType" SG_ 2566777086 Bus1_GeneratorInSync 4;
BA_ "SPN" SG_ 2566777086 Bus1_GeneratorVoltageMatch 2527;
BA_ "SigType" SG_ 2566777086 Bus1_GeneratorVoltageMatch 4;
BA_ "SPN" SG_ 2566777086 Bus1_GeneratorFrequencyMatch 2528;
BA_ "SigType" SG_ 2566777086 Bus1_GeneratorFrequencyMatch 4;
BA_ "SPN" SG_ 2566777086 Bus1_GeneratorPhaseMatch 2526;
BA_ "SigType" SG_ 2566777086 Bus1_GeneratorPhaseMatch 4;
BA_ "SPN" SG_ 2566777086 Bus1_GeneratorDeadBus 2530;
BA_ "SigType" SG_ 2566777086 Bus1_GeneratorDeadBus 4;
BA_ "SPN" SG_ 2566778110 Bus1AverageACFrequency 2504;
BA_ "SigType" SG_ 2566778110 Bus1AverageACFrequency 1;
BA_ "SPN" SG_ 2566778110 Bs1AvrgeLineNeutralACRMSVoltage 2512;
BA_ "SigType" SG_ 2566778110 Bs1AvrgeLineNeutralACRMSVoltage 1;
BA_ "SPN" SG_ 2566778110 Bus1AverageLineLineACRMSVoltage 2508;
BA_ "SigType" SG_ 2566778110 Bus1AverageLineLineACRMSVoltage 1;
BA_ "SigType" SG_ 2633895422 NumberOfMembers 3;
BA_ "SPN" SG_ 2563440382 ShrtNameOfActualReportingDevice 2554;
BA_ "SigType" SG_ 2563440382 ShrtNameOfActualReportingDevice 4;
BA_ "SPN" SG_ 2563440382 LengthOfDataForTheReportedPGN 2553;
BA_ "SigType" SG_ 2563440382 LengthOfDataForTheReportedPGN 1;
BA_ "SPN" SG_ 2563440382 PGNofRequstedInformation 2552;
BA_ "SigType" SG_ 2563440382 PGNofRequstedInformation 6;
BA_ "SPN" SG_ 2632711934 SequenceNumber 2572;
BA_ "SPN" SG_ 2632777470 TotalNumberOfPacketsEoMA 2558;
BA_ "SPN" SG_ 2632777470 TotalMessageSizeEoMA 2557;
BA_ "SPN" SG_ 2632777470 TotalMessageSizeBAM 2557;
BA_ "SPN" SG_ 2632777470 TotalNumberOfPacketsBAM 2558;
BA_ "SPN" SG_ 2632777470 ConnectionAbortReason 2570;
BA_ "SPN" SG_ 2632777470 NextPacketNumberToBeSent 2562;
BA_ "SPN" SG_ 2632777470 NumberOfPacketsThatCanBeSent 2561;
BA_ "SPN" SG_ 2632777470 PGNumber 2560;
BA_ "SigType" SG_ 2632777470 PGNumber 6;
BA_ "SPN" SG_ 2632777470 MaximumNumberOfPackets 2559;
BA_ "SPN" SG_ 2632777470 TotalNumberOfPackets 2558;
BA_ "SPN" SG_ 2632777470 TotalMessageSize 2557;
BA_ "SPN" SG_ 2632777470 ControlByte 2556;
BA_ "SPN" SG_ 2563374846 UseTransferMode 2575;
BA_ "SigType" SG_ 2563374846 UseTransferMode 4;
BA_ "SPN" SG_ 2563374846 ParameterGroupNumber 2574;
BA_ "SigType" SG_ 2563374846 ParameterGroupNumber 6;
BA_ "SPN" SG_ 2565537534 ParameterGroupNumber 2574;
BA_ "SigType" SG_ 2565537534 ParameterGroupNumber 6;
BA_ "SPN" SG_ 2499635966 AxleGroupWeight 409;
BA_ "SigType" SG_ 2499635966 AxleGroupWeight 1;
BA_ "SPN" SG_ 2499635966 AxleGroupLocation 4073;
BA_ "SigType" SG_ 2499635966 AxleGroupLocation 4;
BA_ "SPN" SG_ 2633853438 AxleGroupLocation 4074;
BA_ "SigType" SG_ 2633853438 AxleGroupLocation 4;
BA_ "SPN" SG_ 2633853438 AxleGroupFullWeightCalib 407;
BA_ "SigType" SG_ 2633853438 AxleGroupFullWeightCalib 1;
BA_ "SPN" SG_ 2633853438 AxleGroupEmptyWeightCalib 408;
BA_ "SigType" SG_ 2633853438 AxleGroupEmptyWeightCalib 1;
BA_ "SPN" SG_ 2432520702 DsrdAftrcoolerCoolantIntakeTemp 4199;
BA_ "SigType" SG_ 2432520702 DsrdAftrcoolerCoolantIntakeTemp 1;
BA_ "SPN" SG_ 2432520702 DsrdAftrclrClntThrmostatOpening 4200;
BA_ "SigType" SG_ 2432520702 DsrdAftrclrClntThrmostatOpening 1;
BA_ "SPN" SG_ 2432520702 AftrcoolerCoolantThermostatMode 4198;
BA_ "SigType" SG_ 2432520702 AftrcoolerCoolantThermostatMode 4;
BA_ "SPN" SG_ 2566745086 AddtnlTrlrAxlGrpWeightAvailable 4072;
BA_ "SigType" SG_ 2566745086 AddtnlTrlrAxlGrpWeightAvailable 4;
BA_ "SPN" SG_ 2566745086 TrilerHAxleGroupWeightAvailable 4071;
BA_ "SigType" SG_ 2566745086 TrilerHAxleGroupWeightAvailable 4;
BA_ "SPN" SG_ 2566745086 TrilerGAxleGroupWeightAvailable 4070;
BA_ "SigType" SG_ 2566745086 TrilerGAxleGroupWeightAvailable 4;
BA_ "SPN" SG_ 2566745086 TrilerFAxleGroupWeightAvailable 4069;
BA_ "SigType" SG_ 2566745086 TrilerFAxleGroupWeightAvailable 4;
BA_ "SPN" SG_ 2566745086 TrilerEAxleGroupWeightAvailable 4068;
BA_ "SigType" SG_ 2566745086 TrilerEAxleGroupWeightAvailable 4;
BA_ "SPN" SG_ 2566745086 TrilerDAxleGroupWeightAvailable 4067;
BA_ "SigType" SG_ 2566745086 TrilerDAxleGroupWeightAvailable 4;
BA_ "SPN" SG_ 2566745086 TrilerCAxleGroupWeightAvailable 4066;
BA_ "SigType" SG_ 2566745086 TrilerCAxleGroupWeightAvailable 4;
BA_ "SPN" SG_ 2566745086 TrilerBAxleGroupWeightAvailable 4065;
BA_ "SigType" SG_ 2566745086 TrilerBAxleGroupWeightAvailable 4;
BA_ "SPN" SG_ 2566745086 TrilerAAxleGroupWeightAvailable 4064;
BA_ "SigType" SG_ 2566745086 TrilerAAxleGroupWeightAvailable 4;
BA_ "SPN" SG_ 2566745086 AddtnlTrctrAxlGrpWightAvailable 4063;
BA_ "SigType" SG_ 2566745086 AddtnlTrctrAxlGrpWightAvailable 4;
BA_ "SPN" SG_ 2566745086 TagAxleGroupWeightAvailable 4062;
BA_ "SigType" SG_ 2566745086 TagAxleGroupWeightAvailable 4;
BA_ "SPN" SG_ 2566745086 DriveAxleGroupWeightAvailable 4061;
BA_ "SigType" SG_ 2566745086 DriveAxleGroupWeightAvailable 4;
BA_ "SPN" SG_ 2566745086 LiftAxleGroupWeightAvailable 4060;
BA_ "SigType" SG_ 2566745086 LiftAxleGroupWeightAvailable 4;
BA_ "SPN" SG_ 2566745086 SteerAxleGroupWeightAvailable 4059;
BA_ "SigType" SG_ 2566745086 SteerAxleGroupWeightAvailable 4;
BA_ "SPN" SG_ 2566744062 ZeroNetVehicleWeightChange 4075;
BA_ "SigType" SG_ 2566744062 ZeroNetVehicleWeightChange 4;
BA_ "SPN" SG_ 2499630078 EngExhaustGasTempAverageBank2 4152;
BA_ "SigType" SG_ 2499630078 EngExhaustGasTempAverageBank2 1;
BA_ "SPN" SG_ 2499630078 EngExhaustGasTempAverageBank1 4153;
BA_ "SigType" SG_ 2499630078 EngExhaustGasTempAverageBank1 1;
BA_ "SPN" SG_ 2499630078 EngExhaustGasTempAverage 4151;
BA_ "SigType" SG_ 2499630078 EngExhaustGasTempAverage 1;
BA_ "SPN" SG_ 2560556798 PermanentDTCs 4108;
BA_ "SigType" SG_ 2560556798 PermanentDTCs 1;
BA_ "SPN" SG_ 2560556798 PreviouslyMILOnDTCs 4107;
BA_ "SigType" SG_ 2560556798 PreviouslyMILOnDTCs 1;
BA_ "SPN" SG_ 2560556798 MILOnDTCs 4106;
BA_ "SigType" SG_ 2560556798 MILOnDTCs 1;
BA_ "SPN" SG_ 2560556798 AllPendingDTCs 4105;
BA_ "SigType" SG_ 2560556798 AllPendingDTCs 1;
BA_ "SPN" SG_ 2560556798 PendingDTCs 4104;
BA_ "SigType" SG_ 2560556798 PendingDTCs 1;
BA_ "SPN" SG_ 2566754558 AETCSpeedValue 3560;
BA_ "SPN" SG_ 2566754558 AETCTorqueValue 3561;
BA_ "SigType" SG_ 2566754558 AETCTorqueValue 1;
BA_ "SPN" SG_ 2566754558 NumberOfAETCDataPoints 3559;
BA_ "SPN" SG_ 2566754558 AETCDataCollectionStandard 3558;
BA_ "SigType" SG_ 2566754558 AETCDataCollectionStandard 4;
BA_ "SPN" SG_ 2566749950 RightHeadlampLightDistribution 3694;
BA_ "SigType" SG_ 2566749950 RightHeadlampLightDistribution 4;
BA_ "SPN" SG_ 2566749950 LeftHeadlampLightDistribution 3693;
BA_ "SigType" SG_ 2566749950 LeftHeadlampLightDistribution 4;
BA_ "SPN" SG_ 2566749950 RghtHeadlampDynamicBendingLight 3692;
BA_ "SPN" SG_ 2566749950 LeftHeadlampDynamicBendingLight 3691;
BA_ "SPN" SG_ 2566838782 AuxI_O16 716;
BA_ "SigType" SG_ 2566838782 AuxI_O16 4;
BA_ "SPN" SG_ 2566838782 AuxI_O15 715;
BA_ "SigType" SG_ 2566838782 AuxI_O15 4;
BA_ "SPN" SG_ 2566838782 AuxI_O14 714;
BA_ "SigType" SG_ 2566838782 AuxI_O14 4;
BA_ "SPN" SG_ 2566838782 AuxI_O13 713;
BA_ "SigType" SG_ 2566838782 AuxI_O13 4;
BA_ "SPN" SG_ 2566838782 AuxI_O12 712;
BA_ "SigType" SG_ 2566838782 AuxI_O12 4;
BA_ "SPN" SG_ 2566838782 AuxI_O11 711;
BA_ "SigType" SG_ 2566838782 AuxI_O11 4;
BA_ "SPN" SG_ 2566838782 AuxI_O10 710;
BA_ "SigType" SG_ 2566838782 AuxI_O10 4;
BA_ "SPN" SG_ 2566838782 AuxI_O09 709;
BA_ "SigType" SG_ 2566838782 AuxI_O09 4;
BA_ "SPN" SG_ 2566838782 AuxI_O08 708;
BA_ "SigType" SG_ 2566838782 AuxI_O08 4;
BA_ "SPN" SG_ 2566838782 AuxI_O07 707;
BA_ "SigType" SG_ 2566838782 AuxI_O07 4;
BA_ "SPN" SG_ 2566838782 AuxI_O06 706;
BA_ "SigType" SG_ 2566838782 AuxI_O06 4;
BA_ "SPN" SG_ 2566838782 AuxI_O05 705;
BA_ "SigType" SG_ 2566838782 AuxI_O05 4;
BA_ "SPN" SG_ 2566838782 AuxI_O04 704;
BA_ "SigType" SG_ 2566838782 AuxI_O04 4;
BA_ "SPN" SG_ 2566838782 AuxI_O03 703;
BA_ "SigType" SG_ 2566838782 AuxI_O03 4;
BA_ "SPN" SG_ 2566838782 AuxI_O02 702;
BA_ "SigType" SG_ 2566838782 AuxI_O02 4;
BA_ "SPN" SG_ 2566838782 AuxI_O01 701;
BA_ "SigType" SG_ 2566838782 AuxI_O01 4;
BA_ "SPN" SG_ 2566838782 AuxI_OChannel2 1084;
BA_ "SigType" SG_ 2566838782 AuxI_OChannel2 1;
BA_ "SPN" SG_ 2566838782 AuxI_OChannel1 1083;
BA_ "SigType" SG_ 2566838782 AuxI_OChannel1 1;
BA_ "SPN" SG_ 2561146622 AuxI_O45 3868;
BA_ "SigType" SG_ 2561146622 AuxI_O45 4;
BA_ "SPN" SG_ 2561146622 AuxI_O46 3869;
BA_ "SigType" SG_ 2561146622 AuxI_O46 4;
BA_ "SPN" SG_ 2561146622 AuxI_O47 3870;
BA_ "SigType" SG_ 2561146622 AuxI_O47 4;
BA_ "SPN" SG_ 2561146622 AuxI_O48 3871;
BA_ "SigType" SG_ 2561146622 AuxI_O48 4;
BA_ "SPN" SG_ 2561146622 AuxI_O41 3864;
BA_ "SigType" SG_ 2561146622 AuxI_O41 4;
BA_ "SPN" SG_ 2561146622 AuxI_O42 3865;
BA_ "SigType" SG_ 2561146622 AuxI_O42 4;
BA_ "SPN" SG_ 2561146622 AuxI_O43 3866;
BA_ "SigType" SG_ 2561146622 AuxI_O43 4;
BA_ "SPN" SG_ 2561146622 AuxI_O44 3867;
BA_ "SigType" SG_ 2561146622 AuxI_O44 4;
BA_ "SPN" SG_ 2561146622 AuxI_O37 3860;
BA_ "SigType" SG_ 2561146622 AuxI_O37 4;
BA_ "SPN" SG_ 2561146622 AuxI_O38 3861;
BA_ "SigType" SG_ 2561146622 AuxI_O38 4;
BA_ "SPN" SG_ 2561146622 AuxI_O39 3862;
BA_ "SigType" SG_ 2561146622 AuxI_O39 4;
BA_ "SPN" SG_ 2561146622 AuxI_O40 3863;
BA_ "SigType" SG_ 2561146622 AuxI_O40 4;
BA_ "SPN" SG_ 2561146622 AuxI_O33 3856;
BA_ "SigType" SG_ 2561146622 AuxI_O33 4;
BA_ "SPN" SG_ 2561146622 AuxI_O34 3857;
BA_ "SigType" SG_ 2561146622 AuxI_O34 4;
BA_ "SPN" SG_ 2561146622 AuxI_O35 3858;
BA_ "SigType" SG_ 2561146622 AuxI_O35 4;
BA_ "SPN" SG_ 2561146622 AuxI_O36 3859;
BA_ "SigType" SG_ 2561146622 AuxI_O36 4;
BA_ "SPN" SG_ 2561146622 AuxI_O29 3852;
BA_ "SigType" SG_ 2561146622 AuxI_O29 4;
BA_ "SPN" SG_ 2561146622 AuxI_O30 3853;
BA_ "SigType" SG_ 2561146622 AuxI_O30 4;
BA_ "SPN" SG_ 2561146622 AuxI_O31 3854;
BA_ "SigType" SG_ 2561146622 AuxI_O31 4;
BA_ "SPN" SG_ 2561146622 AuxI_O32 3855;
BA_ "SigType" SG_ 2561146622 AuxI_O32 4;
BA_ "SPN" SG_ 2561146622 AuxI_O25 3848;
BA_ "SigType" SG_ 2561146622 AuxI_O25 4;
BA_ "SPN" SG_ 2561146622 AuxI_O26 3849;
BA_ "SigType" SG_ 2561146622 AuxI_O26 4;
BA_ "SPN" SG_ 2561146622 AuxI_O27 3850;
BA_ "SigType" SG_ 2561146622 AuxI_O27 4;
BA_ "SPN" SG_ 2561146622 AuxI_O28 3851;
BA_ "SigType" SG_ 2561146622 AuxI_O28 4;
BA_ "SPN" SG_ 2561146622 AuxI_O21 3844;
BA_ "SigType" SG_ 2561146622 AuxI_O21 4;
BA_ "SPN" SG_ 2561146622 AuxI_O22 3845;
BA_ "SigType" SG_ 2561146622 AuxI_O22 4;
BA_ "SPN" SG_ 2561146622 AuxI_O23 3846;
BA_ "SigType" SG_ 2561146622 AuxI_O23 4;
BA_ "SPN" SG_ 2561146622 AuxI_O24 3847;
BA_ "SigType" SG_ 2561146622 AuxI_O24 4;
BA_ "SPN" SG_ 2561146622 AuxI_O17 3840;
BA_ "SigType" SG_ 2561146622 AuxI_O17 4;
BA_ "SPN" SG_ 2561146622 AuxI_O18 3841;
BA_ "SigType" SG_ 2561146622 AuxI_O18 4;
BA_ "SPN" SG_ 2561146622 AuxI_O19 3842;
BA_ "SigType" SG_ 2561146622 AuxI_O19 4;
BA_ "SPN" SG_ 2561146622 AuxI_O20 3843;
BA_ "SigType" SG_ 2561146622 AuxI_O20 4;
BA_ "SPN" SG_ 2561081086 AuxI_O77 3900;
BA_ "SigType" SG_ 2561081086 AuxI_O77 4;
BA_ "SPN" SG_ 2561081086 AuxI_O78 3901;
BA_ "SigType" SG_ 2561081086 AuxI_O78 4;
BA_ "SPN" SG_ 2561081086 AuxI_O79 3902;
BA_ "SigType" SG_ 2561081086 AuxI_O79 4;
BA_ "SPN" SG_ 2561081086 AuxI_O80 3903;
BA_ "SigType" SG_ 2561081086 AuxI_O80 4;
BA_ "SPN" SG_ 2561081086 AuxI_O73 3896;
BA_ "SigType" SG_ 2561081086 AuxI_O73 4;
BA_ "SPN" SG_ 2561081086 AuxI_O74 3897;
BA_ "SigType" SG_ 2561081086 AuxI_O74 4;
BA_ "SPN" SG_ 2561081086 AuxI_O75 3898;
BA_ "SigType" SG_ 2561081086 AuxI_O75 4;
BA_ "SPN" SG_ 2561081086 AuxI_O76 3899;
BA_ "SigType" SG_ 2561081086 AuxI_O76 4;
BA_ "SPN" SG_ 2561081086 AuxI_O69 3892;
BA_ "SigType" SG_ 2561081086 AuxI_O69 4;
BA_ "SPN" SG_ 2561081086 AuxI_O70 3893;
BA_ "SigType" SG_ 2561081086 AuxI_O70 4;
BA_ "SPN" SG_ 2561081086 AuxI_O71 3894;
BA_ "SigType" SG_ 2561081086 AuxI_O71 4;
BA_ "SPN" SG_ 2561081086 AuxI_O72 3895;
BA_ "SigType" SG_ 2561081086 AuxI_O72 4;
BA_ "SPN" SG_ 2561081086 AuxI_O65 3888;
BA_ "SigType" SG_ 2561081086 AuxI_O65 4;
BA_ "SPN" SG_ 2561081086 AuxI_O66 3889;
BA_ "SigType" SG_ 2561081086 AuxI_O66 4;
BA_ "SPN" SG_ 2561081086 AuxI_O67 3890;
BA_ "SigType" SG_ 2561081086 AuxI_O67 4;
BA_ "SPN" SG_ 2561081086 AuxI_O68 3891;
BA_ "SigType" SG_ 2561081086 AuxI_O68 4;
BA_ "SPN" SG_ 2561081086 AuxI_O61 3884;
BA_ "SigType" SG_ 2561081086 AuxI_O61 4;
BA_ "SPN" SG_ 2561081086 AuxI_O62 3885;
BA_ "SigType" SG_ 2561081086 AuxI_O62 4;
BA_ "SPN" SG_ 2561081086 AuxI_O63 3886;
BA_ "SigType" SG_ 2561081086 AuxI_O63 4;
BA_ "SPN" SG_ 2561081086 AuxI_O64 3887;
BA_ "SigType" SG_ 2561081086 AuxI_O64 4;
BA_ "SPN" SG_ 2561081086 AuxI_O57 3880;
BA_ "SigType" SG_ 2561081086 AuxI_O57 4;
BA_ "SPN" SG_ 2561081086 AuxI_O58 3881;
BA_ "SigType" SG_ 2561081086 AuxI_O58 4;
BA_ "SPN" SG_ 2561081086 AuxI_O59 3882;
BA_ "SigType" SG_ 2561081086 AuxI_O59 4;
BA_ "SPN" SG_ 2561081086 AuxI_O60 3883;
BA_ "SigType" SG_ 2561081086 AuxI_O60 4;
BA_ "SPN" SG_ 2561081086 AuxI_O53 3876;
BA_ "SigType" SG_ 2561081086 AuxI_O53 4;
BA_ "SPN" SG_ 2561081086 AuxI_O54 3877;
BA_ "SigType" SG_ 2561081086 AuxI_O54 4;
BA_ "SPN" SG_ 2561081086 AuxI_O55 3878;
BA_ "SigType" SG_ 2561081086 AuxI_O55 4;
BA_ "SPN" SG_ 2561081086 AuxI_O56 3879;
BA_ "SigType" SG_ 2561081086 AuxI_O56 4;
BA_ "SPN" SG_ 2561081086 AuxI_O49 3872;
BA_ "SigType" SG_ 2561081086 AuxI_O49 4;
BA_ "SPN" SG_ 2561081086 AuxI_O50 3873;
BA_ "SigType" SG_ 2561081086 AuxI_O50 4;
BA_ "SPN" SG_ 2561081086 AuxI_O51 3874;
BA_ "SigType" SG_ 2561081086 AuxI_O51 4;
BA_ "SPN" SG_ 2561081086 AuxI_O52 3875;
BA_ "SigType" SG_ 2561081086 AuxI_O52 4;
BA_ "SPN" SG_ 2561015550 AuxI_O92 3915;
BA_ "SigType" SG_ 2561015550 AuxI_O92 4;
BA_ "SPN" SG_ 2561015550 AuxI_O85 3908;
BA_ "SigType" SG_ 2561015550 AuxI_O85 4;
BA_ "SPN" SG_ 2561015550 AuxI_O86 3909;
BA_ "SigType" SG_ 2561015550 AuxI_O86 4;
BA_ "SPN" SG_ 2561015550 AuxI_O87 3910;
BA_ "SigType" SG_ 2561015550 AuxI_O87 4;
BA_ "SPN" SG_ 2561015550 AuxI_O88 3911;
BA_ "SigType" SG_ 2561015550 AuxI_O88 4;
BA_ "SPN" SG_ 2561015550 AuxI_O81 3904;
BA_ "SigType" SG_ 2561015550 AuxI_O81 4;
BA_ "SPN" SG_ 2561015550 AuxI_O82 3905;
BA_ "SigType" SG_ 2561015550 AuxI_O82 4;
BA_ "SPN" SG_ 2561015550 AuxI_O83 3906;
BA_ "SigType" SG_ 2561015550 AuxI_O83 4;
BA_ "SPN" SG_ 2561015550 AuxI_O84 3907;
BA_ "SigType" SG_ 2561015550 AuxI_O84 4;
BA_ "SPN" SG_ 2561015550 AuxI_O109 3932;
BA_ "SigType" SG_ 2561015550 AuxI_O109 4;
BA_ "SPN" SG_ 2561015550 AuxI_O110 3933;
BA_ "SigType" SG_ 2561015550 AuxI_O110 4;
BA_ "SPN" SG_ 2561015550 AuxI_O111 3934;
BA_ "SigType" SG_ 2561015550 AuxI_O111 4;
BA_ "SPN" SG_ 2561015550 AuxI_O112 3935;
BA_ "SigType" SG_ 2561015550 AuxI_O112 4;
BA_ "SPN" SG_ 2561015550 AuxI_O105 3928;
BA_ "SigType" SG_ 2561015550 AuxI_O105 4;
BA_ "SPN" SG_ 2561015550 AuxI_O106 3929;
BA_ "SigType" SG_ 2561015550 AuxI_O106 4;
BA_ "SPN" SG_ 2561015550 AuxI_O107 3930;
BA_ "SigType" SG_ 2561015550 AuxI_O107 4;
BA_ "SPN" SG_ 2561015550 AuxI_O108 3931;
BA_ "SigType" SG_ 2561015550 AuxI_O108 4;
BA_ "SPN" SG_ 2561015550 AuxI_O101 3924;
BA_ "SigType" SG_ 2561015550 AuxI_O101 4;
BA_ "SPN" SG_ 2561015550 AuxI_O102 3925;
BA_ "SigType" SG_ 2561015550 AuxI_O102 4;
BA_ "SPN" SG_ 2561015550 AuxI_O103 3926;
BA_ "SigType" SG_ 2561015550 AuxI_O103 4;
BA_ "SPN" SG_ 2561015550 AuxI_O104 3927;
BA_ "SigType" SG_ 2561015550 AuxI_O104 4;
BA_ "SPN" SG_ 2561015550 AuxI_O97 3920;
BA_ "SigType" SG_ 2561015550 AuxI_O97 4;
BA_ "SPN" SG_ 2561015550 AuxI_O98 3921;
BA_ "SigType" SG_ 2561015550 AuxI_O98 4;
BA_ "SPN" SG_ 2561015550 AuxI_O99 3922;
BA_ "SigType" SG_ 2561015550 AuxI_O99 4;
BA_ "SPN" SG_ 2561015550 AuxI_O100 3923;
BA_ "SigType" SG_ 2561015550 AuxI_O100 4;
BA_ "SPN" SG_ 2561015550 AuxI_O93 3916;
BA_ "SigType" SG_ 2561015550 AuxI_O93 4;
BA_ "SPN" SG_ 2561015550 AuxI_O94 3917;
BA_ "SigType" SG_ 2561015550 AuxI_O94 4;
BA_ "SPN" SG_ 2561015550 AuxI_O95 3918;
BA_ "SigType" SG_ 2561015550 AuxI_O95 4;
BA_ "SPN" SG_ 2561015550 AuxI_O96 3919;
BA_ "SigType" SG_ 2561015550 AuxI_O96 4;
BA_ "SPN" SG_ 2561015550 AuxI_O89 3912;
BA_ "SigType" SG_ 2561015550 AuxI_O89 4;
BA_ "SPN" SG_ 2561015550 AuxI_O90 3913;
BA_ "SigType" SG_ 2561015550 AuxI_O90 4;
BA_ "SPN" SG_ 2561015550 AuxI_O91 3914;
BA_ "SigType" SG_ 2561015550 AuxI_O91 4;
BA_ "SPN" SG_ 2566746622 TrailerBrakeStrokeAxle5Right 3804;
BA_ "SPN" SG_ 2566746622 TrailerBrakeStrokeAxle5Left 3803;
BA_ "SPN" SG_ 2566746622 TrailerBrakeStrokeAxle4Right 3802;
BA_ "SPN" SG_ 2566746622 TrailerBrakeStrokeAxle4Left 3801;
BA_ "SPN" SG_ 2566746622 TrailerBrakeStrokeAxle3Right 3800;
BA_ "SPN" SG_ 2566746622 TrailerBrakeStrokeAxle3Left 3799;
BA_ "SPN" SG_ 2566746622 TrailerBrakeStrokeAxle2Right 3798;
BA_ "SPN" SG_ 2566746622 TrailerBrakeStrokeAxle2Left 3797;
BA_ "SPN" SG_ 2566746622 TrailerBrakeStrokeAxle1Right 3796;
BA_ "SPN" SG_ 2566746622 TrailerBrakeStrokeAxle1Left 3795;
BA_ "SPN" SG_ 2566746622 TractorBrakeStrokeAxle5Right 3794;
BA_ "SPN" SG_ 2566746622 TractorBrakeStrokeAxle5Left 3793;
BA_ "SPN" SG_ 2566746622 TractorBrakeStrokeAxle4Right 3792;
BA_ "SPN" SG_ 2566746622 TractorBrakeStrokeAxle4Left 3791;
BA_ "SPN" SG_ 2566746622 TractorBrakeStrokeAxle3Right 3790;
BA_ "SPN" SG_ 2566746622 TractorBrakeStrokeAxle3Left 3789;
BA_ "SPN" SG_ 2566746622 TractorBrakeStrokeAxle2Right 3788;
BA_ "SPN" SG_ 2566746622 TractorBrakeStrokeAxle2Left 3787;
BA_ "SPN" SG_ 2566746622 TractorBrakeStrokeAxle1Right 3786;
BA_ "SPN" SG_ 2566746622 TractorBrakeStrokeAxle1Left 3785;
BA_ "SPN" SG_ 2566845950 EngAirIntakeTemp 172;
BA_ "SigType" SG_ 2566845950 EngAirIntakeTemp 1;
BA_ "SPN" SG_ 2566845950 RoadSurfaceTemp 79;
BA_ "SigType" SG_ 2566845950 RoadSurfaceTemp 1;
BA_ "SPN" SG_ 2566845950 AmbientAirTemp 171;
BA_ "SigType" SG_ 2566845950 AmbientAirTemp 1;
BA_ "SPN" SG_ 2566845950 CabInteriorTemp 170;
BA_ "SigType" SG_ 2566845950 CabInteriorTemp 1;
BA_ "SPN" SG_ 2566845950 BarometricPress 108;
BA_ "SigType" SG_ 2566845950 BarometricPress 1;
BA_ "SPN" SG_ 2566840062 EngAirStartPress 82;
BA_ "SigType" SG_ 2566840062 EngAirStartPress 1;
BA_ "SPN" SG_ 2566827774 ServiceBrakeCircuit2AirPress 1088;
BA_ "SigType" SG_ 2566827774 ServiceBrakeCircuit2AirPress 1;
BA_ "SPN" SG_ 2566827774 ServiceBrakeCircuit1AirPress 1087;
BA_ "SigType" SG_ 2566827774 ServiceBrakeCircuit1AirPress 1;
BA_ "SPN" SG_ 2566827774 AirCompressorStatus 1351;
BA_ "SigType" SG_ 2566827774 AirCompressorStatus 4;
BA_ "SPN" SG_ 2566827774 AirSuspensionSupplyPress 1090;
BA_ "SigType" SG_ 2566827774 AirSuspensionSupplyPress 1;
BA_ "SPN" SG_ 2566827774 AuxEquipmentSupplyPress 1089;
BA_ "SigType" SG_ 2566827774 AuxEquipmentSupplyPress 1;
BA_ "SPN" SG_ 2566827774 ParkingAnd_OrTrailerAirPress 1086;
BA_ "SigType" SG_ 2566827774 ParkingAnd_OrTrailerAirPress 1;
BA_ "SPN" SG_ 2566827774 PneumaticSupplyPress 46;
BA_ "SigType" SG_ 2566827774 PneumaticSupplyPress 1;
BA_ "SPN" SG_ 2566846974 SteerAxleLubePress 2614;
BA_ "SigType" SG_ 2566846974 SteerAxleLubePress 1;
BA_ "SPN" SG_ 2566846974 SteerAxleTemp 75;
BA_ "SigType" SG_ 2566846974 SteerAxleTemp 1;
BA_ "SPN" SG_ 2566846974 DriveAxleLubePress 2613;
BA_ "SigType" SG_ 2566846974 DriveAxleLubePress 1;
BA_ "SPN" SG_ 2566846974 DriveAxleTemp 578;
BA_ "SigType" SG_ 2566846974 DriveAxleTemp 1;
BA_ "SPN" SG_ 2566846974 DriveAxleLiftAirPress 579;
BA_ "SigType" SG_ 2566846974 DriveAxleLiftAirPress 1;
BA_ "SPN" SG_ 2566846974 DriveAxleLocation 930;
BA_ "SigType" SG_ 2566846974 DriveAxleLocation 1;
BA_ "SPN" SG_ 2633935614 EngTurboWastegateValvePos 1693;
BA_ "SigType" SG_ 2633935614 EngTurboWastegateValvePos 1;
BA_ "SPN" SG_ 2633935614 EngGsMssFlwSnsrFelingCorrection 1694;
BA_ "SigType" SG_ 2633935614 EngGsMssFlwSnsrFelingCorrection 1;
BA_ "SPN" SG_ 2633935614 EngDsiredAbsIntakeManifoldPress 1692;
BA_ "SigType" SG_ 2633935614 EngDsiredAbsIntakeManifoldPress 1;
BA_ "SPN" SG_ 2633935614 EngGasFuelCorrectionFactor 1116;
BA_ "SigType" SG_ 2633935614 EngGasFuelCorrectionFactor 1;
BA_ "SPN" SG_ 2566803966 ACCUsageDemand 5023;
BA_ "SigType" SG_ 2566803966 ACCUsageDemand 4;
BA_ "SPN" SG_ 2566803966 RqedACCDistanceMode 1799;
BA_ "SPN" SG_ 2432593918 ForwardCollisionWarning 5022;
BA_ "SigType" SG_ 2432593918 ForwardCollisionWarning 4;
BA_ "SPN" SG_ 2432593918 ACCDistanceAlertSignal 1796;
BA_ "SigType" SG_ 2432593918 ACCDistanceAlertSignal 4;
BA_ "SPN" SG_ 2432593918 ACCSystemShutoffWarning 1797;
BA_ "SigType" SG_ 2432593918 ACCSystemShutoffWarning 4;
BA_ "SPN" SG_ 2432593918 ACCTargetDetected 1798;
BA_ "SigType" SG_ 2432593918 ACCTargetDetected 4;
BA_ "SPN" SG_ 2432593918 RoadCurvature 1591;
BA_ "SigType" SG_ 2432593918 RoadCurvature 1;
BA_ "SPN" SG_ 2432593918 AdptveCruiseCtrlSetDistanceMode 1589;
BA_ "SPN" SG_ 2432593918 AdaptiveCruiseCtrlMode 1590;
BA_ "SPN" SG_ 2432593918 AdaptiveCruiseCtrlSetSpeed 1588;
BA_ "SigType" SG_ 2432593918 AdaptiveCruiseCtrlSetSpeed 1;
BA_ "SPN" SG_ 2432593918 DistanceToForwardVehicle 1587;
BA_ "SigType" SG_ 2432593918 DistanceToForwardVehicle 1;
BA_ "SPN" SG_ 2432593918 SpeedOfForwardVehicle 1586;
BA_ "SigType" SG_ 2432593918 SpeedOfForwardVehicle 1;
BA_ "SPN" SG_ 2633935102 ArticulationAngle 1120;
BA_ "SigType" SG_ 2633935102 ArticulationAngle 1;
BA_ "SPN" SG_ 2633927934 RelativeHumidity 354;
BA_ "SigType" SG_ 2633927934 RelativeHumidity 1;
BA_ "SPN" SG_ 2633927934 AuxLevel 3087;
BA_ "SigType" SG_ 2633927934 AuxLevel 1;
BA_ "SPN" SG_ 2633927934 AuxPress2 1388;
BA_ "SigType" SG_ 2633927934 AuxPress2 1;
BA_ "SPN" SG_ 2633927934 AuxPress1 1387;
BA_ "SigType" SG_ 2633927934 AuxPress1 1;
BA_ "SPN" SG_ 2633927934 AuxTemp2 442;
BA_ "SigType" SG_ 2633927934 AuxTemp2 1;
BA_ "SPN" SG_ 2633927934 AuxTemp1 441;
BA_ "SigType" SG_ 2633927934 AuxTemp1 1;
BA_ "SPN" SG_ 2566847998 EngBlowerBypassValvePos 72;
BA_ "SigType" SG_ 2566847998 EngBlowerBypassValvePos 1;
BA_ "SPN" SG_ 2566847998 EngGasSupplyPress 159;
BA_ "SigType" SG_ 2566847998 EngGasSupplyPress 1;
BA_ "SPN" SG_ 2566803198 Status2OfDoors 3411;
BA_ "SigType" SG_ 2566803198 Status2OfDoors 4;
BA_ "SPN" SG_ 2566803198 Ramp_WheelChairLiftPos 1820;
BA_ "SigType" SG_ 2566803198 Ramp_WheelChairLiftPos 4;
BA_ "SPN" SG_ 2566803198 PosOfDoors 1821;
BA_ "SigType" SG_ 2566803198 PosOfDoors 4;
BA_ "SPN" SG_ 2565870334 FifthWheelRollWarningIndicator 3317;
BA_ "SigType" SG_ 2565870334 FifthWheelRollWarningIndicator 4;
BA_ "SPN" SG_ 2565870334 FifthWheelRollMoment 3310;
BA_ "SigType" SG_ 2565870334 FifthWheelRollMoment 1;
BA_ "SPN" SG_ 2565870334 FifthWheelDrawbarForce 3309;
BA_ "SigType" SG_ 2565870334 FifthWheelDrawbarForce 1;
BA_ "SPN" SG_ 2565870334 FifthWheelVerticalForce 3308;
BA_ "SigType" SG_ 2565870334 FifthWheelVerticalForce 1;
BA_ "SPN" SG_ 2566762238 FifthWheelSliderLockIndicator 3316;
BA_ "SigType" SG_ 2566762238 FifthWheelSliderLockIndicator 4;
BA_ "SPN" SG_ 2566762238 FifthWheelSliderPos 3311;
BA_ "SigType" SG_ 2566762238 FifthWheelSliderPos 1;
BA_ "SPN" SG_ 2566762238 FfthWhlLckCoupleStatusIndicator 3313;
BA_ "SigType" SG_ 2566762238 FfthWhlLckCoupleStatusIndicator 4;
BA_ "SPN" SG_ 2566762238 FfthWhlLckRadyToCoupleIndicator 3312;
BA_ "SigType" SG_ 2566762238 FfthWhlLckRadyToCoupleIndicator 4;
BA_ "SPN" SG_ 2566762238 FifthWheelErrorStatus 3307;
BA_ "SigType" SG_ 2566762238 FifthWheelErrorStatus 4;
BA_ "SPN" SG_ 2364543998 RollAndPitchMeasurementLatency 3327;
BA_ "SigType" SG_ 2364543998 RollAndPitchMeasurementLatency 1;
BA_ "SPN" SG_ 2364543998 PitchAndRollCompensated 3326;
BA_ "SigType" SG_ 2364543998 PitchAndRollCompensated 4;
BA_ "SPN" SG_ 2364543998 PitchRateFigureOfMerit 3325;
BA_ "SigType" SG_ 2364543998 PitchRateFigureOfMerit 4;
BA_ "SPN" SG_ 2364543998 RollAngleFigureOfMerit 3324;
BA_ "SigType" SG_ 2364543998 RollAngleFigureOfMerit 4;
BA_ "SPN" SG_ 2364543998 PitchAngleFigureOfMerit 3323;
BA_ "SigType" SG_ 2364543998 PitchAngleFigureOfMerit 4;
BA_ "SPN" SG_ 2364543998 PitchRate 3322;
BA_ "SigType" SG_ 2364543998 PitchRate 1;
BA_ "SPN" SG_ 2364543998 RollAngle 3319;
BA_ "SigType" SG_ 2364543998 RollAngle 1;
BA_ "SPN" SG_ 2364543998 PitchAngle 3318;
BA_ "SigType" SG_ 2364543998 PitchAngle 1;
BA_ "SPN" SG_ 2566846718 TransOilLevelMeasurementStatus 3026;
BA_ "SigType" SG_ 2566846718 TransOilLevelMeasurementStatus 4;
BA_ "SPN" SG_ 2566846718 TransOilLevelCountdownTimer 3028;
BA_ "SigType" SG_ 2566846718 TransOilLevelCountdownTimer 4;
BA_ "SPN" SG_ 2566846718 TransOilLevelHigh_Low 3027;
BA_ "SigType" SG_ 2566846718 TransOilLevelHigh_Low 1;
BA_ "SPN" SG_ 2566846718 TransOilTemp 177;
BA_ "SigType" SG_ 2566846718 TransOilTemp 1;
BA_ "SPN" SG_ 2566846718 TransOilPress 127;
BA_ "SigType" SG_ 2566846718 TransOilPress 1;
BA_ "SPN" SG_ 2566846718 TransFilterDiffPress 126;
BA_ "SigType" SG_ 2566846718 TransFilterDiffPress 1;
BA_ "SPN" SG_ 2566846718 TransOilLevel 124;
BA_ "SigType" SG_ 2566846718 TransOilLevel 1;
BA_ "SPN" SG_ 2566846718 ClutchPress 123;
BA_ "SigType" SG_ 2566846718 ClutchPress 1;
BA_ "SPN" SG_ 2566846462 ChargingSystemPotential 167;
BA_ "SigType" SG_ 2566846462 ChargingSystemPotential 1;
BA_ "SPN" SG_ 2566846462 AltCurrent 115;
BA_ "SigType" SG_ 2566846462 AltCurrent 1;
BA_ "SPN" SG_ 2566846462 NetBatteryCurrent 114;
BA_ "SigType" SG_ 2566846462 NetBatteryCurrent 1;
BA_ "SPN" SG_ 2566846462 KeyswitchBatteryPotential 158;
BA_ "SigType" SG_ 2566846462 KeyswitchBatteryPotential 1;
BA_ "SPN" SG_ 2566846462 BatteryPotential_PowerInput1 168;
BA_ "SigType" SG_ 2566846462 BatteryPotential_PowerInput1 1;
BA_ "SPN" SG_ 2566760702 WrlessCommunicationNetworkType2 3446;
BA_ "SigType" SG_ 2566760702 WrlessCommunicationNetworkType2 1;
BA_ "SPN" SG_ 2566760702 NetworkSignalStrength2 3445;
BA_ "SigType" SG_ 2566760702 NetworkSignalStrength2 1;
BA_ "SPN" SG_ 2566760702 NetworkAntennaStatus2 3444;
BA_ "SigType" SG_ 2566760702 NetworkAntennaStatus2 1;
BA_ "SPN" SG_ 2566760702 NetworkServiceStatus2 3443;
BA_ "SigType" SG_ 2566760702 NetworkServiceStatus2 1;
BA_ "SPN" SG_ 2566760702 NetworkTransceiverStatus2 3442;
BA_ "SigType" SG_ 2566760702 NetworkTransceiverStatus2 1;
BA_ "SPN" SG_ 2566760958 WrlessCommunicationNetworkType1 3372;
BA_ "SigType" SG_ 2566760958 WrlessCommunicationNetworkType1 1;
BA_ "SPN" SG_ 2566760958 NetworkSignalStrength1 3371;
BA_ "SigType" SG_ 2566760958 NetworkSignalStrength1 1;
BA_ "SPN" SG_ 2566760958 NetworkAntennaStatus1 3370;
BA_ "SigType" SG_ 2566760958 NetworkAntennaStatus1 1;
BA_ "SPN" SG_ 2566760958 NetworkServiceStatus1 3369;
BA_ "SigType" SG_ 2566760958 NetworkServiceStatus1 1;
BA_ "SPN" SG_ 2566760958 NetworkTransceiverStatus1 3368;
BA_ "SigType" SG_ 2566760958 NetworkTransceiverStatus1 1;
VAL_ 2365479678 SpeedDependantLevelCtrlStatus 3 "DonTCare_TakeNoAction" 2 "Reserved" 1 "Active" 0 "Inactive" ;
VAL_ 2365479678 MemoryLevel 15 "NotAvailable" 14 "ErrorIndicator" 13 "MemoryLevel5Stored" 12 "MemoryLevel4Stored" 11 "MemoryLevel3Stored" 10 "MemoryLevel2Stored" 9 "MemoryLevel1Stored" 8 "Reserved" 5 "MemoryLevel5Selected" 4 "MemoryLevel4Selected" 3 "MemoryLevel3Selected" 2 "MemoryLevel2Selected" 1 "MemoryLevel1Selected" 0 "NoMemoryLevel" ;
VAL_ 2365479678 AllwLvelCtrlDuringBrakingStatus 3 "DonTCare_TakeNoAction" 2 "Reserved" 1 "Activate" 0 "Deactivate" ;
VAL_ 2365479678 SspensionCtrlRefusalInformation 15 "NotAvailable" 14 "Error" 8 "1101NotDefined" 7 "RqedLevelNotAvailable" 6 "GnrlRjctINSpcifiedReasonApplies" 5 "BelowSpeedLimit" 4 "AboveSpeedLimit" 3 "BogieDiffNotLocked" 2 "WouldExceedAxleLoadLimit" 1 "AxleLoadLimitReached" 0 "ActualRqNotRefused" ;
VAL_ 2365479678 SuspensionRemoteCtrl2 3 "NotAvailable" 2 "Error" 1 "Active" 0 "NotActive" ;
VAL_ 2365479678 SuspensionRemoteCtrl1 3 "NotAvailable" 2 "Error" 1 "Active" 0 "NotActive" ;
VAL_ 2365479678 RearAxleInBumperRange 3 "NotAvailable" 2 "Error" 1 "ActualLevelWithinBumperRange" 0 "ActualLevelOutOfBumperRange" ;
VAL_ 2365479678 FrontAxleInBumperRange 3 "NotAvailable" 2 "Error" 1 "ActualLevelWithinBumperRange" 0 "ActualLevelOutOfBumperRange" ;
VAL_ 2365479678 DoorRelease 3 "NotAvailable" 2 "Error" 1 "DoorsMayBeOpened" 0 "DoorsMayNotBeOpened" ;
VAL_ 2365479678 VehicleMotionInhibit 3 "NotAvailable" 2 "Error" 1 "VehicleMotionIsInhibited" 0 "VehicleMayBeMoved" ;
VAL_ 2365479678 SecurityDevice 3 "NotAvailable" 2 "Error" 1 "Active" 0 "NotActive" ;
VAL_ 2365479678 LevelCtrlMode 11 "1101NotDefined" 10 "AtmtcArSuspensionCtrlProhibited" 15 "NotAvailable" 14 "Error" 9 "AirSuspensionCtrlProhibited" 8 "ExhstngBllwFnctnIBllwsArExhstdT" 7 "TractionHelpLoadReduce" 6 "OptmmTrctn2IPrssAtThDrvnAxlIsCt" 5 "OptmmTrctn1IPrssAtThDrvnAxlIsCt" 4 "PrssRt2IRtBtwnThPrssrsAtThDrvnA" 3 "PrssRt1IRtBtwnThPrssrsAtThDrvnA" 2 "LdFxngIDrvnAxlnIsLddTAVlDfndByT" 1 "TrctnHlpIDrvnAxlIsLddTAMxVlGvnB" 0 "NrmlOprtnISystmPrfrmsAPrCtrlOfT" ;
VAL_ 2365479678 KneelingInformation 15 "NotAvailable" 14 "Error" 5 "1101NotDefined" 4 "KneelingAborted" 3 "LiftingActive" 2 "KneelingLevelReached" 0 "NotActive" ;
VAL_ 2365479678 LiftingCtrlModeRearAxle 3 "NotAvailable" 2 "Error" 1 "LiftingActive" 0 "LiftingNotActive" ;
VAL_ 2365479678 LiftingCtrlModeFrontAxle 3 "NotAvailable" 2 "Error" 1 "LiftingActive" 0 "LiftingNotActive" ;
VAL_ 2365479678 LoweringCtrlModeRearAxle 3 "NotAvailable" 2 "Error" 1 "LoweringActive" 0 "LoweringNotActive" ;
VAL_ 2365479678 LoweringCtrlModeFrontAxle 3 "NotAvailable" 2 "Error" 1 "LoweringActive" 0 "LoweringNotActive" ;
VAL_ 2365479678 AboveNominalLevelRearAxle 3 "NotAvailable" 2 "Error" 1 "Above" 0 "NotAbove" ;
VAL_ 2365479678 AboveNominalLevelFrontAxle 3 "NotAvailable" 2 "Error" 1 "Above" 0 "NotAbove" ;
VAL_ 2365479678 BelowNominalLevelRearAxle 3 "NotAvailable" 2 "Error" 1 "Below" 0 "NotBelow" ;
VAL_ 2365479678 BelowNominalLevelFrontAxle 3 "NotAvailable" 2 "Error" 1 "Below" 0 "NotBelow" ;
VAL_ 2365479678 NominalLevelRearAxle 9 "Raising" 11 "1101NotDefined" 10 "Lowering" 15 "NotAvailable" 14 "Error" 8 "NotDefined" 7 "LowerLevel" 6 "UpperLevel" 5 "CustomerLevel" 4 "PresetLevel" 3 "NormalLevel3" 2 "NormalLevel2" 1 "NormalLevel1" 0 "LevelNotSpecified" ;
VAL_ 2365479678 NominalLevelFrontAxle 9 "Raising" 11 "1101NotDefined" 10 "Lowering" 15 "NotAvailable" 14 "Error" 8 "NotDefined" 7 "LowerLevel" 6 "UpperLevel" 5 "CustomerLevel" 4 "PresetLevel" 3 "NormalLevel3" 2 "NormalLevel2" 1 "NormalLevel1" 0 "LevelNotSpecified" ;
VAL_ 2365479678 LiftAxle2Pos 3 "NotAvailable" 2 "Error" 1 "LiftAxlePosUp_TagAxleUnladen" 0 "LiftAxlePosDown_TagAxleLaden" ;
VAL_ 2365479678 LiftAxle1Pos 3 "NotAvailable" 2 "Error" 1 "LiftAxlePosUp_TagAxleUnladen" 0 "LiftAxlePosDown_TagAxleLaden" ;
VAL_ 2566837758 Alt4Status 3 "notAvailable" 2 "error" 1 "Alt4Charging" 0 "Alt4NotCharging" ;
VAL_ 2566837758 Alt3Status 3 "notAvailable" 2 "error" 1 "Alt3Charging" 0 "Alt3NotCharging" ;
VAL_ 2566837758 Alt2Status 3 "notAvailable" 2 "error" 1 "Alt2Charging" 0 "Alt2NotCharging" ;
VAL_ 2566837758 Alt1Status 3 "notAvailable" 2 "error" 1 "Alt1Charging" 0 "Alt1NotCharging" ;
VAL_ 2566836478 TestIdentifier 250 "Last Measured Scaled Results" 249 "Command Standard Test" 247 "All scaled test results" ;
VAL_ 2565078782 TestIdentifier 250 "Last Measured Scaled Results" 249 "Command Standard Test" 247 "All scaled test results" ;
VAL_ 2565078782 FailureModeIdentifier1 31 "Not available" 19 "Received network data in error" 18 "Below normal (moderately severe)" 17 "Below normal (least severe)" 16 "Above normal (moderately severe)" 15 "Above normal (least severe)" 14 "Special intstructions" 13 "Out of calibration" 12 "Bad intelligent device" 11 "Root cause not known" 10 "Abnormal rate of change" 9 "Abnormal update rate" 8 "Abnormal frequency" 7 "Mechanical system not responding" 6 "Current above normal" 5 "Current below normal" 4 "Voltage below normal" 3 "Voltage above normal" 2 "Data erratic" 1 "Below normal (most severe)" 0 "Above normal (most severe)" ;
VAL_ 2566835966 OBDCompliance 25 "OBD-M (SI-SD/I)" 23 "HD EOBD" 22 "OBD II (California, ARB 07/08)" 21 "WWH OBD" 20 "HD OBD" 19 "HD OBD P" 18 "EMD+" 17 "EMD" 16 "Heavy Duty Vehicles (EURO EEC) C" 15 "Heavy Duty Vehicles (EURO V) B2" 14 "Heavy Duty Vehicles (EURO IV) B1" 13 "JOBD, EOBD and OBD II" 12 "JOBD and EOBD" 11 "JOBD and OBD II" 10 "JOBD" 9 "EOBD, OBD and OBD II" 8 "EOBD and OBD" 7 "EOBD and OBD II" 6 "EOBD" 5 "Not intended to meet OBD II req." 4 "OBD I" 3 "OBD and OBD II" 2 "OBD (Federal, EPA)" 1 "OBD II (California, ARB)" 0 "Reserver for assignment by SAE" ;
VAL_ 2566835966 SecondAirSystemMonStatus 1 "TestNotComplete" 0 "TestComplete" ;
VAL_ 2566835966 EvaporativeSystemMonStatus 1 "TestNotComplete" 0 "TestComplete" ;
VAL_ 2566835966 ACSystemRefrigerantMonStatus 1 "TestNotComplete" 0 "TestComplete" ;
VAL_ 2566835966 OxygenSensorHeaterMonStatus 1 "TestNotComplete" 0 "TestComplete" ;
VAL_ 2566835966 OxygenSensorMonStatus 1 "test not complete" 0 "test complete" ;
VAL_ 2566835966 EGRSystemMonitoringStatus 1 "TestNotComplete" 0 "TestComplete" ;
VAL_ 2566835966 CatalystMonStatus 0 "TestComplete" 1 "TestNotComplete" ;
VAL_ 2566835966 ColdStartAidSystemMonStatus 1 "TestNotComplete" 0 "TestComplete" ;
VAL_ 2566835966 HeatedCatalystMonStatus 1 "TestNotComplete" 0 "TestComplete" ;
VAL_ 2566835966 CatalystMonSupp 1 "TestSupported" 0 "TestNotSupported" ;
VAL_ 2566835966 ColdStartAidSystemMonSupp 1 "TestSupported" 0 "TestNotSupported" ;
VAL_ 2566835966 HeatedCatalystMonSupp 1 "TestSupported" 0 "TestNotSupported" ;
VAL_ 2566835966 EvaporativeSystemMonSupp 1 "TestSupported" 0 "TestNotSupported" ;
VAL_ 2566835966 SecondAirSystemMonSupp 1 "TestSupported" 0 "TestNotSupported" ;
VAL_ 2566835966 ACSystemRefrigerantMonSupp 1 "TestSupported" 0 "TestNotSupported" ;
VAL_ 2566835966 OxygenSensorMonSupp 1 "TestSupported" 0 "TestNotSupported" ;
VAL_ 2566835966 OxygenSensorHeaterMonSupp 1 "TestSupported" 0 "TestNotSupported" ;
VAL_ 2566835966 EGRSystemMonitoringSupp 1 "TestSupported" 0 "TestNotSupported" ;
VAL_ 2566835966 MisfireMonitoringStatus 1 "test not complete" 0 "test complete" ;
VAL_ 2566835966 ComprehensiveCompMonStatus 1 "test not complete" 0 "test complete" ;
VAL_ 2566835966 FuelSystemMonitoringStatus 1 "test not complete" 0 "test complete" ;
VAL_ 2566835966 ComprehensiveComponentMonSupp 3 "Not available" 2 "Reserved" 1 "test supported" 0 "test not supported" ;
VAL_ 2566835966 FuelSystemMonitoringSupport 1 "test supported" 0 "test not supported" ;
VAL_ 2562981630 FailureModeIdentifier1 31 "Not available" 19 "Received network data in error" 18 "Below normal (moderately severe)" 17 "Below normal (least severe)" 16 "Above normal (moderately severe)" 15 "Above normal (least severe)" 14 "Special intstructions" 13 "Out of calibration" 12 "Bad intelligent device" 11 "Root cause not known" 10 "Abnormal rate of change" 9 "Abnormal update rate" 8 "Abnormal frequency" 7 "Mechanical system not responding" 6 "Current above normal" 5 "Current below normal" 4 "Voltage below normal" 3 "Voltage above normal" 2 "Data erratic" 1 "Below normal (most severe)" 0 "Above normal (most severe)" ;
VAL_ 2564357886 Seed 255 "NoFurtherKeyRequiredOfTool" 1 "UseLongSeedOrKeyFromDataSecMsg" 0 "SeedCompleted_BeginSendingKey" ;
VAL_ 2564357886 EDCP_Extension 9 "DataInErrIndAndDataInSeedIsTime" 6 "DataInErrorIndicator" 3 "ConcatenateDataAsLowerEDCParam" 2 "ConcatenateDataAsHigherEDCParam" 0 "Completed" 255 "NoErrIndicator/EDCParamAvailable" ;
VAL_ 2564357886 ErrorIndicator 16777215 "NoErrorIndicatorAvailable" 65540 "TransprtNotComplWithinTimeAllowd" 65539 "TransportNotInitWithinTimeAllowd" 65538 "NoResponseInTheTimeAllowed" 65537 "ModuleExceedingNumberOfRetries" 65536 "AbortFromExtToNormalSoftwareProc" 4103 "VehicleNotInParkOrNotStationary" 4102 "EngineRunning" 4101 "NotInEngineeringOrDevelopmentMode" 4100 "NotInDiagnosticMode" 4099 "InvalidKey" 4098 "InvalidUserLevel" 4097 "InvalidPassword" 4096 "SecurityErrorGeneral" 266 "NameDoesNotConformToExpectdValue" 265 "DataDoesNotConformToValueRanges" 264 "AddrForBootLoadExeInvalidBoundary" 263 "AddrForBootLoadExeOutsideExeMem" 262 "OpReqExeTransfAndEraseOfProgMem" 261 "OpRequiresPriorEraseOfProgramMem" 260 "OpRequiresPriorEraseOfDataMem" 259 "ReqMemoryExceededAvailableMemory" 258 "LengthNotValidForMemStructAndOp" 257 "AddressNotOnValidBoundary" 256 "AddressingOrDataGeneralError" 36 "InternalFailurePreventingReq" 35 "PROMDidNotVerifyOnWrite" 34 "FLASHDidNotVerifyOnWrite" 33 "RAMDidNotVerifyOnWrite" 32 "EDCParaNotCorrectForDataStream" 31 "ProcessUnspecReqFromThisAddress" 23 "ProcessingEDCPGenerationReq" 22 "ProcessingBootLoadReq" 19 "ProcessingStatusReq" 18 "ProcessingWriteReq" 17 "ProcessingReadReq" 16 "ProcessingEraseReq" 2 "ProcessingForSomeoneElse" 1 "ErrorNotIdentified" 0 "NoError" ;
VAL_ 2564357886 Status 7 "Reserved2" 6 "Reserved1" 5 "OperationFailed" 4 "OperationCompleted" 3 "Reserved0" 2 "Reserved" 1 "Busy" 0 "Proceed" ;
VAL_ 2564423422 KeyOrUserLevel 65535 "NoKeyAvailable" 0 "UseLongSeedOrKey" ;
VAL_ 2564423422 PointerExtension 0 "SPN_SPACE" ;
VAL_ 2564423422 Command 7 "EDCP_Generation" 6 "BootLoad" 5 "OperationFailed" 4 "OperationCompleted" 3 "StatusRequest" 2 "Write" 1 "Read" 0 "Erase" ;
VAL_ 2564423422 PointerType 1 "DirectedSpatialAddressing" 0 "DirectMemoryAddressing" ;
VAL_ 2564816638 HoldSignal 15 "Not available" 1 "Devices whose broadcast state ha" 0 "All devices" ;
VAL_ 2564816638 J1939Network3 3 "Don't care" 2 "Reserved" 1 "Start broadcast" 0 "Stop broadcast" ;
VAL_ 2564816638 J1939Network2 3 "Don't care" 2 "Reserved" 1 "Start broadcast" 0 "Stop broadcast" ;
VAL_ 2564816638 ISO9141 3 "Don't care" 2 "Reserved" 1 "Start broadcast" 0 "Stop broadcast" ;
VAL_ 2564816638 SAE_J1850 3 "Don't care" 2 "Reserved" 1 "Start broadcast" 0 "Stop broadcast" ;
VAL_ 2564816638 ManufacturerSpecificPort 3 "Don't care" 2 "Reserved" 1 "Start broadcast" 0 "Stop broadcast" ;
VAL_ 2564816638 CurrentDataLink 3 "Don't care" 2 "Reserved" 1 "Start broadcast" 0 "Stop broadcast" ;
VAL_ 2564816638 SAE_J1587 3 "Don't care" 2 "Reserved" 1 "Start broadcast" 0 "Stop broadcast" ;
VAL_ 2564816638 SAE_J1922 3 "Don't care" 2 "Reserved" 1 "Start broadcast" 0 "Stop broadcast" ;
VAL_ 2564816638 J1939Network1 3 "Don't care" 2 "Reserved" 1 "Start broadcast" 0 "Stop broadcast" ;
VAL_ 2564816638 SuspendSignal 15 "NotAvailable" 14 "ResumingNormalBroadcastPattern" 3 "TemporarySuspensionOfSomeMessages" 2 "TemporarySuspensionOfAllBroadcasts" 1 "IndefiniteSuspensionOfSomeMessages" 0 "IndefiniteSuspensionOfAllBroadcasts" ;
VAL_ 2566784254 GnrtorOverallPowerFactorLagging 3 "NotAvailable_NotInstalled" 2 "Error" 1 "Lagging" 0 "Leading" ;
VAL_ 2566781950 GnratorPhaseCPowerFactorLagging 3 "NotAvailable_NotInstalled" 2 "Error" 1 "Lagging" 0 "Leading" ;
VAL_ 2566782718 GnratorPhaseBPowerFactorLagging 3 "NotAvailable_NotInstalled" 2 "Error" 1 "Lagging" 0 "Leading" ;
VAL_ 2566783486 GnratorPhaseAPowerFactorLagging 3 "NotAvailable_NotInstalled" 2 "Error" 1 "Lagging" 0 "Leading" ;
VAL_ 2566776830 Bus1_UtilityInSync 3 "NotAvailable" 2 "Error" 1 "Sycnchronized" 0 "NotSynchronized" ;
VAL_ 2566776830 Bus1_UtilityVoltageMatch 3 "NotAvailable" 2 "Error" 1 "VoltagesMatch" 0 "VolatagesDoNotMatch" ;
VAL_ 2566776830 Bus1_UtilityFrequencyMatch 3 "NotAvailable" 2 "Error" 1 "FrequenciesMatch" 0 "FrequenciesDoNotMatch" ;
VAL_ 2566776830 Bus1_UtilityPhaseMatch 3 "NotAvailable" 2 "Error" 1 "PhasesMatch" 0 "PhasesDoNotMatch" ;
VAL_ 2566776830 Bus1_UtilityDeadBus 3 "NotAvailable" 2 "Error" 1 "BusIsDead" 0 "BusIsNotDead" ;
VAL_ 2566777086 Bus1_GeneratorInSync 3 "NotAvailable" 2 "Error" 1 "Sycnchronized" 0 "NotSynchronized" ;
VAL_ 2566777086 Bus1_GeneratorVoltageMatch 3 "NotAvailable" 2 "Error" 1 "VoltagesMatch" 0 "VolatagesDoNotMatch" ;
VAL_ 2566777086 Bus1_GeneratorFrequencyMatch 3 "NotAvailable" 2 "Error" 1 "FrequenciesMatch" 0 "FrequenciesDoNotMatch" ;
VAL_ 2566777086 Bus1_GeneratorPhaseMatch 3 "NotAvailable" 2 "Error" 1 "PhasesMatch" 0 "PhasesDoNotMatch" ;
VAL_ 2566777086 Bus1_GeneratorDeadBus 3 "NotAvailable" 2 "Error" 1 "BusIsDead" 0 "BusIsNotDead" ;
VAL_ 2632777470 PGNumber 255 "NotAvailable" ;
VAL_ 2632777470 ControlByte 24 "EAbort" 23 "EEoMACK" 22 "EDPO" 21 "ECTS" 20 "ERTS" 255 "Abort" 32 "BAM" 19 "EoMA" 17 "CTS" 16 "RTS" ;
VAL_ 2563374846 UseTransferMode 3 "NA" 2 "Undefined" 1 "Yes" 0 "No" ;
VAL_ 2499635966 AxleGroupLocation 3 "TrailerFAxleGroup" 2 "TrailerEAxleGroup" 1 "SteerAxleGroup" 0 "Reserved" ;
VAL_ 2633853438 AxleGroupLocation 3 "TrailerFAxleGroup" 2 "TrailerEAxleGroup" 1 "SteerAxleGroup" 0 "Reserved" ;
VAL_ 2432520702 AftrcoolerCoolantThermostatMode 3 "DontCare_Reserved" 2 "Reserved" 1 "PosCtrlMode" 0 "TempCtrlMode" ;
VAL_ 2566745086 AddtnlTrlrAxlGrpWeightAvailable 3 "NotAvailable_NotApplicable" 2 "Reserved" 1 "AddtonalTrailerAxleGroupPresent" 0 "AddtnlTrilerAxleGroupNotPresent" ;
VAL_ 2566745086 TrilerHAxleGroupWeightAvailable 3 "NotAvailable_NotApplicable" 2 "Reserved" 1 "TrailerHAxleGroupPresent" 0 "TrailerHAxleGroupNotPresent" ;
VAL_ 2566745086 TrilerGAxleGroupWeightAvailable 3 "NotAvailable_NotApplicable" 2 "Reserved" 1 "TrailerGAxleGroupPresent" 0 "TrailerGAxleGroupNotPresent" ;
VAL_ 2566745086 TrilerFAxleGroupWeightAvailable 3 "NotAvailable_NotApplicable" 2 "Reserved" 1 "TrailerFAxleGroupPresent" 0 "TrailerFAxleGroupNotPresent" ;
VAL_ 2566745086 TrilerEAxleGroupWeightAvailable 3 "NotAvailable_NotApplicable" 2 "Reserved" 1 "TrailerEAxleGroupPresent" 0 "TrailerEAxleGroupNotPresent" ;
VAL_ 2566745086 TrilerDAxleGroupWeightAvailable 3 "NotAvailable_NotApplicable" 2 "Reserved" 1 "TrailerDAxleGroupPresent" 0 "TrailerDAxleGroupNotPresent" ;
VAL_ 2566745086 TrilerCAxleGroupWeightAvailable 3 "NotAvailable_NotApplicable" 2 "Reserved" 1 "TrailerCAxleGroupPresent" 0 "TrailerCAxleGroupNotPresent" ;
VAL_ 2566745086 TrilerBAxleGroupWeightAvailable 3 "NotAvailable_NotApplicable" 2 "Reserved" 1 "TrailerBAxleGroupPresent" 0 "TrailerBAxleGroupNotPresent" ;
VAL_ 2566745086 TrilerAAxleGroupWeightAvailable 3 "NotAvailable_NotApplicable" 2 "Reserved" 1 "TrailerAAxleGroupPresent" 0 "TrailerAAxleGroupNotPresent" ;
VAL_ 2566745086 AddtnlTrctrAxlGrpWightAvailable 3 "NotAvailable_NotApplicable" 2 "Reserved" 1 "AddtonalTractorAxleGroupPresent" 0 "AddtnlTrctorAxleGroupNotPresent" ;
VAL_ 2566745086 TagAxleGroupWeightAvailable 3 "NotAvailable_NotApplicable" 2 "Reserved" 1 "TagAxleGroupPresent" 0 "TagAxleGroupNotPresent" ;
VAL_ 2566745086 DriveAxleGroupWeightAvailable 3 "NotAvailable_NotApplicable" 2 "Reserved" 1 "DriveAxleGroupPresent" 0 "DriveAxleGroupNotPresent" ;
VAL_ 2566745086 LiftAxleGroupWeightAvailable 3 "NotAvailable_NotApplicable" 2 "Reserved" 1 "LiftAxleGroupPresent" 0 "LiftAxleGroupNotPresent" ;
VAL_ 2566745086 SteerAxleGroupWeightAvailable 3 "NotAvailable_NotApplicable" 2 "Reserved" 1 "SteerAxleGroupPresent" 0 "SteerAxleGroupNotPresent" ;
VAL_ 2566744062 ZeroNetVehicleWeightChange 3 "NotAvailable_NotApplicable" 2 "Reserved" 1 "ZeroNetVehicleWeightChange" 0 "NChangeToNetVehicleWeightChange" ;
VAL_ 2566754558 AETCDataCollectionStandard 15 "NotAvailable" 1 "1101NotDefined" 0 "SAEJ1995" ;
VAL_ 2566749950 RightHeadlampLightDistribution 15 "NotAvailable" 8 "1110Reserved" 7 "DffrntLghtDstrbtnsNtAvlblNAFSDs" 6 "LghtDstrbtnFlrMdlIsDmgdCrrntPsM" 5 "LghtDstrbtnFlSfPsMdlIsDmgdCrrnt" 4 "LghtDstrbtnAdvrsWthrAdvrsWthrLg" 3 "LghtDstrbtnHghBmHghBmDstrbtnOfT" 2 "LghtDstrbtnMtrwyTskOfMtrwyLghtI" 1 "LghtDstrbtnCntryCntryLghtIsMstl" 0 "LghtDstrbtnTwnBscLghtDstrbtnFrT" ;
VAL_ 2566749950 LeftHeadlampLightDistribution 15 "NotAvailable" 8 "1110Reserved" 7 "DffrntLghtDstrbtnsNtAvlblNAFSDs" 6 "LghtDstrbtnFlrMdlIsDmgdCrrntPsM" 5 "LghtDstrbtnFlSfPsMdlIsDmgdCrrnt" 4 "LghtDstrbtnAdvrsWthrAdvrsWthrLg" 3 "LghtDstrbtnHghBmHghBmDstrbtnOfT" 2 "LghtDstrbtnMtrwyTskOfMtrwyLghtI" 1 "LghtDstrbtnCntryCntryLghtIsMstl" 0 "LghtDstrbtnTwnBscLghtDstrbtnFrT" ;
VAL_ 2566749950 RghtHeadlampDynamicBendingLight 7 "NotAvailable" 4 "110Reserved" 3 "DynmcBndngLghtFlrBndngLghtDsNtW" 2 "DynmcBndngLghtFlSfPsBndngLghtIs" 1 "DynmcBndngLghtIsWrkngPrprlyNrml" 0 "DynmcBndngLghtDctvtdThrIsNPrblm" ;
VAL_ 2566749950 LeftHeadlampDynamicBendingLight 7 "NotAvailable" 4 "110Reserved" 3 "DynmcBndngLghtFlrBndngLghtDsNtW" 2 "DynmcBndngLghtFlSfPsBndngLghtIs" 1 "DynmcBndngLghtIsWrkngPrprlyNrml" 0 "DynmcBndngLghtDctvtdThrIsNPrblm" ;
VAL_ 2566838782 AuxI_O16 3 "NotAvailable" 2 "Error" 1 "AuxChannelOn" 0 "AuxChannelOff" ;
VAL_ 2566838782 AuxI_O15 3 "NotAvailable" 2 "Error" 1 "AuxChannelOn" 0 "AuxChannelOff" ;
VAL_ 2566838782 AuxI_O14 3 "NotAvailable" 2 "Error" 1 "AuxChannelOn" 0 "AuxChannelOff" ;
VAL_ 2566838782 AuxI_O13 3 "NotAvailable" 2 "Error" 1 "AuxChannelOn" 0 "AuxChannelOff" ;
VAL_ 2566838782 AuxI_O12 3 "NotAvailable" 2 "Error" 1 "AuxChannelOn" 0 "AuxChannelOff" ;
VAL_ 2566838782 AuxI_O11 3 "NotAvailable" 2 "Error" 1 "AuxChannelOn" 0 "AuxChannelOff" ;
VAL_ 2566838782 AuxI_O10 3 "NotAvailable" 2 "Error" 1 "AuxChannelOn" 0 "AuxChannelOff" ;
VAL_ 2566838782 AuxI_O09 3 "NotAvailable" 2 "Error" 1 "AuxChannelOn" 0 "AuxChannelOff" ;
VAL_ 2566838782 AuxI_O08 3 "NotAvailable" 2 "Error" 1 "AuxChannelOn" 0 "AuxChannelOff" ;
VAL_ 2566838782 AuxI_O07 3 "NotAvailable" 2 "Error" 1 "AuxChannelOn" 0 "AuxChannelOff" ;
VAL_ 2566838782 AuxI_O06 3 "NotAvailable" 2 "Error" 1 "AuxChannelOn" 0 "AuxChannelOff" ;
VAL_ 2566838782 AuxI_O05 3 "NotAvailable" 2 "Error" 1 "AuxChannelOn" 0 "AuxChannelOff" ;
VAL_ 2566838782 AuxI_O04 3 "NotAvailable" 2 "Error" 1 "AuxChannelOn" 0 "AuxChannelOff" ;
VAL_ 2566838782 AuxI_O03 3 "NotAvailable" 2 "Error" 1 "AuxChannelOn" 0 "AuxChannelOff" ;
VAL_ 2566838782 AuxI_O02 3 "NotAvailable" 2 "Error" 1 "AuxChannelOn" 0 "AuxChannelOff" ;
VAL_ 2566838782 AuxI_O01 3 "NotAvailable" 2 "Error" 1 "AuxChannelOn" 0 "AuxChannelOff" ;
VAL_ 2561146622 AuxI_O45 3 "NtAvlblTkNoActionDependingOnApp" 2 "ErrrIndctrNotUsedDependingOnApp" 1 "AuxChannelOn" 0 "AuxChannelOff" ;
VAL_ 2561146622 AuxI_O46 3 "NtAvlblTkNoActionDependingOnApp" 2 "ErrrIndctrNotUsedDependingOnApp" 1 "AuxChannelOn" 0 "AuxChannelOff" ;
VAL_ 2561146622 AuxI_O47 3 "NtAvlblTkNoActionDependingOnApp" 2 "ErrrIndctrNotUsedDependingOnApp" 1 "AuxChannelOn" 0 "AuxChannelOff" ;
VAL_ 2561146622 AuxI_O48 3 "NtAvlblTkNoActionDependingOnApp" 2 "ErrrIndctrNotUsedDependingOnApp" 1 "AuxChannelOn" 0 "AuxChannelOff" ;
VAL_ 2561146622 AuxI_O41 3 "NtAvlblTkNoActionDependingOnApp" 2 "ErrrIndctrNotUsedDependingOnApp" 1 "AuxChannelOn" 0 "AuxChannelOff" ;
VAL_ 2561146622 AuxI_O42 3 "NtAvlblTkNoActionDependingOnApp" 2 "ErrrIndctrNotUsedDependingOnApp" 1 "AuxChannelOn" 0 "AuxChannelOff" ;
VAL_ 2561146622 AuxI_O43 3 "NtAvlblTkNoActionDependingOnApp" 2 "ErrrIndctrNotUsedDependingOnApp" 1 "AuxChannelOn" 0 "AuxChannelOff" ;
VAL_ 2561146622 AuxI_O44 3 "NtAvlblTkNoActionDependingOnApp" 2 "ErrrIndctrNotUsedDependingOnApp" 1 "AuxChannelOn" 0 "AuxChannelOff" ;
VAL_ 2561146622 AuxI_O37 3 "NtAvlblTkNoActionDependingOnApp" 2 "ErrrIndctrNotUsedDependingOnApp" 1 "AuxChannelOn" 0 "AuxChannelOff" ;
VAL_ 2561146622 AuxI_O38 3 "NtAvlblTkNoActionDependingOnApp" 2 "ErrrIndctrNotUsedDependingOnApp" 1 "AuxChannelOn" 0 "AuxChannelOff" ;
VAL_ 2561146622 AuxI_O39 3 "NtAvlblTkNoActionDependingOnApp" 2 "ErrrIndctrNotUsedDependingOnApp" 1 "AuxChannelOn" 0 "AuxChannelOff" ;
VAL_ 2561146622 AuxI_O40 3 "NtAvlblTkNoActionDependingOnApp" 2 "ErrrIndctrNotUsedDependingOnApp" 1 "AuxChannelOn" 0 "AuxChannelOff" ;
VAL_ 2561146622 AuxI_O33 3 "NtAvlblTkNoActionDependingOnApp" 2 "ErrrIndctrNotUsedDependingOnApp" 1 "AuxChannelOn" 0 "AuxChannelOff" ;
VAL_ 2561146622 AuxI_O34 3 "NtAvlblTkNoActionDependingOnApp" 2 "ErrrIndctrNotUsedDependingOnApp" 1 "AuxChannelOn" 0 "AuxChannelOff" ;
VAL_ 2561146622 AuxI_O35 3 "NtAvlblTkNoActionDependingOnApp" 2 "ErrrIndctrNotUsedDependingOnApp" 1 "AuxChannelOn" 0 "AuxChannelOff" ;
VAL_ 2561146622 AuxI_O36 3 "NtAvlblTkNoActionDependingOnApp" 2 "ErrrIndctrNotUsedDependingOnApp" 1 "AuxChannelOn" 0 "AuxChannelOff" ;
VAL_ 2561146622 AuxI_O29 3 "NtAvlblTkNoActionDependingOnApp" 2 "ErrrIndctrNotUsedDependingOnApp" 1 "AuxChannelOn" 0 "AuxChannelOff" ;
VAL_ 2561146622 AuxI_O30 3 "NtAvlblTkNoActionDependingOnApp" 2 "ErrrIndctrNotUsedDependingOnApp" 1 "AuxChannelOn" 0 "AuxChannelOff" ;
VAL_ 2561146622 AuxI_O31 3 "NtAvlblTkNoActionDependingOnApp" 2 "ErrrIndctrNotUsedDependingOnApp" 1 "AuxChannelOn" 0 "AuxChannelOff" ;
VAL_ 2561146622 AuxI_O32 3 "NtAvlblTkNoActionDependingOnApp" 2 "ErrrIndctrNotUsedDependingOnApp" 1 "AuxChannelOn" 0 "AuxChannelOff" ;
VAL_ 2561146622 AuxI_O25 3 "NtAvlblTkNoActionDependingOnApp" 2 "ErrrIndctrNotUsedDependingOnApp" 1 "AuxChannelOn" 0 "AuxChannelOff" ;
VAL_ 2561146622 AuxI_O26 3 "NtAvlblTkNoActionDependingOnApp" 2 "ErrrIndctrNotUsedDependingOnApp" 1 "AuxChannelOn" 0 "AuxChannelOff" ;
VAL_ 2561146622 AuxI_O27 3 "NtAvlblTkNoActionDependingOnApp" 2 "ErrrIndctrNotUsedDependingOnApp" 1 "AuxChannelOn" 0 "AuxChannelOff" ;
VAL_ 2561146622 AuxI_O28 3 "NtAvlblTkNoActionDependingOnApp" 2 "ErrrIndctrNotUsedDependingOnApp" 1 "AuxChannelOn" 0 "AuxChannelOff" ;
VAL_ 2561146622 AuxI_O21 3 "NtAvlblTkNoActionDependingOnApp" 2 "ErrrIndctrNotUsedDependingOnApp" 1 "AuxChannelOn" 0 "AuxChannelOff" ;
VAL_ 2561146622 AuxI_O22 3 "NtAvlblTkNoActionDependingOnApp" 2 "ErrrIndctrNotUsedDependingOnApp" 1 "AuxChannelOn" 0 "AuxChannelOff" ;
VAL_ 2561146622 AuxI_O23 3 "NtAvlblTkNoActionDependingOnApp" 2 "ErrrIndctrNotUsedDependingOnApp" 1 "AuxChannelOn" 0 "AuxChannelOff" ;
VAL_ 2561146622 AuxI_O24 3 "NtAvlblTkNoActionDependingOnApp" 2 "ErrrIndctrNotUsedDependingOnApp" 1 "AuxChannelOn" 0 "AuxChannelOff" ;
VAL_ 2561146622 AuxI_O17 3 "NtAvlblTkNoActionDependingOnApp" 2 "ErrrIndctrNotUsedDependingOnApp" 1 "AuxChannelOn" 0 "AuxChannelOff" ;
VAL_ 2561146622 AuxI_O18 3 "NtAvlblTkNoActionDependingOnApp" 2 "ErrrIndctrNotUsedDependingOnApp" 1 "AuxChannelOn" 0 "AuxChannelOff" ;
VAL_ 2561146622 AuxI_O19 3 "NtAvlblTkNoActionDependingOnApp" 2 "ErrrIndctrNotUsedDependingOnApp" 1 "AuxChannelOn" 0 "AuxChannelOff" ;
VAL_ 2561146622 AuxI_O20 3 "NtAvlblTkNoActionDependingOnApp" 2 "ErrrIndctrNotUsedDependingOnApp" 1 "AuxChannelOn" 0 "AuxChannelOff" ;
VAL_ 2561081086 AuxI_O77 3 "NtAvlblTkNoActionDependingOnApp" 2 "ErrrIndctrNotUsedDependingOnApp" 1 "AuxChannelOn" 0 "AuxChannelOff" ;
VAL_ 2561081086 AuxI_O78 3 "NtAvlblTkNoActionDependingOnApp" 2 "ErrrIndctrNotUsedDependingOnApp" 1 "AuxChannelOn" 0 "AuxChannelOff" ;
VAL_ 2561081086 AuxI_O79 3 "NtAvlblTkNoActionDependingOnApp" 2 "ErrrIndctrNotUsedDependingOnApp" 1 "AuxChannelOn" 0 "AuxChannelOff" ;
VAL_ 2561081086 AuxI_O80 3 "NtAvlblTkNoActionDependingOnApp" 2 "ErrrIndctrNotUsedDependingOnApp" 1 "AuxChannelOn" 0 "AuxChannelOff" ;
VAL_ 2561081086 AuxI_O73 3 "NtAvlblTkNoActionDependingOnApp" 2 "ErrrIndctrNotUsedDependingOnApp" 1 "AuxChannelOn" 0 "AuxChannelOff" ;
VAL_ 2561081086 AuxI_O74 3 "NtAvlblTkNoActionDependingOnApp" 2 "ErrrIndctrNotUsedDependingOnApp" 1 "AuxChannelOn" 0 "AuxChannelOff" ;
VAL_ 2561081086 AuxI_O75 3 "NtAvlblTkNoActionDependingOnApp" 2 "ErrrIndctrNotUsedDependingOnApp" 1 "AuxChannelOn" 0 "AuxChannelOff" ;
VAL_ 2561081086 AuxI_O76 3 "NtAvlblTkNoActionDependingOnApp" 2 "ErrrIndctrNotUsedDependingOnApp" 1 "AuxChannelOn" 0 "AuxChannelOff" ;
VAL_ 2561081086 AuxI_O69 3 "NtAvlblTkNoActionDependingOnApp" 2 "ErrrIndctrNotUsedDependingOnApp" 1 "AuxChannelOn" 0 "AuxChannelOff" ;
VAL_ 2561081086 AuxI_O70 3 "NtAvlblTkNoActionDependingOnApp" 2 "ErrrIndctrNotUsedDependingOnApp" 1 "AuxChannelOn" 0 "AuxChannelOff" ;
VAL_ 2561081086 AuxI_O71 3 "NtAvlblTkNoActionDependingOnApp" 2 "ErrrIndctrNotUsedDependingOnApp" 1 "AuxChannelOn" 0 "AuxChannelOff" ;
VAL_ 2561081086 AuxI_O72 3 "NtAvlblTkNoActionDependingOnApp" 2 "ErrrIndctrNotUsedDependingOnApp" 1 "AuxChannelOn" 0 "AuxChannelOff" ;
VAL_ 2561081086 AuxI_O65 3 "NtAvlblTkNoActionDependingOnApp" 2 "ErrrIndctrNotUsedDependingOnApp" 1 "AuxChannelOn" 0 "AuxChannelOff" ;
VAL_ 2561081086 AuxI_O66 3 "NtAvlblTkNoActionDependingOnApp" 2 "ErrrIndctrNotUsedDependingOnApp" 1 "AuxChannelOn" 0 "AuxChannelOff" ;
VAL_ 2561081086 AuxI_O67 3 "NtAvlblTkNoActionDependingOnApp" 2 "ErrrIndctrNotUsedDependingOnApp" 1 "AuxChannelOn" 0 "AuxChannelOff" ;
VAL_ 2561081086 AuxI_O68 3 "NtAvlblTkNoActionDependingOnApp" 2 "ErrrIndctrNotUsedDependingOnApp" 1 "AuxChannelOn" 0 "AuxChannelOff" ;
VAL_ 2561081086 AuxI_O61 3 "NtAvlblTkNoActionDependingOnApp" 2 "ErrrIndctrNotUsedDependingOnApp" 1 "AuxChannelOn" 0 "AuxChannelOff" ;
VAL_ 2561081086 AuxI_O62 3 "NtAvlblTkNoActionDependingOnApp" 2 "ErrrIndctrNotUsedDependingOnApp" 1 "AuxChannelOn" 0 "AuxChannelOff" ;
VAL_ 2561081086 AuxI_O63 3 "NtAvlblTkNoActionDependingOnApp" 2 "ErrrIndctrNotUsedDependingOnApp" 1 "AuxChannelOn" 0 "AuxChannelOff" ;
VAL_ 2561081086 AuxI_O64 3 "NtAvlblTkNoActionDependingOnApp" 2 "ErrrIndctrNotUsedDependingOnApp" 1 "AuxChannelOn" 0 "AuxChannelOff" ;
VAL_ 2561081086 AuxI_O57 3 "NtAvlblTkNoActionDependingOnApp" 2 "ErrrIndctrNotUsedDependingOnApp" 1 "AuxChannelOn" 0 "AuxChannelOff" ;
VAL_ 2561081086 AuxI_O58 3 "NtAvlblTkNoActionDependingOnApp" 2 "ErrrIndctrNotUsedDependingOnApp" 1 "AuxChannelOn" 0 "AuxChannelOff" ;
VAL_ 2561081086 AuxI_O59 3 "NtAvlblTkNoActionDependingOnApp" 2 "ErrrIndctrNotUsedDependingOnApp" 1 "AuxChannelOn" 0 "AuxChannelOff" ;
VAL_ 2561081086 AuxI_O60 3 "NtAvlblTkNoActionDependingOnApp" 2 "ErrrIndctrNotUsedDependingOnApp" 1 "AuxChannelOn" 0 "AuxChannelOff" ;
VAL_ 2561081086 AuxI_O53 3 "NtAvlblTkNoActionDependingOnApp" 2 "ErrrIndctrNotUsedDependingOnApp" 1 "AuxChannelOn" 0 "AuxChannelOff" ;
VAL_ 2561081086 AuxI_O54 3 "NtAvlblTkNoActionDependingOnApp" 2 "ErrrIndctrNotUsedDependingOnApp" 1 "AuxChannelOn" 0 "AuxChannelOff" ;
VAL_ 2561081086 AuxI_O55 3 "NtAvlblTkNoActionDependingOnApp" 2 "ErrrIndctrNotUsedDependingOnApp" 1 "AuxChannelOn" 0 "AuxChannelOff" ;
VAL_ 2561081086 AuxI_O56 3 "NtAvlblTkNoActionDependingOnApp" 2 "ErrrIndctrNotUsedDependingOnApp" 1 "AuxChannelOn" 0 "AuxChannelOff" ;
VAL_ 2561081086 AuxI_O49 3 "NtAvlblTkNoActionDependingOnApp" 2 "ErrrIndctrNotUsedDependingOnApp" 1 "AuxChannelOn" 0 "AuxChannelOff" ;
VAL_ 2561081086 AuxI_O50 3 "NtAvlblTkNoActionDependingOnApp" 2 "ErrrIndctrNotUsedDependingOnApp" 1 "AuxChannelOn" 0 "AuxChannelOff" ;
VAL_ 2561081086 AuxI_O51 3 "NtAvlblTkNoActionDependingOnApp" 2 "ErrrIndctrNotUsedDependingOnApp" 1 "AuxChannelOn" 0 "AuxChannelOff" ;
VAL_ 2561081086 AuxI_O52 3 "NtAvlblTkNoActionDependingOnApp" 2 "ErrrIndctrNotUsedDependingOnApp" 1 "AuxChannelOn" 0 "AuxChannelOff" ;
VAL_ 2561015550 AuxI_O92 3 "NtAvlblTkNoActionDependingOnApp" 2 "ErrrIndctrNotUsedDependingOnApp" 1 "AuxChannelOn" 0 "AuxChannelOff" ;
VAL_ 2561015550 AuxI_O85 3 "NtAvlblTkNoActionDependingOnApp" 2 "ErrrIndctrNotUsedDependingOnApp" 1 "AuxChannelOn" 0 "AuxChannelOff" ;
VAL_ 2561015550 AuxI_O86 3 "NtAvlblTkNoActionDependingOnApp" 2 "ErrrIndctrNotUsedDependingOnApp" 1 "AuxChannelOn" 0 "AuxChannelOff" ;
VAL_ 2561015550 AuxI_O87 3 "NtAvlblTkNoActionDependingOnApp" 2 "ErrrIndctrNotUsedDependingOnApp" 1 "AuxChannelOn" 0 "AuxChannelOff" ;
VAL_ 2561015550 AuxI_O88 3 "NtAvlblTkNoActionDependingOnApp" 2 "ErrrIndctrNotUsedDependingOnApp" 1 "AuxChannelOn" 0 "AuxChannelOff" ;
VAL_ 2561015550 AuxI_O81 3 "NtAvlblTkNoActionDependingOnApp" 2 "ErrrIndctrNotUsedDependingOnApp" 1 "AuxChannelOn" 0 "AuxChannelOff" ;
VAL_ 2561015550 AuxI_O82 3 "NtAvlblTkNoActionDependingOnApp" 2 "ErrrIndctrNotUsedDependingOnApp" 1 "AuxChannelOn" 0 "AuxChannelOff" ;
VAL_ 2561015550 AuxI_O83 3 "NtAvlblTkNoActionDependingOnApp" 2 "ErrrIndctrNotUsedDependingOnApp" 1 "AuxChannelOn" 0 "AuxChannelOff" ;
VAL_ 2561015550 AuxI_O84 3 "NtAvlblTkNoActionDependingOnApp" 2 "ErrrIndctrNotUsedDependingOnApp" 1 "AuxChannelOn" 0 "AuxChannelOff" ;
VAL_ 2561015550 AuxI_O109 3 "NtAvlblTkNoActionDependingOnApp" 2 "ErrrIndctrNotUsedDependingOnApp" 1 "AuxChannelOn" 0 "AuxChannelOff" ;
VAL_ 2561015550 AuxI_O110 3 "NtAvlblTkNoActionDependingOnApp" 2 "ErrrIndctrNotUsedDependingOnApp" 1 "AuxChannelOn" 0 "AuxChannelOff" ;
VAL_ 2561015550 AuxI_O111 3 "NtAvlblTkNoActionDependingOnApp" 2 "ErrrIndctrNotUsedDependingOnApp" 1 "AuxChannelOn" 0 "AuxChannelOff" ;
VAL_ 2561015550 AuxI_O112 3 "NtAvlblTkNoActionDependingOnApp" 2 "ErrrIndctrNotUsedDependingOnApp" 1 "AuxChannelOn" 0 "AuxChannelOff" ;
VAL_ 2561015550 AuxI_O105 3 "NtAvlblTkNoActionDependingOnApp" 2 "ErrrIndctrNotUsedDependingOnApp" 1 "AuxChannelOn" 0 "AuxChannelOff" ;
VAL_ 2561015550 AuxI_O106 3 "NtAvlblTkNoActionDependingOnApp" 2 "ErrrIndctrNotUsedDependingOnApp" 1 "AuxChannelOn" 0 "AuxChannelOff" ;
VAL_ 2561015550 AuxI_O107 3 "NtAvlblTkNoActionDependingOnApp" 2 "ErrrIndctrNotUsedDependingOnApp" 1 "AuxChannelOn" 0 "AuxChannelOff" ;
VAL_ 2561015550 AuxI_O108 3 "NtAvlblTkNoActionDependingOnApp" 2 "ErrrIndctrNotUsedDependingOnApp" 1 "AuxChannelOn" 0 "AuxChannelOff" ;
VAL_ 2561015550 AuxI_O101 2 "ErrrIndctrNotUsedDependingOnApp" 1 "AuxChannelOn" 0 "AuxChannelOff" 3 "NtAvlblTkNoActionDependingOnApp" ;
VAL_ 2561015550 AuxI_O102 3 "NtAvlblTkNoActionDependingOnApp" 2 "ErrrIndctrNotUsedDependingOnApp" 1 "AuxChannelOn" 0 "AuxChannelOff" ;
VAL_ 2561015550 AuxI_O103 3 "NtAvlblTkNoActionDependingOnApp" 2 "ErrrIndctrNotUsedDependingOnApp" 1 "AuxChannelOn" 0 "AuxChannelOff" ;
VAL_ 2561015550 AuxI_O104 3 "NtAvlblTkNoActionDependingOnApp" 2 "ErrrIndctrNotUsedDependingOnApp" 1 "AuxChannelOn" 0 "AuxChannelOff" ;
VAL_ 2561015550 AuxI_O97 3 "NtAvlblTkNoActionDependingOnApp" 2 "ErrrIndctrNotUsedDependingOnApp" 1 "AuxChannelOn" 0 "AuxChannelOff" ;
VAL_ 2561015550 AuxI_O98 3 "NtAvlblTkNoActionDependingOnApp" 2 "ErrrIndctrNotUsedDependingOnApp" 1 "AuxChannelOn" 0 "AuxChannelOff" ;
VAL_ 2561015550 AuxI_O99 3 "NtAvlblTkNoActionDependingOnApp" 2 "ErrrIndctrNotUsedDependingOnApp" 1 "AuxChannelOn" 0 "AuxChannelOff" ;
VAL_ 2561015550 AuxI_O100 3 "NtAvlblTkNoActionDependingOnApp" 2 "ErrrIndctrNotUsedDependingOnApp" 1 "AuxChannelOn" 0 "AuxChannelOff" ;
VAL_ 2561015550 AuxI_O93 3 "NtAvlblTkNoActionDependingOnApp" 2 "ErrrIndctrNotUsedDependingOnApp" 1 "AuxChannelOn" 0 "AuxChannelOff" ;
VAL_ 2561015550 AuxI_O94 3 "NtAvlblTkNoActionDependingOnApp" 2 "ErrrIndctrNotUsedDependingOnApp" 1 "AuxChannelOn" 0 "AuxChannelOff" ;
VAL_ 2561015550 AuxI_O95 3 "NtAvlblTkNoActionDependingOnApp" 2 "ErrrIndctrNotUsedDependingOnApp" 1 "AuxChannelOn" 0 "AuxChannelOff" ;
VAL_ 2561015550 AuxI_O96 3 "NtAvlblTkNoActionDependingOnApp" 2 "ErrrIndctrNotUsedDependingOnApp" 1 "AuxChannelOn" 0 "AuxChannelOff" ;
VAL_ 2561015550 AuxI_O89 3 "NtAvlblTkNoActionDependingOnApp" 2 "ErrrIndctrNotUsedDependingOnApp" 1 "AuxChannelOn" 0 "AuxChannelOff" ;
VAL_ 2561015550 AuxI_O90 3 "NtAvlblTkNoActionDependingOnApp" 2 "ErrrIndctrNotUsedDependingOnApp" 1 "AuxChannelOn" 0 "AuxChannelOff" ;
VAL_ 2561015550 AuxI_O91 3 "NtAvlblTkNoActionDependingOnApp" 2 "ErrrIndctrNotUsedDependingOnApp" 1 "AuxChannelOn" 0 "AuxChannelOff" ;
VAL_ 2566746622 TrailerBrakeStrokeAxle5Right 7 "NotAvailable" 6 "SensorError" 5 "Reserved" 3 "DraggingBrake" 2 "Overstroke" 1 "Nonfunctioning" 0 "OK" ;
VAL_ 2566746622 TrailerBrakeStrokeAxle5Left 7 "NotAvailable" 6 "SensorError" 5 "Reserved" 3 "DraggingBrake" 2 "Overstroke" 1 "Nonfunctioning" 0 "OK" ;
VAL_ 2566746622 TrailerBrakeStrokeAxle4Right 7 "NotAvailable" 6 "SensorError" 5 "Reserved" 3 "DraggingBrake" 2 "Overstroke" 1 "Nonfunctioning" 0 "OK" ;
VAL_ 2566746622 TrailerBrakeStrokeAxle4Left 7 "NotAvailable" 6 "SensorError" 5 "Reserved" 3 "DraggingBrake" 2 "Overstroke" 1 "Nonfunctioning" 0 "OK" ;
VAL_ 2566746622 TrailerBrakeStrokeAxle3Right 7 "NotAvailable" 6 "SensorError" 5 "Reserved" 3 "DraggingBrake" 2 "Overstroke" 1 "Nonfunctioning" 0 "OK" ;
VAL_ 2566746622 TrailerBrakeStrokeAxle3Left 7 "NotAvailable" 6 "SensorError" 5 "Reserved" 3 "DraggingBrake" 2 "Overstroke" 1 "Nonfunctioning" 0 "OK" ;
VAL_ 2566746622 TrailerBrakeStrokeAxle2Right 7 "NotAvailable" 6 "SensorError" 5 "Reserved" 3 "DraggingBrake" 2 "Overstroke" 1 "Nonfunctioning" 0 "OK" ;
VAL_ 2566746622 TrailerBrakeStrokeAxle2Left 7 "NotAvailable" 6 "SensorError" 5 "Reserved" 3 "DraggingBrake" 2 "Overstroke" 1 "Nonfunctioning" 0 "OK" ;
VAL_ 2566746622 TrailerBrakeStrokeAxle1Right 7 "NotAvailable" 6 "SensorError" 5 "Reserved" 3 "DraggingBrake" 2 "Overstroke" 1 "Nonfunctioning" 0 "OK" ;
VAL_ 2566746622 TrailerBrakeStrokeAxle1Left 7 "NotAvailable" 6 "SensorError" 5 "Reserved" 3 "DraggingBrake" 2 "Overstroke" 1 "Nonfunctioning" 0 "OK" ;
VAL_ 2566746622 TractorBrakeStrokeAxle5Right 7 "NotAvailable" 6 "SensorError" 5 "Reserved" 3 "DraggingBrake" 2 "Overstroke" 1 "Nonfunctioning" 0 "OK" ;
VAL_ 2566746622 TractorBrakeStrokeAxle5Left 7 "NotAvailable" 6 "SensorError" 5 "Reserved" 3 "DraggingBrake" 2 "Overstroke" 1 "Nonfunctioning" 0 "OK" ;
VAL_ 2566746622 TractorBrakeStrokeAxle4Right 7 "NotAvailable" 6 "SensorError" 5 "Reserved" 3 "DraggingBrake" 2 "Overstroke" 1 "Nonfunctioning" 0 "OK" ;
VAL_ 2566746622 TractorBrakeStrokeAxle4Left 7 "NotAvailable" 6 "SensorError" 5 "Reserved" 3 "DraggingBrake" 2 "Overstroke" 1 "Nonfunctioning" 0 "OK" ;
VAL_ 2566746622 TractorBrakeStrokeAxle3Right 7 "NotAvailable" 6 "SensorError" 5 "Reserved" 3 "DraggingBrake" 2 "Overstroke" 1 "Nonfunctioning" 0 "OK" ;
VAL_ 2566746622 TractorBrakeStrokeAxle3Left 7 "NotAvailable" 6 "SensorError" 5 "Reserved" 3 "DraggingBrake" 2 "Overstroke" 1 "Nonfunctioning" 0 "OK" ;
VAL_ 2566746622 TractorBrakeStrokeAxle2Right 7 "NotAvailable" 6 "SensorError" 5 "Reserved" 3 "DraggingBrake" 2 "Overstroke" 1 "Nonfunctioning" 0 "OK" ;
VAL_ 2566746622 TractorBrakeStrokeAxle2Left 7 "NotAvailable" 6 "SensorError" 5 "Reserved" 3 "DraggingBrake" 2 "Overstroke" 1 "Nonfunctioning" 0 "OK" ;
VAL_ 2566746622 TractorBrakeStrokeAxle1Right 7 "NotAvailable" 6 "SensorError" 5 "Reserved" 3 "DraggingBrake" 2 "Overstroke" 1 "Nonfunctioning" 0 "OK" ;
VAL_ 2566746622 TractorBrakeStrokeAxle1Left 7 "NotAvailable" 6 "SensorError" 5 "Reserved" 3 "DraggingBrake" 2 "Overstroke" 1 "Nonfunctioning" 0 "OK" ;
VAL_ 2566827774 AirCompressorStatus 3 "NotAvailable" 2 "ErrorIndicator" 1 "CompressorActive" 0 "CompressorNotActive" ;
VAL_ 2566803966 ACCUsageDemand 3 "dontCare" 2 "reserved" 1 "drvrDmndFrUsngACCDstncKpingCtrl" 0 "drvrDmndFrNtUsngACCDstncKpngCtr" ;
VAL_ 2566803966 RqedACCDistanceMode 7 "notAvailable" 6 "errorCondition" 5 "notDefined" 4 "RqedACCDistanceMode5" 3 "RqedACCDistanceMode4" 2 "RqedACCDistanceMode3" 1 "RqedACCDistanceMode2" 0 "RqedACCDistanceMode1" ;
VAL_ 2432593918 ForwardCollisionWarning 3 "notAvailable" 2 "ErrorIndicator" 1 "CollisionIsImminent" 0 "NoWarning" ;
VAL_ 2432593918 ACCDistanceAlertSignal 3 "TakeNoAction" 2 "Reserved" 1 "ACCDASActive" 0 "ACCDASNotActive" ;
VAL_ 2432593918 ACCSystemShutoffWarning 3 "TakeNoAction" 2 "Reserved" 1 "ACCSSOWActive" 0 "ACCSSOWNotActive" ;
VAL_ 2432593918 ACCTargetDetected 3 "TakeNoAction" 2 "Reserved" 1 "TargetDetected" 0 "NoTargetsDetected" ;
VAL_ 2432593918 AdptveCruiseCtrlSetDistanceMode 7 "NotAvailable_NotValid" 6 "ErrorCondition" 5 "ConventionalCruiseCtrlMode" 4 "ACCDistanceMode5" 3 "ACCDistanceMode4" 2 "ACCDistanceMode3" 1 "ACCDistanceMode2" 0 "ACCDistanceMode1" ;
VAL_ 2432593918 AdaptiveCruiseCtrlMode 7 "NotAvailable_NotValid" 6 "DsbldErrrCndtnUsdTIndctThtACCIs" 5 "FinishMode" 4 "HldMdUsdTIndctThtACCHsLstThPrvs" 3 "OvertakeMode" 2 "DstncCtrlActvUsdTIndctThtACCIsO" 1 "SpeedCtrlActive" 0 "OffUsdTIndctACCIsEnbldInClbCnfg" ;
VAL_ 2566803198 Status2OfDoors 3 "notAvailable" 2 "error" 1 "atLeast1BusDoorEnabled" 0 "allBusDoorsAreDisabled" ;
VAL_ 2566803198 Ramp_WheelChairLiftPos 3 "NotAvailable" 2 "Error" 1 "OutsideBus" 0 "InsideBus" ;
VAL_ 2566803198 PosOfDoors 15 "NotAvailable" 14 "Error" 3 "1101NotDefined" 2 "AllDoorsClosed" 1 "ClosingLastDoor" 0 "AtLeast1DoorIsOpen" ;
VAL_ 2565870334 FifthWheelRollWarningIndicator 3 "NotAvailable" 2 "error" 1 "LimitExceeded" 0 "LimitNotExceeded" ;
VAL_ 2566762238 FifthWheelSliderLockIndicator 3 "NotAvailable" 2 "Error" 1 "Locked" 0 "NotLocked" ;
VAL_ 2566762238 FfthWhlLckCoupleStatusIndicator 3 "NotAvailable" 2 "Error" 1 "SuccessfulCoupleDetected" 0 "IncmpltBdCplTrckShuldNotBeMoved" ;
VAL_ 2566762238 FfthWhlLckRadyToCoupleIndicator 3 "NotAvailable" 2 "Error" 1 "LockOpenReadyToCouple" 0 "LockNotOpenNotReadyToCouple" ;
VAL_ 2566762238 FifthWheelErrorStatus 15 "NotAvailable" 9 "Kingpin_LockOpen" 8 "KingpinMissingMoreThan5Seconds" 7 "CouplingTimingError" 6 "CouplingSequenceError_Kingpin" 5 "CouplingSequenceError" 14 "NotUsed" 2 "Kingpin_LocksOpenAtStartup" 1 "LocksClosed_NoKingpinAtStartup" 0 "ImproperCouple" ;
VAL_ 2364543998 PitchAndRollCompensated 1 "NotAvailable" 0 "CompensationOn" 3 "NotAvailable0" 2 "Error" ;
VAL_ 2364543998 PitchRateFigureOfMerit 1 "NotAvailable" 0 "PtchRtDgrddDtIsSspctDTEnvrnmntl" 3 "NotAvailable0" 2 "Error" ;
VAL_ 2364543998 RollAngleFigureOfMerit 1 "RollAngleDegraded" 0 "RollAngleFullyFunctional" 3 "NotAvailable0" 2 "Error" ;
VAL_ 2364543998 PitchAngleFigureOfMerit 1 "NotAvailable" 0 "PtchAnglDgrddDtIsSspctDTEnvrnmn" 3 "NotAvailable0" 2 "Error" ;
VAL_ 2566846718 TransOilLevelMeasurementStatus 15 "NotAvailable" 14 "Error" 13 "ConditionsNotValidOther" 12 "NotDefined" 9 "CnditionsNotValidNoRqForReading" 8 "CndtionsNotValidEngSpeedTooHigh" 7 "CnditionsNotValidEngSpeedTooLow" 6 "CndtionsNotValidVehicleNotLevel" 5 "CndtnsNtVldVhclMvngOtptShftSpdT" 4 "CndtnsNtVldTrnsFluidTempTooHigh" 3 "CndtnsNtVldTransFluidTempTooLow" 2 "ConditionsNotValidTransInGear" 1 "CndtnsNtVldSttlngTmrStllCntngDw" 0 "CndtnsVldFrTrnsOlLvlMeasurement" ;
VAL_ 2566846718 TransOilLevelCountdownTimer 15 "NotAvailable" 14 "Error" 13 "ThirteenMinutes" 12 "TwelveMinutes" 11 "ElevenMinutes" 10 "TenMinutes" 9 "NineMinutes" 8 "EightMinutes" 7 "SevenMinutes" 6 "SixMinutes" 5 "FiveMinutes" 4 "FourMinutes" 3 "ThreeMinutes" 2 "TwoMinutes" 1 "OneMinute" 0 "lessThan1Minute" ;
VAL_ 2566846718 TransOilLevelHigh_Low 251 "CondNotAcceptableForValidMeasure" ;
VAL_ 2566760702 WrlessCommunicationNetworkType2 1 "CellularNetwork2" 0 "CellularNetwork1" ;
VAL_ 2566760702 NetworkAntennaStatus2 1 "On" 0 "Off" ;
VAL_ 2566760702 NetworkServiceStatus2 1 "RoamingService" 0 "LocalService" ;
VAL_ 2566760702 NetworkTransceiverStatus2 1 "On" 0 "Off" ;
VAL_ 2566760958 WrlessCommunicationNetworkType1 1 "CellularNetwork2" 0 "CellularNetwork1" ;
VAL_ 2566760958 NetworkAntennaStatus1 1 "On" 0 "Off" ;
VAL_ 2566760958 NetworkServiceStatus1 1 "RoamingService" 0 "LocalService" ;
VAL_ 2566760958 NetworkTransceiverStatus1 1 "On" 0 "Off" ;
